VERSION ""

NS_ :

BS_:

BU_: PowertrainControlModule AtmosphericSensor SafetyRestraintSystem2 Aftertreatment_2_GasOutlet Aftertreatment_2_GasIntake DieselParticulateFilterControl Turbocharger SafetyRestraintSystem1 CabDisplay2 Aftertreatment_1_GasOutlet Aftertreatment_1_GasIntake OnBoardDataLogger OffBoardDiagnosticTool2 OffBoardDiagnosticTool1 FileServer ParkingBrakeController SeatController2 FanDriveController SteeringColumnUnit CommunicationUnitRadio CommunicationUnitSatellite CommunicationUnitCellular PropulsionBatteryCharger ChassisController2 ChassisController1 EngineValveControl AuxiliaryHeater2 AuxiliaryHeater1 ClutchUnit RampControl InformationSystem1 SuspensionSystemController2 OilSensor VehicleDynamicStability ExhaustEmissionController TransmissionDisplay2 TransmissionDisplay1 ClimateControl2 WaterPumpController RearAxleSteeringController LightingOperatorControl SeatController1 IgnitionController2 IgnitionController1 TirePressureController CabController2 CabController1 PneumaticSystemController SuspensionSystemController1 HydraulicPumpController EnduranceBrakingSystem RetarderExhaustEngine2 OnBoardDiagnosticUnit HeadwayController RetarderExhaustEngine1 CabDisplay1 ManagementComputer VirtualTerminal OffVehicleGateway PowerTakeOffFront HitchControl AuxiliaryValveControl BodyController TractorTrailerBridge1 StarterSystem ElectricalSystem VehicleSecurity VehicleNavigation AerodynamicControl ElectricalChargingSystem ClimateControl1 TripRecorder InstrumentCluster SuspensionDriveAxle2 SuspensionDriveAxle1 SuspensionSteerAxle SteeringController FuelSystem CruiseControl RetarderDriveline RetarderEngine BrakesDriveAxle2 BrakesDriveAxle1 BrakesSystemController BrakesSteerAxle AxleDrive2 AxleDrive1 AxleSteering PowerTakeOff ShiftConsoleSecondary ShiftConsolePrimary Transmission2 Transmission1 Engine2 Engine1

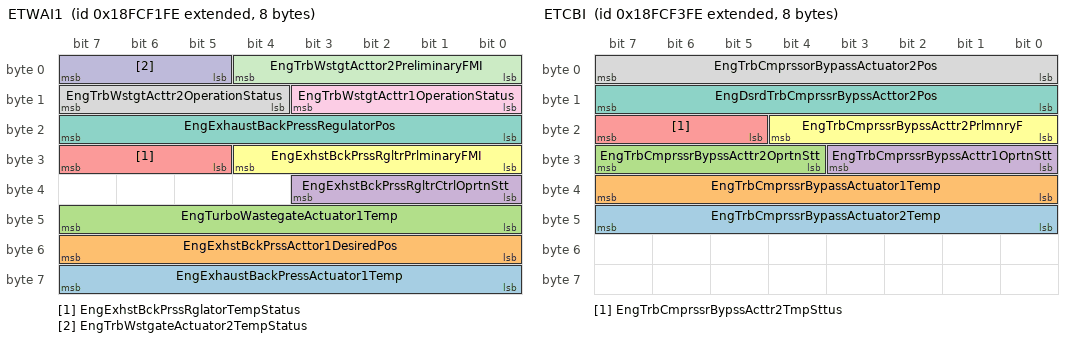
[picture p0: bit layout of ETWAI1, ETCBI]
BO_ 2566713854 ETWAI1: 8 Vector__XXX
 SG_ EngExhaustBackPressActuator1Temp : 56|8@1+ (1,-40) [-40|210] "°C" Vector__XXX
 SG_ EngExhstBckPrssActtor1DesiredPos : 48|8@1+ (0.4,0) [0|100] "%" Vector__XXX
 SG_ EngTurboWastegateActuator1Temp : 40|8@1+ (1,-40) [-40|210] "°C" Vector__XXX
 SG_ EngExhstBckPrssRgltrCtrlOprtnStt : 32|4@1+ (1,0) [0|15] "" Vector__XXX
 SG_ EngExhstBckPrssRglatorTempStatus : 29|3@1+ (1,0) [0|7] "" Vector__XXX
 SG_ EngExhstBckPrssRgltrPrlminaryFMI : 24|5@1+ (1,0) [0|31] "" Vector__XXX
 SG_ EngExhaustBackPressRegulatorPos : 16|8@1+ (0.4,0) [0|100] "%" Vector__XXX
 SG_ EngTrbWstgtActtr2OperationStatus : 12|4@1+ (1,0) [0|15] "" Vector__XXX
 SG_ EngTrbWstgtActtr1OperationStatus : 8|4@1+ (1,0) [0|15] "" Vector__XXX
 SG_ EngTrbWstgateActuator2TempStatus : 5|3@1+ (1,0) [0|7] "" Vector__XXX
 SG_ EngTrbWstgtActtor2PreliminaryFMI : 0|5@1+ (1,0) [0|31] "" Vector__XXX

BO_ 2566714366 ETCBI: 8 Vector__XXX
 SG_ EngTrbCmprssrBypassActuator2Temp : 40|8@1+ (1,-40) [-40|210] "°C" Vector__XXX
 SG_ EngTrbCmprssrBypassActuator1Temp : 32|8@1+ (1,-40) [-40|210] "°C" Vector__XXX
 SG_ EngTrbCmprssrBypssActtr2OprtnStt : 28|4@1+ (1,0) [0|15] "" Vector__XXX
 SG_ EngTrbCmprssrBypssActtr1OprtnStt : 24|4@1+ (1,0) [0|15] "" Vector__XXX
 SG_ EngTrbCmprssrBypssActtr2TmpSttus : 21|3@1+ (1,0) [0|7] "" Vector__XXX
 SG_ EngTrbCmprssrBypssActtr2PrlmnryF : 16|5@1+ (1,0) [0|31] "" Vector__XXX
 SG_ EngDsrdTrbCmprssrBypssActtor2Pos : 8|8@1+ (0.4,0) [0|100] "%" Vector__XXX
 SG_ EngTrbCmprssorBypassActuator2Pos : 0|8@1+ (0.4,0) [0|100] "%" Vector__XXX

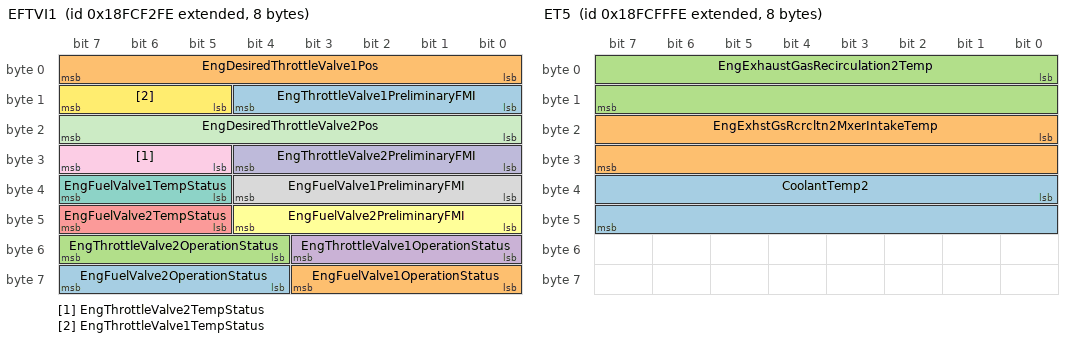
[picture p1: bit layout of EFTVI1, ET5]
BO_ 2566714110 EFTVI1: 8 Vector__XXX
 SG_ EngFuelValve2OperationStatus : 60|4@1+ (1,0) [0|15] "" Vector__XXX
 SG_ EngFuelValve1OperationStatus : 56|4@1+ (1,0) [0|15] "" Vector__XXX
 SG_ EngThrottleValve2OperationStatus : 52|4@1+ (1,0) [0|15] "" Vector__XXX
 SG_ EngThrottleValve1OperationStatus : 48|4@1+ (1,0) [0|15] "" Vector__XXX
 SG_ EngFuelValve2TempStatus : 45|3@1+ (1,0) [0|7] "" Vector__XXX
 SG_ EngFuelValve2PreliminaryFMI : 40|5@1+ (1,0) [0|31] "" Vector__XXX
 SG_ EngFuelValve1TempStatus : 37|3@1+ (1,0) [0|7] "" Vector__XXX
 SG_ EngFuelValve1PreliminaryFMI : 32|5@1+ (1,0) [0|31] "" Vector__XXX
 SG_ EngThrottleValve2TempStatus : 29|3@1+ (1,0) [0|7] "" Vector__XXX
 SG_ EngThrottleValve2PreliminaryFMI : 24|5@1+ (1,0) [0|31] "" Vector__XXX
 SG_ EngDesiredThrottleValve2Pos : 16|8@1+ (0.4,0) [0|100] "%" Vector__XXX
 SG_ EngThrottleValve1TempStatus : 13|3@1+ (1,0) [0|7] "" Vector__XXX
 SG_ EngThrottleValve1PreliminaryFMI : 8|5@1+ (1,0) [0|31] "" Vector__XXX
 SG_ EngDesiredThrottleValve1Pos : 0|8@1+ (0.4,0) [0|100] "%" Vector__XXX

BO_ 2566717438 ET5: 8 Vector__XXX
 SG_ CoolantTemp2 : 32|16@1+ (0.03125,-273) [-273|1734.96875] "°C" Vector__XXX
 SG_ EngExhstGsRcrcltn2MxerIntakeTemp : 16|16@1+ (0.03125,-273) [-273|1734.96875] "°C" Vector__XXX
 SG_ EngExhaustGasRecirculation2Temp : 0|16@1+ (0.03125,-273) [-273|1734.96875] "°C" Vector__XXX

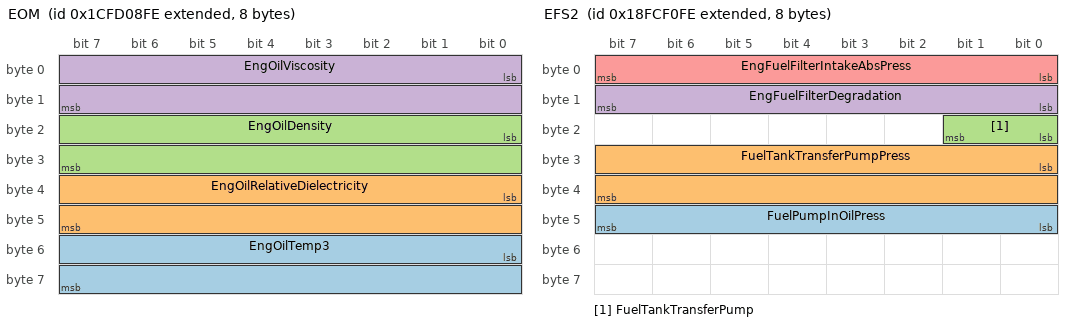
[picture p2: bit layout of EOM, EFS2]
BO_ 2633828606 EOM: 8 Vector__XXX
 SG_ EngOilTemp3 : 48|16@1+ (0.03125,-273) [-273|1734.96875] "°C" Vector__XXX
 SG_ EngOilRelativeDielectricity : 32|16@1+ (0.0001220703125,0) [0|7.8436279296875] "" Vector__XXX
 SG_ EngOilDensity : 16|16@1+ (3.052E-005,0) [0|1.9610626] "g/cc" Vector__XXX
 SG_ EngOilViscosity : 0|16@1+ (0.015625,0) [0|1003.984375] "cP" Vector__XXX

BO_ 2499607550 EMAP: 8 Vector__XXX
 SG_ EngExhstMnfldBnk2FlwBlncVlvActtr : 16|16@1+ (0.0025,0) [0|160.6375] "%" Vector__XXX
 SG_ EngExhstMnfldBnk1FlwBlncVlvActtr : 0|16@1+ (0.0025,0) [0|160.6375] "%" Vector__XXX

BO_ 2633825534 EMAC: 8 Vector__XXX
 SG_ EngExhstMnfldBnk2FlwBlncVlvActtr : 16|16@1+ (0.0025,0) [0|160.6375] "%" Vector__XXX
 SG_ EngExhstMnfldBnk1FlwBlncVlvActtr : 0|16@1+ (0.0025,0) [0|160.6375] "%" Vector__XXX

BO_ 2365400574 EJM9: 8 Vector__XXX
 SG_ Joystick9Button13PressedStatus : 62|2@1+ (1,0) [0|3] "" Vector__XXX
 SG_ Joystick9Button14PressedStatus : 60|2@1+ (1,0) [0|3] "" Vector__XXX
 SG_ Joystick9Button15PressedStatus : 58|2@1+ (1,0) [0|3] "" Vector__XXX
 SG_ Joystick9Button16PressedStatus : 56|2@1+ (1,0) [0|3] "" Vector__XXX
 SG_ Jystick9GripXAxisDetentPosStatus : 54|2@1+ (1,0) [0|3] "" Vector__XXX
 SG_ Jystick9GripYAxisDetentPosStatus : 52|2@1+ (1,0) [0|3] "" Vector__XXX
 SG_ Jystick9ThetaAxisDetentPosStatus : 50|2@1+ (1,0) [0|3] "" Vector__XXX
 SG_ Joystick9ThetaAxisPos : 38|10@1+ (0.1,0) [0|102] "%" Vector__XXX
 SG_ Jystck9ThtAxsClckwsPstvPosStatus : 36|2@1+ (1,0) [0|3] "" Vector__XXX
 SG_ Jystck9ThtAxsCntrClckwsNgtvPsStt : 34|2@1+ (1,0) [0|3] "" Vector__XXX
 SG_ Jystck9ThetaAxisNeutralPosStatus : 32|2@1+ (1,0) [0|3] "" Vector__XXX
 SG_ Joystick9GripYAxisPos : 22|10@1+ (0.1,0) [0|102] "%" Vector__XXX
 SG_ Jystck9GrpYAxsLvrFrwrdPstvPsStts : 20|2@1+ (1,0) [0|3] "" Vector__XXX
 SG_ Jystck9GrpYAxsLvrBckNgtvPsStatus : 18|2@1+ (1,0) [0|3] "" Vector__XXX
 SG_ Jystck9GripYAxisNeutralPosStatus : 16|2@1+ (1,0) [0|3] "" Vector__XXX
 SG_ Joystick9GripXAxisPos : 6|10@1+ (0.1,0) [0|102] "%" Vector__XXX
 SG_ Jystck9GrpXAxsLvrRghtPstvPsSttus : 4|2@1+ (1,0) [0|3] "" Vector__XXX
 SG_ Jystck9GrpXAxsLvrLftNgtvPsStatus : 2|2@1+ (1,0) [0|3] "" Vector__XXX
 SG_ Jystck9GripXAxisNeutralPosStatus : 0|2@1+ (1,0) [0|3] "" Vector__XXX

BO_ 2365401086 EJM8: 8 Vector__XXX
 SG_ Joystick8Button13PressedStatus : 62|2@1+ (1,0) [0|3] "" Vector__XXX
 SG_ Joystick8Button14PressedStatus : 60|2@1+ (1,0) [0|3] "" Vector__XXX
 SG_ Joystick8Button15PressedStatus : 58|2@1+ (1,0) [0|3] "" Vector__XXX
 SG_ Joystick8Button16PressedStatus : 56|2@1+ (1,0) [0|3] "" Vector__XXX
 SG_ Jystick8GripXAxisDetentPosStatus : 54|2@1+ (1,0) [0|3] "" Vector__XXX
 SG_ Jystick8GripYAxisDetentPosStatus : 52|2@1+ (1,0) [0|3] "" Vector__XXX
 SG_ Jystick8ThetaAxisDetentPosStatus : 50|2@1+ (1,0) [0|3] "" Vector__XXX
 SG_ Joystick8ThetaAxisPos : 38|10@1+ (0.1,0) [0|102] "%" Vector__XXX
 SG_ Jystck8ThtAxsClckwsPstvPosStatus : 36|2@1+ (1,0) [0|3] "" Vector__XXX
 SG_ Jystck8ThtAxsCntrClckwsNgtvPsStt : 34|2@1+ (1,0) [0|3] "" Vector__XXX
 SG_ Jystck8ThetaAxisNeutralPosStatus : 32|2@1+ (1,0) [0|3] "" Vector__XXX
 SG_ Joystick8GripYAxisPos : 22|10@1+ (0.1,0) [0|102] "%" Vector__XXX
 SG_ Jystck8GrpYAxsLvrFrwrdPstvPsStts : 20|2@1+ (1,0) [0|3] "" Vector__XXX
 SG_ Jystck8GrpYAxsLvrBckNgtvPsStatus : 18|2@1+ (1,0) [0|3] "" Vector__XXX
 SG_ Jystck8GripYAxisNeutralPosStatus : 16|2@1+ (1,0) [0|3] "" Vector__XXX
 SG_ Joystick8GripXAxisPos : 6|10@1+ (0.1,0) [0|102] "%" Vector__XXX
 SG_ Jystck8GrpXAxsLvrRghtPstvPsSttus : 4|2@1+ (1,0) [0|3] "" Vector__XXX
 SG_ Jystck8GrpXAxsLvrLftNgtvPsStatus : 2|2@1+ (1,0) [0|3] "" Vector__XXX
 SG_ Jystck8GripXAxisNeutralPosStatus : 0|2@1+ (1,0) [0|3] "" Vector__XXX

BO_ 2365401598 EJM7: 8 Vector__XXX
 SG_ Joystick7Button13PressedStatus : 62|2@1+ (1,0) [0|3] "" Vector__XXX
 SG_ Joystick7Button14PressedStatus : 60|2@1+ (1,0) [0|3] "" Vector__XXX
 SG_ Joystick7Button15PressedStatus : 58|2@1+ (1,0) [0|3] "" Vector__XXX
 SG_ Joystick7Button16PressedStatus : 56|2@1+ (1,0) [0|3] "" Vector__XXX
 SG_ Jystick7GripXAxisDetentPosStatus : 54|2@1+ (1,0) [0|3] "" Vector__XXX
 SG_ Jystick7GripYAxisDetentPosStatus : 52|2@1+ (1,0) [0|3] "" Vector__XXX
 SG_ Jystick7ThetaAxisDetentPosStatus : 50|2@1+ (1,0) [0|3] "" Vector__XXX
 SG_ Joystick7ThetaAxisPos : 38|10@1+ (0.1,0) [0|102] "%" Vector__XXX
 SG_ Jystck7ThtAxsClckwsPstvPosStatus : 36|2@1+ (1,0) [0|3] "" Vector__XXX
 SG_ Jystck7ThtAxsCntrClckwsNgtvPsStt : 34|2@1+ (1,0) [0|3] "" Vector__XXX
 SG_ Jystck7ThetaAxisNeutralPosStatus : 32|2@1+ (1,0) [0|3] "" Vector__XXX
 SG_ Joystick7GripYAxisPos : 22|10@1+ (0.1,0) [0|102] "%" Vector__XXX
 SG_ Jystck7GrpYAxsLvrFrwrdPstvPsStts : 20|2@1+ (1,0) [0|3] "" Vector__XXX
 SG_ Jystck7GrpYAxsLvrBckNgtvPsStatus : 18|2@1+ (1,0) [0|3] "" Vector__XXX
 SG_ Jystck7GripYAxisNeutralPosStatus : 16|2@1+ (1,0) [0|3] "" Vector__XXX
 SG_ Joystick7GripXAxisPos : 6|10@1+ (0.1,0) [0|102] "%" Vector__XXX
 SG_ Jystck7GrpXAxsLvrRghtPstvPsSttus : 4|2@1+ (1,0) [0|3] "" Vector__XXX
 SG_ Jystck7GrpXAxsLvrLftNgtvPsStatus : 2|2@1+ (1,0) [0|3] "" Vector__XXX
 SG_ Jystck7GripXAxisNeutralPosStatus : 0|2@1+ (1,0) [0|3] "" Vector__XXX

BO_ 2365402110 EJM6: 8 Vector__XXX
 SG_ Joystick6Button13PressedStatus : 62|2@1+ (1,0) [0|3] "" Vector__XXX
 SG_ Joystick6Button14PressedStatus : 60|2@1+ (1,0) [0|3] "" Vector__XXX
 SG_ Joystick6Button15PressedStatus : 58|2@1+ (1,0) [0|3] "" Vector__XXX
 SG_ Joystick6Button16PressedStatus : 56|2@1+ (1,0) [0|3] "" Vector__XXX
 SG_ Jystick6GripXAxisDetentPosStatus : 54|2@1+ (1,0) [0|3] "" Vector__XXX
 SG_ Jystick6GripYAxisDetentPosStatus : 52|2@1+ (1,0) [0|3] "" Vector__XXX
 SG_ Jystick6ThetaAxisDetentPosStatus : 50|2@1+ (1,0) [0|3] "" Vector__XXX
 SG_ Joystick6ThetaAxisPos : 38|10@1+ (0.1,0) [0|102] "%" Vector__XXX
 SG_ Jystck6ThtAxsClckwsPstvPosStatus : 36|2@1+ (1,0) [0|3] "" Vector__XXX
 SG_ Jystck6ThtAxsCntrClckwsNgtvPsStt : 34|2@1+ (1,0) [0|3] "" Vector__XXX
 SG_ Jystck6ThetaAxisNeutralPosStatus : 32|2@1+ (1,0) [0|3] "" Vector__XXX
 SG_ Joystick6GripYAxisPos : 22|10@1+ (0.1,0) [0|102] "%" Vector__XXX
 SG_ Jystck6GrpYAxsLvrFrwrdPstvPsStts : 20|2@1+ (1,0) [0|3] "" Vector__XXX
 SG_ Jystck6GrpYAxsLvrBckNgtvPsStatus : 18|2@1+ (1,0) [0|3] "" Vector__XXX
 SG_ Jystck6GripYAxisNeutralPosStatus : 16|2@1+ (1,0) [0|3] "" Vector__XXX
 SG_ Joystick6GripXAxisPos : 6|10@1+ (0.1,0) [0|102] "%" Vector__XXX
 SG_ Jystck6GrpXAxsLvrRghtPstvPsSttus : 4|2@1+ (1,0) [0|3] "" Vector__XXX
 SG_ Jystck6GrpXAxsLvrLftNgtvPsStatus : 2|2@1+ (1,0) [0|3] "" Vector__XXX
 SG_ Jystck6GripXAxisNeutralPosStatus : 0|2@1+ (1,0) [0|3] "" Vector__XXX

BO_ 2365402622 EJM5: 8 Vector__XXX
 SG_ Joystick5Button13PressedStatus : 62|2@1+ (1,0) [0|3] "" Vector__XXX
 SG_ Joystick5Button14PressedStatus : 60|2@1+ (1,0) [0|3] "" Vector__XXX
 SG_ Joystick5Button15PressedStatus : 58|2@1+ (1,0) [0|3] "" Vector__XXX
 SG_ Joystick5Button16PressedStatus : 56|2@1+ (1,0) [0|3] "" Vector__XXX
 SG_ Jystick5GripXAxisDetentPosStatus : 54|2@1+ (1,0) [0|3] "" Vector__XXX
 SG_ Jystick5GripYAxisDetentPosStatus : 52|2@1+ (1,0) [0|3] "" Vector__XXX
 SG_ Jystick5ThetaAxisDetentPosStatus : 50|2@1+ (1,0) [0|3] "" Vector__XXX
 SG_ Joystick5ThetaAxisPos : 38|10@1+ (0.1,0) [0|102] "%" Vector__XXX
 SG_ Jystck5ThtAxsClckwsPstvPosStatus : 36|2@1+ (1,0) [0|3] "" Vector__XXX
 SG_ Jystck5ThtAxsCntrClckwsNgtvPsStt : 34|2@1+ (1,0) [0|3] "" Vector__XXX
 SG_ Jystck5ThetaAxisNeutralPosStatus : 32|2@1+ (1,0) [0|3] "" Vector__XXX
 SG_ Joystick5GripYAxisPos : 22|10@1+ (0.1,0) [0|102] "%" Vector__XXX
 SG_ Jystck5GrpYAxsLvrFrwrdPstvPsStts : 20|2@1+ (1,0) [0|3] "" Vector__XXX
 SG_ Jystck5GrpYAxsLvrBckNgtvPsStatus : 18|2@1+ (1,0) [0|3] "" Vector__XXX
 SG_ Jystck5GripYAxisNeutralPosStatus : 16|2@1+ (1,0) [0|3] "" Vector__XXX
 SG_ Joystick5GripXAxisPos : 6|10@1+ (0.1,0) [0|102] "%" Vector__XXX
 SG_ Jystck5GrpXAxsLvrRghtPstvPsSttus : 4|2@1+ (1,0) [0|3] "" Vector__XXX
 SG_ Jystck5GrpXAxsLvrLftNgtvPsStatus : 2|2@1+ (1,0) [0|3] "" Vector__XXX
 SG_ Jystck5GripXAxisNeutralPosStatus : 0|2@1+ (1,0) [0|3] "" Vector__XXX

BO_ 2365403134 EJM4: 8 Vector__XXX
 SG_ Joystick4Button13PressedStatus : 62|2@1+ (1,0) [0|3] "" Vector__XXX
 SG_ Joystick4Button14PressedStatus : 60|2@1+ (1,0) [0|3] "" Vector__XXX
 SG_ Joystick4Button15PressedStatus : 58|2@1+ (1,0) [0|3] "" Vector__XXX
 SG_ Joystick4Button16PressedStatus : 56|2@1+ (1,0) [0|3] "" Vector__XXX
 SG_ Jystick4GripXAxisDetentPosStatus : 54|2@1+ (1,0) [0|3] "" Vector__XXX
 SG_ Jystick4GripYAxisDetentPosStatus : 52|2@1+ (1,0) [0|3] "" Vector__XXX
 SG_ Jystick4ThetaAxisDetentPosStatus : 50|2@1+ (1,0) [0|3] "" Vector__XXX
 SG_ Joystick4ThetaAxisPos : 38|10@1+ (0.1,0) [0|102] "%" Vector__XXX
 SG_ Jystck4ThtAxsClckwsPstvPosStatus : 36|2@1+ (1,0) [0|3] "" Vector__XXX
 SG_ Jystck4ThtAxsCntrClckwsNgtvPsStt : 34|2@1+ (1,0) [0|3] "" Vector__XXX
 SG_ Jystck4ThetaAxisNeutralPosStatus : 32|2@1+ (1,0) [0|3] "" Vector__XXX
 SG_ Joystick4GripYAxisPos : 22|10@1+ (0.1,0) [0|102] "%" Vector__XXX
 SG_ Jystck4GrpYAxsLvrFrwrdPstvPsStts : 20|2@1+ (1,0) [0|3] "" Vector__XXX
 SG_ Jystck4GrpYAxsLvrBckNgtvPsStatus : 18|2@1+ (1,0) [0|3] "" Vector__XXX
 SG_ Jystck4GripYAxisNeutralPosStatus : 16|2@1+ (1,0) [0|3] "" Vector__XXX
 SG_ Joystick4GripXAxisPos : 6|10@1+ (0.1,0) [0|102] "%" Vector__XXX
 SG_ Jystck4GrpXAxsLvrRghtPstvPsSttus : 4|2@1+ (1,0) [0|3] "" Vector__XXX
 SG_ Jystck4GrpXAxsLvrLftNgtvPsStatus : 2|2@1+ (1,0) [0|3] "" Vector__XXX
 SG_ Jystck4GripXAxisNeutralPosStatus : 0|2@1+ (1,0) [0|3] "" Vector__XXX

BO_ 2365400062 EJM10: 8 Vector__XXX
 SG_ Joystick10Button13PressedStatus : 62|2@1+ (1,0) [0|3] "" Vector__XXX
 SG_ Joystick10Button14PressedStatus : 60|2@1+ (1,0) [0|3] "" Vector__XXX
 SG_ Joystick10Button15PressedStatus : 58|2@1+ (1,0) [0|3] "" Vector__XXX
 SG_ Joystick10Button16PressedStatus : 56|2@1+ (1,0) [0|3] "" Vector__XXX
 SG_ Jystck10GripXAxisDetentPosStatus : 54|2@1+ (1,0) [0|3] "" Vector__XXX
 SG_ Jystck10GripYAxisDetentPosStatus : 52|2@1+ (1,0) [0|3] "" Vector__XXX
 SG_ Jystck10ThetaAxisDetentPosStatus : 50|2@1+ (1,0) [0|3] "" Vector__XXX
 SG_ Joystick10ThetaAxisPos : 38|10@1+ (0.1,0) [0|102] "%" Vector__XXX
 SG_ Jystck10ThtAxsClckwsPstvPsStatus : 36|2@1+ (1,0) [0|3] "" Vector__XXX
 SG_ Jystck10ThtAxsCntrClckwsNgtvPsSt : 34|2@1+ (1,0) [0|3] "" Vector__XXX
 SG_ Jystck10ThtaAxisNeutralPosStatus : 32|2@1+ (1,0) [0|3] "" Vector__XXX
 SG_ Joystick10GripYAxisPos : 22|10@1+ (0.1,0) [0|102] "%" Vector__XXX
 SG_ Jystck10GrpYAxsLvrFrwrdPstvPsStt : 20|2@1+ (1,0) [0|3] "" Vector__XXX
 SG_ Jystck10GrpYAxsLvrBckNgtvPsSttus : 18|2@1+ (1,0) [0|3] "" Vector__XXX
 SG_ Jystck10GrpYAxisNeutralPosStatus : 16|2@1+ (1,0) [0|3] "" Vector__XXX
 SG_ Joystick10GripXAxisPos : 6|10@1+ (0.1,0) [0|102] "%" Vector__XXX
 SG_ Jystck10GrpXAxsLvrRghtPstvPsStts : 4|2@1+ (1,0) [0|3] "" Vector__XXX
 SG_ Jystck10GrpXAxsLvrLftNgtvPsSttus : 2|2@1+ (1,0) [0|3] "" Vector__XXX
 SG_ Jystck10GrpXAxisNeutralPosStatus : 0|2@1+ (1,0) [0|3] "" Vector__XXX

BO_ 2566713598 EFS2: 8 Vector__XXX
 SG_ FuelPumpInOilPress : 40|8@1+ (4,0) [0|1000] "kPa" Vector__XXX
 SG_ FuelTankTransferPumpPress : 24|16@1+ (0.1,0) [0|6425.5] "kPa" Vector__XXX
 SG_ FuelTankTransferPump : 16|2@1+ (1,0) [0|3] "" Vector__XXX
 SG_ EngFuelFilterDegradation : 8|8@1+ (1,0) [0|250] "%" Vector__XXX
 SG_ EngFuelFilterIntakeAbsPress : 0|8@1+ (2,0) [0|500] "kPa" Vector__XXX

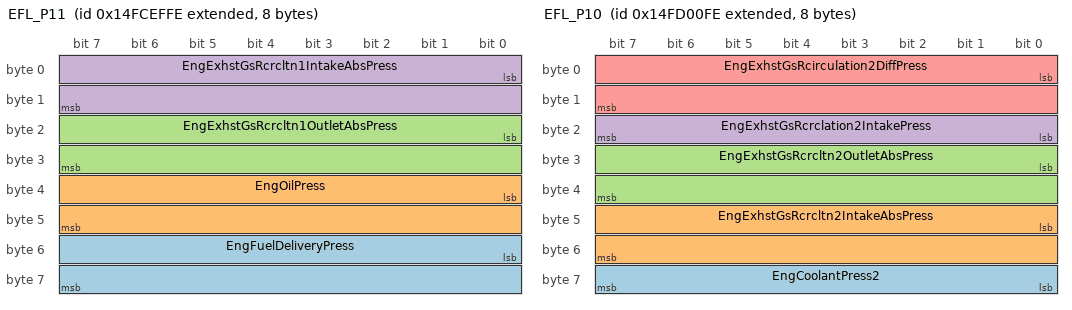
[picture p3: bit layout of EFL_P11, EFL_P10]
BO_ 2499604478 EFL_P11: 8 Vector__XXX
 SG_ EngFuelDeliveryPress : 48|16@1+ (0.1,0) [0|6425.5] "kPa" Vector__XXX
 SG_ EngOilPress : 32|16@1+ (0.1,0) [0|6425.5] "kPa" Vector__XXX
 SG_ EngExhstGsRcrcltn1OutletAbsPress : 16|16@1+ (0.1,0) [0|6425.5] "kPa" Vector__XXX
 SG_ EngExhstGsRcrcltn1IntakeAbsPress : 0|16@1+ (0.1,0) [0|6425.5] "kPa" Vector__XXX

BO_ 2499608830 EFL_P10: 8 Vector__XXX
 SG_ EngCoolantPress2 : 56|8@1+ (2,0) [0|500] "kPa" Vector__XXX
 SG_ EngExhstGsRcrcltn2IntakeAbsPress : 40|16@1+ (0.1,0) [0|6425.5] "kPa" Vector__XXX
 SG_ EngExhstGsRcrcltn2OutletAbsPress : 24|16@1+ (0.1,0) [0|6425.5] "kPa" Vector__XXX
 SG_ EngExhstGsRcrclation2IntakePress : 16|8@1+ (2,0) [0|500] "kPa" Vector__XXX
 SG_ EngExhstGsRcirculation2DiffPress : 0|16@1+ (0.0078125,-250) [-250|251.9921875] "kPa" Vector__XXX

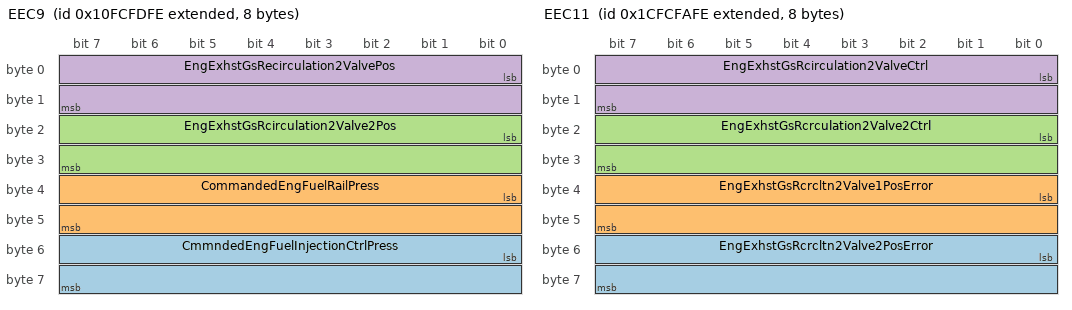
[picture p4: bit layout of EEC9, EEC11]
BO_ 2432499198 EEC9: 8 Vector__XXX
 SG_ CmmndedEngFuelInjectionCtrlPress : 48|16@1+ (0.00390625,0) [0|250.99609375] "MPa" Vector__XXX
 SG_ CommandedEngFuelRailPress : 32|16@1+ (0.00390625,0) [0|250.99609375] "MPa" Vector__XXX
 SG_ EngExhstGsRcirculation2Valve2Pos : 16|16@1+ (0.0025,0) [0|160.6375] "%" Vector__XXX
 SG_ EngExhstGsRecirculation2ValvePos : 0|16@1+ (0.0025,0) [0|160.6375] "%" Vector__XXX

BO_ 2633825022 EEC11: 8 Vector__XXX
 SG_ EngExhstGsRcrcltn2Valve2PosError : 48|16@1+ (0.004,-125) [-125|132.02] "%" Vector__XXX
 SG_ EngExhstGsRcrcltn2Valve1PosError : 32|16@1+ (0.004,-125) [-125|132.02] "%" Vector__XXX
 SG_ EngExhstGsRcrculation2Valve2Ctrl : 16|16@1+ (0.0025,0) [0|160.6375] "%" Vector__XXX
 SG_ EngExhstGsRcirculation2ValveCtrl : 0|16@1+ (0.0025,0) [0|160.6375] "%" Vector__XXX

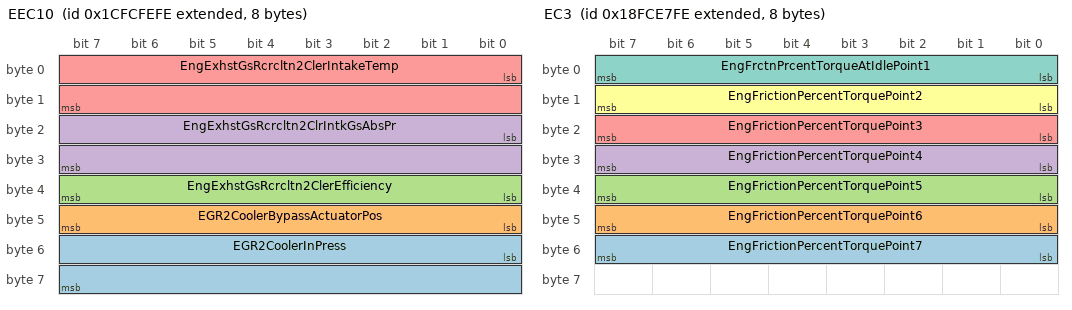
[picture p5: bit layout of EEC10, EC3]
BO_ 2633826046 EEC10: 8 Vector__XXX
 SG_ EGR2CoolerInPress : 48|16@1+ (5,0) [0|321275] "kPa" Vector__XXX
 SG_ EGR2CoolerBypassActuatorPos : 40|8@1+ (0.4,0) [0|100] "%" Vector__XXX
 SG_ EngExhstGsRcrcltn2ClerEfficiency : 32|8@1+ (0.4,0) [0|100] "%" Vector__XXX
 SG_ EngExhstGsRcrcltn2ClrIntkGsAbsPr : 16|16@1+ (0.5,0) [0|32127.5] "kPa" Vector__XXX
 SG_ EngExhstGsRcrcltn2ClerIntakeTemp : 0|16@1+ (0.03125,-273) [-273|1734.96875] "°C" Vector__XXX

BO_ 2566711294 EC3: 8 Vector__XXX
 SG_ EngFrictionPercentTorquePoint7 : 48|8@1+ (1,-125) [0|125] "%" Vector__XXX
 SG_ EngFrictionPercentTorquePoint6 : 40|8@1+ (1,-125) [0|125] "%" Vector__XXX
 SG_ EngFrictionPercentTorquePoint5 : 32|8@1+ (1,-125) [0|125] "%" Vector__XXX
 SG_ EngFrictionPercentTorquePoint4 : 24|8@1+ (1,-125) [0|125] "%" Vector__XXX
 SG_ EngFrictionPercentTorquePoint3 : 16|8@1+ (1,-125) [0|125] "%" Vector__XXX
 SG_ EngFrictionPercentTorquePoint2 : 8|8@1+ (1,-125) [0|125] "%" Vector__XXX
 SG_ EngFrctnPrcentTorqueAtIdlePoint1 : 0|8@1+ (1,-125) [0|125] "%" Vector__XXX

BO_ 2566749438 DPFC1: 8 Vector__XXX
 SG_ ActiveRegenInhibitedDueThresher : 62|2@1+ (1,0) [0|3] "" Vector__XXX
 SG_ ActiveRegenAvailabilityStatus : 3|2@1+ (1,0) [0|3] "" Vector__XXX
 SG_ DslPrtcltFltrActvRgnrtnInhbt5629 : 58|2@1+ (1,0) [0|3] "" Vector__XXX
 SG_ A1DPFCondNotMetForActiveRegen : 60|2@1+ (1,0) [0|3] "" Vector__XXX
 SG_ HydrocarbonDoserPurgingEnable : 56|2@1+ (1,0) [0|3] "" Vector__XXX
 SG_ DslPrtcltFltrActvRgnrtnFrcdSttus : 53|3@1+ (1,0) [0|7] "" Vector__XXX
 SG_ ExhaustSystemHighTempLampCmd : 50|3@1+ (1,0) [0|7] "" Vector__XXX
 SG_ DslPrtcltFltrAtmtcActvRgnrtnIntt : 48|2@1+ (1,0) [0|3] "" Vector__XXX
 SG_ DslPrtcltFltrActvRgnrtnInhbt3717 : 46|2@1+ (1,0) [0|3] "" Vector__XXX
 SG_ DslPrtcltFltrActvRgnrtnInhbtdDTE : 44|2@1+ (1,0) [0|3] "" Vector__XXX
 SG_ DslPrtcltFltrActvRgnrtnInhbt3715 : 42|2@1+ (1,0) [0|3] "" Vector__XXX
 SG_ DslPrtcltFltrActvRgnrtnInhbtdDTT : 40|2@1+ (1,0) [0|3] "" Vector__XXX
 SG_ DslPrtcltFltrActvRgnrtnInhbt3713 : 38|2@1+ (1,0) [0|3] "" Vector__XXX
 SG_ DslPrtcltFltrActvRgnrtnInhbt3712 : 36|2@1+ (1,0) [0|3] "" Vector__XXX
 SG_ DslPrtcltFltrActvRgnrtnInhbtdDTL : 34|2@1+ (1,0) [0|3] "" Vector__XXX
 SG_ DslPrtcltFltrActvRgnrtnInhbt3710 : 32|2@1+ (1,0) [0|3] "" Vector__XXX
 SG_ DslPrtcltFltrActvRgnrtnInhbtdDTV : 30|2@1+ (1,0) [0|3] "" Vector__XXX
 SG_ DslPrtcltFltrActvRgnrtnInhbtdDTO : 28|2@1+ (1,0) [0|3] "" Vector__XXX
 SG_ DslPrtcltFltrActvRgnrtnInhbtdDTA : 26|2@1+ (1,0) [0|3] "" Vector__XXX
 SG_ DslPrtcltFltrActvRgnrtnInhbtdDTP : 24|2@1+ (1,0) [0|3] "" Vector__XXX
 SG_ DslPrtcltFltrActvRgnrtnInhbtdDTS : 22|2@1+ (1,0) [0|3] "" Vector__XXX
 SG_ DslPrtcltFltrActvRgnrtnInhbtdDTC : 20|2@1+ (1,0) [0|3] "" Vector__XXX
 SG_ DslPrtcltFltrActvRgnrtnInhbtdDTI : 18|2@1+ (1,0) [0|3] "" Vector__XXX
 SG_ DslPrtcltFltrActvRgnrtnInhbtdStt : 16|2@1+ (1,0) [0|3] "" Vector__XXX
 SG_ AFTDPFSt : 12|3@1+ (1,0) [0|7] "" Vector__XXX
 SG_ AFTDPFActiveRegenSt : 10|2@1+ (1,0) [0|3] "" Vector__XXX
 SG_ AFTDPFPassiveRegenSt : 8|2@1+ (1,0) [0|3] "" Vector__XXX
 SG_ DieselParticulateFilterLampCmd : 0|3@1+ (1,0) [0|7] "" Vector__XXX

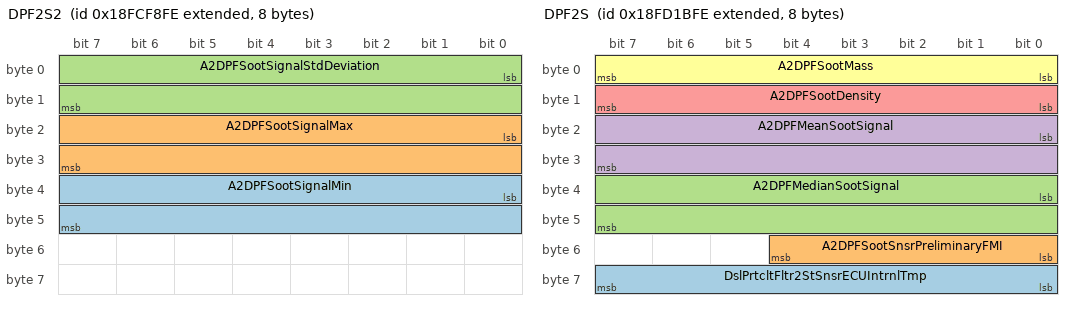
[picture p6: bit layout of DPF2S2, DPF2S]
BO_ 2566715646 DPF2S2: 8 Vector__XXX
 SG_ A2DPFSootSignalMin : 32|16@1+ (0.0025,0) [0|160.6375] "%" Vector__XXX
 SG_ A2DPFSootSignalMax : 16|16@1+ (0.0025,0) [0|160.6375] "%" Vector__XXX
 SG_ A2DPFSootSignalStdDeviation : 0|16@1+ (0.0025,0) [0|160.6375] "%" Vector__XXX

BO_ 2566724606 DPF2S: 8 Vector__XXX
 SG_ DslPrtcltFltr2StSnsrECUIntrnlTmp : 56|8@1+ (1,-40) [-40|210] "°C" Vector__XXX
 SG_ A2DPFSootSnsrPreliminaryFMI : 48|5@1+ (1,0) [0|31] "" Vector__XXX
 SG_ A2DPFMedianSootSignal : 32|16@1+ (0.0025,0) [0|160.6375] "%" Vector__XXX
 SG_ A2DPFMeanSootSignal : 16|16@1+ (0.0025,0) [0|160.6375] "%" Vector__XXX
 SG_ A2DPFSootDensity : 8|8@1+ (0.08,0) [0|20] "g/L" Vector__XXX
 SG_ A2DPFSootMass : 0|8@1+ (4,0) [0|1000] "g" Vector__XXX

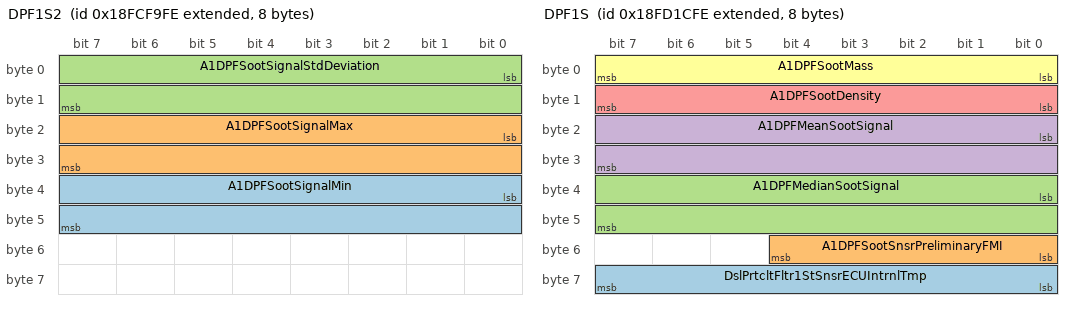
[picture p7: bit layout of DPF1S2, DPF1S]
BO_ 2566715902 DPF1S2: 8 Vector__XXX
 SG_ A1DPFSootSignalMin : 32|16@1+ (0.0025,0) [0|160.6375] "%" Vector__XXX
 SG_ A1DPFSootSignalMax : 16|16@1+ (0.0025,0) [0|160.6375] "%" Vector__XXX
 SG_ A1DPFSootSignalStdDeviation : 0|16@1+ (0.0025,0) [0|160.6375] "%" Vector__XXX

BO_ 2566724862 DPF1S: 8 Vector__XXX
 SG_ DslPrtcltFltr1StSnsrECUIntrnlTmp : 56|8@1+ (1,-40) [-40|210] "°C" Vector__XXX
 SG_ A1DPFSootSnsrPreliminaryFMI : 48|5@1+ (1,0) [0|31] "" Vector__XXX
 SG_ A1DPFMedianSootSignal : 32|16@1+ (0.0025,0) [0|160.6375] "%" Vector__XXX
 SG_ A1DPFMeanSootSignal : 16|16@1+ (0.0025,0) [0|160.6375] "%" Vector__XXX
 SG_ A1DPFSootDensity : 8|8@1+ (0.08,0) [0|20] "g/L" Vector__XXX
 SG_ A1DPFSootMass : 0|8@1+ (4,0) [0|1000] "g" Vector__XXX

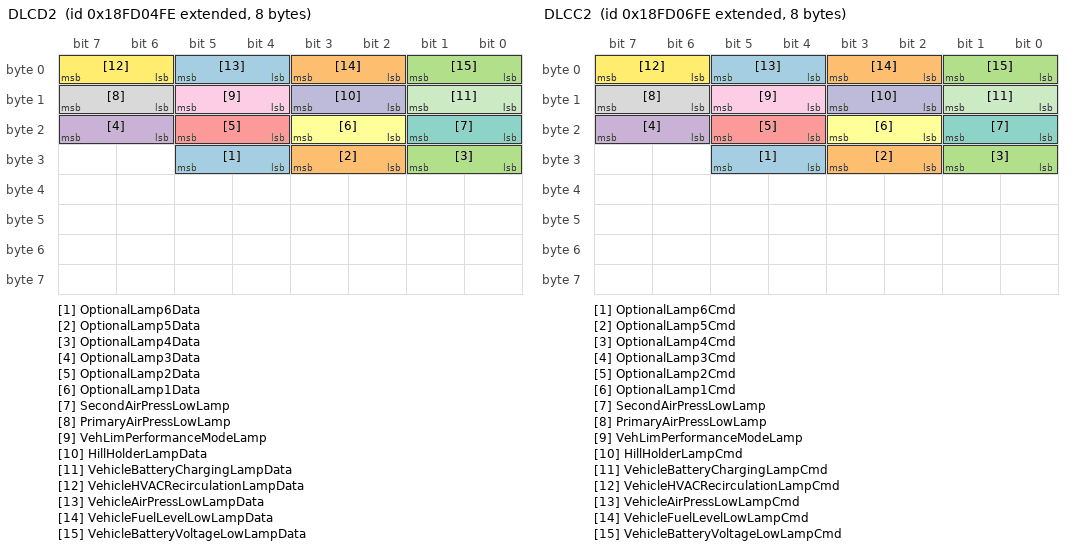
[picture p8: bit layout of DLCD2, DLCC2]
BO_ 2566718718 DLCD2: 8 Vector__XXX
 SG_ OptionalLamp6Data : 28|2@1+ (1,0) [0|3] "" Vector__XXX
 SG_ OptionalLamp5Data : 26|2@1+ (1,0) [0|3] "" Vector__XXX
 SG_ OptionalLamp4Data : 24|2@1+ (1,0) [0|3] "" Vector__XXX
 SG_ OptionalLamp3Data : 22|2@1+ (1,0) [0|3] "" Vector__XXX
 SG_ OptionalLamp2Data : 20|2@1+ (1,0) [0|3] "" Vector__XXX
 SG_ OptionalLamp1Data : 18|2@1+ (1,0) [0|3] "" Vector__XXX
 SG_ SecondAirPressLowLamp : 16|2@1+ (1,0) [0|3] "" Vector__XXX
 SG_ PrimaryAirPressLowLamp : 14|2@1+ (1,0) [0|3] "" Vector__XXX
 SG_ VehLimPerformanceModeLamp : 12|2@1+ (1,0) [0|3] "" Vector__XXX
 SG_ HillHolderLampData : 10|2@1+ (1,0) [0|3] "" Vector__XXX
 SG_ VehicleBatteryChargingLampData : 8|2@1+ (1,0) [0|3] "" Vector__XXX
 SG_ VehicleHVACRecirculationLampData : 6|2@1+ (1,0) [0|3] "" Vector__XXX
 SG_ VehicleAirPressLowLampData : 4|2@1+ (1,0) [0|3] "" Vector__XXX
 SG_ VehicleFuelLevelLowLampData : 2|2@1+ (1,0) [0|3] "" Vector__XXX
 SG_ VehicleBatteryVoltageLowLampData : 0|2@1+ (1,0) [0|3] "" Vector__XXX

BO_ 2566718974 DLCD1: 8 Vector__XXX
 SG_ EngSvcLamp : 52|2@1+ (1,0) [0|3] "" Vector__XXX
 SG_ EngAirShutoffLamp : 50|2@1+ (1,0) [0|3] "" Vector__XXX
 SG_ EngIntercoolerTempHiLamp : 48|2@1+ (1,0) [0|3] "" Vector__XXX
 SG_ EngFuelTempHiLamp : 46|2@1+ (1,0) [0|3] "" Vector__XXX
 SG_ EngOilTempHiLamp : 44|2@1+ (1,0) [0|3] "" Vector__XXX
 SG_ EngStopStartEnabledLamp : 42|2@1+ (1,0) [0|3] "" Vector__XXX
 SG_ EngStopStartAutoStartFailedLamp : 40|2@1+ (1,0) [0|3] "" Vector__XXX
 SG_ EngStopStartAutoStopActiveLamp : 38|2@1+ (1,0) [0|3] "" Vector__XXX
 SG_ VhclAcclerationRateLimitLampData : 34|2@1+ (1,0) [0|3] "" Vector__XXX
 SG_ EngSpeedVeryHighLampData : 32|2@1+ (1,0) [0|3] "" Vector__XXX
 SG_ EngSpeedHighLampData : 30|2@1+ (1,0) [0|3] "" Vector__XXX
 SG_ EngCtrlMdule3ReadyForUseLampData : 28|2@1+ (1,0) [0|3] "" Vector__XXX
 SG_ EngCtrlMdule2ReadyForUseLampData : 26|2@1+ (1,0) [0|3] "" Vector__XXX
 SG_ EngCtrlMdule1ReadyForUseLampData : 24|2@1+ (1,0) [0|3] "" Vector__XXX
 SG_ EngWaitToStartLampData : 62|2@1+ (1,0) [0|3] "" Vector__XXX
 SG_ EngFuelFilterRestrictedLampData : 22|2@1+ (1,0) [0|3] "" Vector__XXX
 SG_ EngAirFilterRestrictionLampData : 20|2@1+ (1,0) [0|3] "" Vector__XXX
 SG_ EngIdleManagementActiveLampData : 18|2@1+ (1,0) [0|3] "" Vector__XXX
 SG_ EngCoolantLevelLowLampData : 16|2@1+ (1,0) [0|3] "" Vector__XXX
 SG_ EngCoolantTempHighLampData : 14|2@1+ (1,0) [0|3] "" Vector__XXX
 SG_ EngOilPressLowLampData : 12|2@1+ (1,0) [0|3] "" Vector__XXX
 SG_ CmprssnBrkEnblSwtchIndctrLmpData : 10|2@1+ (1,0) [0|3] "" Vector__XXX
 SG_ EngBrakeActiveLampData : 8|2@1+ (1,0) [0|3] "" Vector__XXX
 SG_ OBDMalfunctionIndicatorLampData : 6|2@1+ (1,0) [0|3] "" Vector__XXX
 SG_ EngRedStopLampData : 4|2@1+ (1,0) [0|3] "" Vector__XXX
 SG_ EngAmberWarningLampData : 2|2@1+ (1,0) [0|3] "" Vector__XXX
 SG_ EngProtectLampData : 0|2@1+ (1,0) [0|3] "" Vector__XXX

BO_ 2566719230 DLCC2: 8 Vector__XXX
 SG_ OptionalLamp6Cmd : 28|2@1+ (1,0) [0|3] "" Vector__XXX
 SG_ OptionalLamp5Cmd : 26|2@1+ (1,0) [0|3] "" Vector__XXX
 SG_ OptionalLamp4Cmd : 24|2@1+ (1,0) [0|3] "" Vector__XXX
 SG_ OptionalLamp3Cmd : 22|2@1+ (1,0) [0|3] "" Vector__XXX
 SG_ OptionalLamp2Cmd : 20|2@1+ (1,0) [0|3] "" Vector__XXX
 SG_ OptionalLamp1Cmd : 18|2@1+ (1,0) [0|3] "" Vector__XXX
 SG_ SecondAirPressLowLamp : 16|2@1+ (1,0) [0|3] "" Vector__XXX
 SG_ PrimaryAirPressLowLamp : 14|2@1+ (1,0) [0|3] "" Vector__XXX
 SG_ VehLimPerformanceModeLamp : 12|2@1+ (1,0) [0|3] "" Vector__XXX
 SG_ HillHolderLampCmd : 10|2@1+ (1,0) [0|3] "" Vector__XXX
 SG_ VehicleBatteryChargingLampCmd : 8|2@1+ (1,0) [0|3] "" Vector__XXX
 SG_ VehicleHVACRecirculationLampCmd : 6|2@1+ (1,0) [0|3] "" Vector__XXX
 SG_ VehicleAirPressLowLampCmd : 4|2@1+ (1,0) [0|3] "" Vector__XXX
 SG_ VehicleFuelLevelLowLampCmd : 2|2@1+ (1,0) [0|3] "" Vector__XXX
 SG_ VehicleBatteryVoltageLowLampCmd : 0|2@1+ (1,0) [0|3] "" Vector__XXX

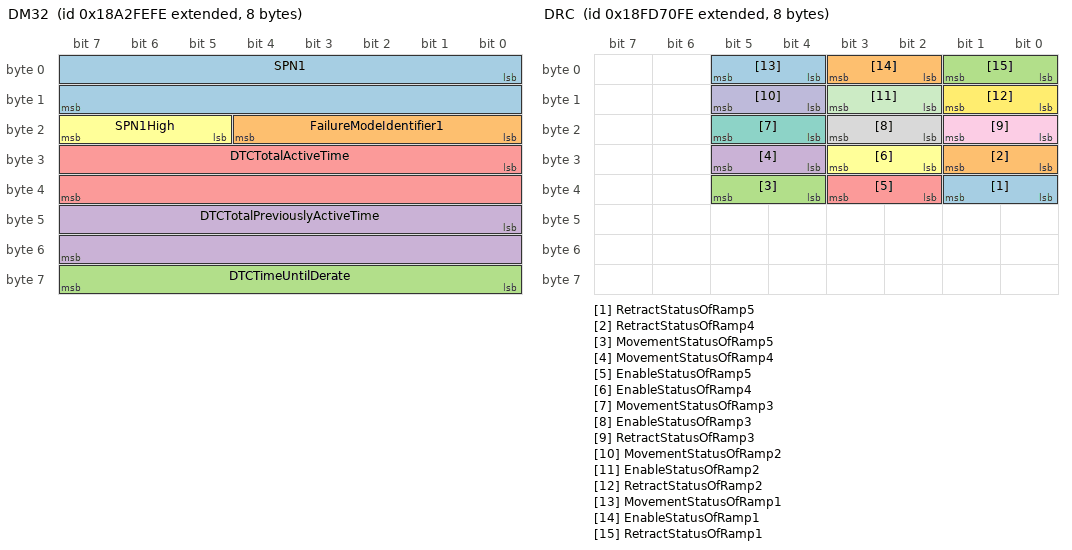
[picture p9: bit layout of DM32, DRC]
BO_ 2560818942 DM32: 8 Vector__XXX
 SG_ SPN1 : 0|16@1+ (1,0) [0|65536] "" Vector__XXX
 SG_ FailureModeIdentifier1 : 16|5@1+ (1,0) [0|0] "" Vector__XXX
 SG_ DTCTimeUntilDerate : 56|8@1+ (0.25,0) [0|62.5] "hr" Vector__XXX
 SG_ DTCTotalPreviouslyActiveTime : 40|16@1+ (0.2,0) [0|12851] "hr" Vector__XXX
 SG_ DTCTotalActiveTime : 24|16@1+ (0.2,0) [0|12851] "hr" Vector__XXX
 SG_ SPN1High : 21|3@1+ (1,0) [0|7] "" Vector__XXX

BO_ 2561212158 DISP1: 204 Vector__XXX
 SG_ TextDisplayIndex : 16|8@1+ (1,0) [0|200] "" Vector__XXX
 SG_ TextDisplayInstructions : 0|4@1+ (1,0) [0|15] "" Vector__XXX

BO_ 2566746366 DRC: 8 Vector__XXX
 SG_ RetractStatusOfRamp5 : 32|2@1+ (1,0) [0|3] "" Vector__XXX
 SG_ RetractStatusOfRamp4 : 24|2@1+ (1,0) [0|3] "" Vector__XXX
 SG_ MovementStatusOfRamp5 : 36|2@1+ (1,0) [0|3] "" Vector__XXX
 SG_ MovementStatusOfRamp4 : 28|2@1+ (1,0) [0|3] "" Vector__XXX
 SG_ EnableStatusOfRamp5 : 34|2@1+ (1,0) [0|3] "" Vector__XXX
 SG_ EnableStatusOfRamp4 : 26|2@1+ (1,0) [0|3] "" Vector__XXX
 SG_ MovementStatusOfRamp3 : 20|2@1+ (1,0) [0|3] "" Vector__XXX
 SG_ EnableStatusOfRamp3 : 18|2@1+ (1,0) [0|3] "" Vector__XXX
 SG_ RetractStatusOfRamp3 : 16|2@1+ (1,0) [0|3] "" Vector__XXX
 SG_ MovementStatusOfRamp2 : 12|2@1+ (1,0) [0|3] "" Vector__XXX
 SG_ EnableStatusOfRamp2 : 10|2@1+ (1,0) [0|3] "" Vector__XXX
 SG_ RetractStatusOfRamp2 : 8|2@1+ (1,0) [0|3] "" Vector__XXX
 SG_ MovementStatusOfRamp1 : 4|2@1+ (1,0) [0|3] "" Vector__XXX
 SG_ EnableStatusOfRamp1 : 2|2@1+ (1,0) [0|3] "" Vector__XXX
 SG_ RetractStatusOfRamp1 : 0|2@1+ (1,0) [0|3] "" Vector__XXX

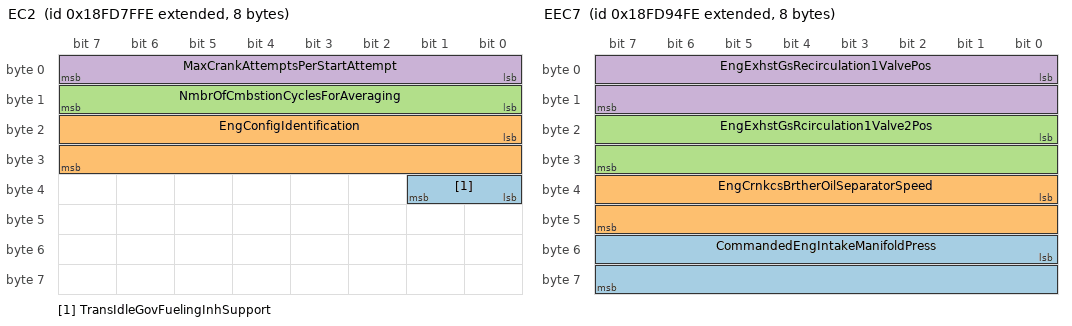
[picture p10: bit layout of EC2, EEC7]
BO_ 2566750206 EC2: 8 Vector__XXX
 SG_ TransIdleGovFuelingInhSupport : 32|2@1+ (1,0) [0|3] "" Vector__XXX
 SG_ EngConfigIdentification : 16|16@1+ (1,0) [0|64255] "ID" Vector__XXX
 SG_ NmbrOfCmbstionCyclesForAveraging : 8|8@1+ (1,0) [1|250] "" Vector__XXX
 SG_ MaxCrankAttemptsPerStartAttempt : 0|8@1+ (1,0) [0|250] "" Vector__XXX

BO_ 2566755582 EEC7: 8 Vector__XXX
 SG_ CommandedEngIntakeManifoldPress : 48|16@1+ (0.125,0) [0|8031.875] "kPa" Vector__XXX
 SG_ EngCrnkcsBrtherOilSeparatorSpeed : 32|16@1+ (1,0) [0|64255] "rpm" Vector__XXX
 SG_ EngExhstGsRcirculation1Valve2Pos : 16|16@1+ (0.0025,0) [0|160.6375] "%" Vector__XXX
 SG_ EngExhstGsRecirculation1ValvePos : 0|16@1+ (0.0025,0) [0|160.6375] "%" Vector__XXX

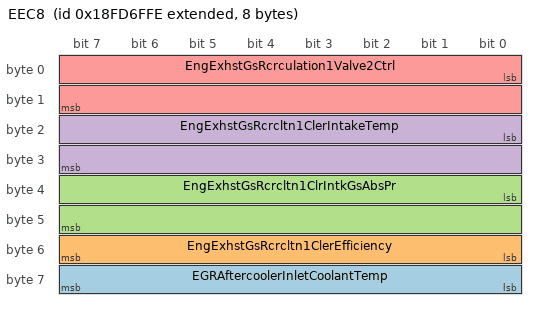
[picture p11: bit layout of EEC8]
BO_ 2566746110 EEC8: 8 Vector__XXX
 SG_ EGRAftercoolerInletCoolantTemp : 56|8@1+ (1,-40) [-40|210] "°C" Vector__XXX
 SG_ EngExhstGsRcrcltn1ClerEfficiency : 48|8@1+ (0.4,0) [0|100] "%" Vector__XXX
 SG_ EngExhstGsRcrcltn1ClrIntkGsAbsPr : 32|16@1+ (0.5,0) [0|32127.5] "kPa" Vector__XXX
 SG_ EngExhstGsRcrcltn1ClerIntakeTemp : 16|16@1+ (0.03125,-273) [-273|1734.96875] "°C" Vector__XXX
 SG_ EngExhstGsRcrculation1Valve2Ctrl : 0|16@1+ (0.0025,0) [0|160.6375] "%" Vector__XXX

CM_ BO_ 2566713854 "Engine Turbocharger Wastegate Actuator and Exhaust Back Pressure Regulator Information 1
This PG will be used to transmit the Engine Turbocharger Wastegate and Exhaust Back Pressure Regulator Information.";
CM_ SG_ 2566713854 EngExhaustBackPressActuator1Temp "Temperature of the Engine Exhaust Pressure Actuator 1 drive circuitry.  Temperature excursions may affect the torque output.";
CM_ SG_ 2566713854 EngExhstBckPrssActtor1DesiredPos "The requested position of the Engine Exhaust Pressure Actuator 1 by the engine ECU, where 0% represents fully closed and 100% represents fully open.

This is the position that the device is attempting to achieve.";
CM_ SG_ 2566713854 EngTurboWastegateActuator1Temp "Temperature of the Engine Turbocharger Wastegate Actuator 1 drive circuitry.  Temperature excursions may affect the torque output.";
CM_ SG_ 2566713854 EngExhstBckPrssRgltrCtrlOprtnStt "Used to identify the status of Engine Exhaust Pressure Regulator.
0000b = Normal
0001b = Alarm (fully operational but needs service)
0010b = Alarm High Severity (functional but transient performance may be reduced)
0011b = Derate Active (torque ...";
CM_ SG_ 2566713854 EngExhstBckPrssRglatorTempStatus "Used to identify the status of the Engine Exhaust Pressure Regulator (EPR) drive circuitry temperature. Temperature excursions may affect the torque output.
000b = High most severe
001b = High Least severe
010b = In Range
011b = Low Least severe
 ...";
CM_ SG_ 2566713854 EngExhstBckPrssRgltrPrlminaryFMI "Used to identify the applicable J1939-73 FMI detected in the Engine Exhaust Pressure Regulator (EPR) by the manufacturers software.  When there are multiple failures, the most severe is transmitted.
A value of 31 is sent to indicate that no failure ...";
CM_ SG_ 2566713854 EngExhaustBackPressRegulatorPos "The position of the Exhaust Pressure Regulator (EPR) in bank 1 expressed as a percentage of full travel.  One hundred percent means the regulator is fully closed, providing the maximum restriction to exhaust gas flow from the engine.  Zero percent ...";
CM_ SG_ 2566713854 EngTrbWstgtActtr2OperationStatus "Used to identify the status of Engine Turbocharger Wastegate Actuator 2.
0000b = Normal
0001b = Alarm (fully operational but needs service)
0010b = Alarm High Severity (functional but transient performance may be reduced)
0011b = Derate Active ...";
CM_ SG_ 2566713854 EngTrbWstgtActtr1OperationStatus "Used to identify the status of Engine Turbocharger Wastegate Actuator 1.
0000b = Normal
0001b = Alarm (fully operational but needs service)
0010b = Alarm High Severity (functional but transient performance may be reduced)
0011b = Derate Active ...";
CM_ SG_ 2566713854 EngTrbWstgateActuator2TempStatus "Used to identify the status of the Engine Turbocharger Wastegate Actuator 2 drive circuitry temperature.  Temperature excursions may affect the torque output.
000b = High most severe
001b = High Least severe
010b = In Range
011b = Low Least ...";
CM_ SG_ 2566713854 EngTrbWstgtActtor2PreliminaryFMI "Used to identify the applicable J1939-73 FMI detected in the Engine Turbocharger Wastegate Actuator 2 by the manufacturers software. When there is multiple failures, the most severe is transmitted.
A value of 31 is sent to indicate that no failure ...";
CM_ BO_ 2566714366 "Engine Turbocharger Compressor Bypass Information
This PG will contain the Engine Turbocharger Compressor Bypass information";
CM_ SG_ 2566714366 EngTrbCmprssrBypassActuator2Temp "Temperature of the Engine Turbocharger Compressor Bypass Actuator 2 drive circuitry.    Temperature excursions may affect the torque output.";
CM_ SG_ 2566714366 EngTrbCmprssrBypassActuator1Temp "Temperature of the Engine Turbocharger Compressor Bypass Actuator 1 drive circuitry.    Temperature excursions may affect the torque output.";
CM_ SG_ 2566714366 EngTrbCmprssrBypssActtr2OprtnStt "Used to identify the status of Engine Turbocharger Compressor Bypass Actuator 2.
0000b = Normal
0001b = Alarm (fully operational but needs service)
0010b = Alarm High Severity (functional but transient performance may be reduced)
0011b = Derate ...";
CM_ SG_ 2566714366 EngTrbCmprssrBypssActtr1OprtnStt "Used to identify the status of Engine Turbocharger Compressor Bypass Actuator 1.
0000b = Normal
0001b = Alarm (fully operational but needs service)
0010b = Alarm High Severity (functional but transient performance may be reduced)
0011b = Derate ...";
CM_ SG_ 2566714366 EngTrbCmprssrBypssActtr2TmpSttus "Used to identify the status of the Engine Turbocharger Compresssor Bypass Actuator 2 drive circuitry temperature.  Temperature excursions may affect the torque output.
000b = High most severe
001b = High Least severe
010b = In Range
011b = Low ...";
CM_ SG_ 2566714366 EngTrbCmprssrBypssActtr2PrlmnryF "Used to identify the applicable J1939-73 FMI detected in the Engine Turbocharger Compressor Bypass Actuator 1 by the manufacturers software.  When there is multiple failures, the most severe is transmitted.
A value of 31 is sent to indicate that no ...";
CM_ SG_ 2566714366 EngDsrdTrbCmprssrBypssActtor2Pos "The desired position of the Engine Turbocharger Compressor Bypass actuator 2 by the engine ECU, where 0% represents bypass fully closed and 100% represents bypass fully open.

This is the position that the device is attempting to achieve.";
CM_ SG_ 2566714366 EngTrbCmprssorBypassActuator2Pos "Measures the position of the turbocharger compressor bypass actuator 2, where 0% represents bypass fully closed and 100% represents bypass fully open. Typically, the compressor bypass is used to lower the compressor outlet pressure and/or intake ...";
CM_ BO_ 2566714110 "Engine Fuel/Throttle Valve Information 1
This PG will be used to transmit the Feedback information from the Engine Throttle and Fuel Actuator.";
CM_ SG_ 2566714110 EngFuelValve2OperationStatus "Used to identify the status of Engine Fuel Valve 2.
0000b = Normal
0001b = Alarm (fully operational but needs service)
0010b = Alarm High Severity (functional but transient performance may be reduced)
0011b = Derate Active (torque output reduced ...";
CM_ SG_ 2566714110 EngFuelValve1OperationStatus "Used to identify the status of Engine Fuel Valve 1.
0000b = Normal
0001b = Alarm (fully operational but needs service)
0010b = Alarm High Severity (functional but transient performance may be reduced)
0011b = Derate Active (torque output reduced ...";
CM_ SG_ 2566714110 EngThrottleValve2OperationStatus "Used to identify the status of engine throttle valve 2 (SPN 3673).
0000b = Normal
0001b = Alarm (fully operational but needs service)
0010b = Alarm High Severity (functional but transient performance may be reduced)
0011b = Derate Active (torque ...";
CM_ SG_ 2566714110 EngThrottleValve1OperationStatus "Used to identify the status of engine throttle valve 1 (SPN 51).
0000b = Normal
0001b = Alarm (fully operational but needs service)
0010b = Alarm High Severity (functional but transient performance may be reduced)
0011b = Derate Active (torque ...";
CM_ SG_ 2566714110 EngFuelValve2TempStatus "Used to identify the status of the Engine Fuel valve 2 drive circuitry temperature.  Temperature excursions may affect the torque output.
000b = High most severe
001b = High Least severe
010b = In Range
011b = Low Least severe
100b = Low Most ...";
CM_ SG_ 2566714110 EngFuelValve2PreliminaryFMI "Used to identify the applicable J1939-73 FMI detected in the Engine Fuel Valve 2 by the manufacturers software.  When there is multiple failures, the most severe is transmitted.
A value of 31 is sent to indicate that no failure has been detected or ...";
CM_ SG_ 2566714110 EngFuelValve1TempStatus "Used to identify the status of the Engine Fuel valve 1 drive circuitry temperature.  Temperature excursions may affect the torque output.
000b = High Most severe
001b = High Least severe
010b = In Range
011b = Low Least severe
100b = Low Most ...";
CM_ SG_ 2566714110 EngFuelValve1PreliminaryFMI "Used to identify the applicable J1939-73 FMI detected in the Engine Fuel Valve 1 by the manufacturers software. When there is multiple failures, the most severe is transmitted.
A value of 31 is sent to indicate that no failure has been detected or ...";
CM_ SG_ 2566714110 EngThrottleValve2TempStatus "Used to identify the status of the Engine throttle valve 2 (SPN 3673) drive circuitry temperature.  Temperature excursions may affect the torque output.
000b = High Most severe
001b = High Least severe
010b = In Range
011b = Low Least severe
 ...";
CM_ SG_ 2566714110 EngThrottleValve2PreliminaryFMI "Used to identify the applicable J1939-73 FMI detected in the engine throttle valve 2 (SPN 3673) by the manufacturers software.  When there is multiple failures, the most severe is transmitted.
A value of 31 is sent to indicate that no failure has ...";
CM_ SG_ 2566714110 EngDesiredThrottleValve2Pos "The desired position of the engine throttle valve 2 (SPN 3673) that is regulating the fluid, usually air/fuel mixture to the engine as commanded by the Engine Control Unit.  0% represents no supply and 100% is full supply.
This is the position that ...";
CM_ SG_ 2566714110 EngThrottleValve1TempStatus "Used to identify the status of the engine throttle valve 1 (SPN 51) drive circuitry temperature.  Temperature excursions may affect the torque output.
000b = High most severe
001b = High Least severe
010b = In Range
011b = Low Least severe
100b ...";
CM_ SG_ 2566714110 EngThrottleValve1PreliminaryFMI "Used to identify the applicable J1939-73 FMI detected in the engine throttle valve 1 (SPN 51) by the manufacturers software.  When there is multiple failures, the most severe is transmitted.
A value of 31 is sent to indicate that no failure has ...";
CM_ SG_ 2566714110 EngDesiredThrottleValve1Pos "The desired position of the Throttle valve 1 (SPN 51) that is regulating the fluid, usually air/fuel mixture to the engine as commanded by the Engine Control unit.  0% represents no supply and 100% is full supply.
This is the position that the ...";
CM_ BO_ 2566717438 "Engine Temperature 5
Engine related parameters";
CM_ SG_ 2566717438 CoolantTemp2 "Second temperature of liquid found in engine coolant system.

See SPN 4076 for alternate range and resolution.";
CM_ SG_ 2566717438 EngExhstGsRcrcltn2MxerIntakeTemp "The temperature of the EGR gas entering the intake of EGR2 system mixer.";
CM_ SG_ 2566717438 EngExhaustGasRecirculation2Temp "Temperature of Recirculated Exhaust Gas of EGR2";
CM_ BO_ 2633828606 "Engine oil message
Engine oil related parameters";
CM_ SG_ 2633828606 EngOilTemp3 "Temperature of the engine lubricant.

Note:  If there is only one engine oil temperature measurement, SPN 175 should be used. 

See also SPNs 175 and 1135 for additional engine oil temperature measurements.";
CM_ SG_ 2633828606 EngOilRelativeDielectricity "Engine oil relative dielectricity used to describe the engine oil quality.";
CM_ SG_ 2633828606 EngOilDensity "Density of the engine oil";
CM_ SG_ 2633828606 EngOilViscosity "Dynamic viscosity of the engine oil";
CM_ BO_ 2499607550 "Engine Manifold Actuator Position
Engine manifold actuator position parameters";
CM_ SG_ 2499607550 EngExhstMnfldBnk2FlwBlncVlvActtr "Actual percentage of maximum Engine Manifold Bank 2 Balance valve opening. 0% means valve is closed. 100% means maximum valve opening (full gas flow).";
CM_ SG_ 2499607550 EngExhstMnfldBnk1FlwBlncVlvActtr "Actual percentage of maximum Engine Exhaust Manifold Bank 1 Balance valve opening. 0% means valve is closed. 100% means maximum valve opening (full gas flow).";
CM_ BO_ 2633825534 "Engine Manifold Actuator Control
Engine manifold actuator control parameters.";
CM_ SG_ 2633825534 EngExhstMnfldBnk2FlwBlncVlvActtr "Commanded percentage of maximum Engine Ehaust Manifold Bank 2 Balance valve opening. 0% means valve is closed. 100% means maximum valve opening (full gas flow).";
CM_ SG_ 2633825534 EngExhstMnfldBnk1FlwBlncVlvActtr "Commanded percentage of maximum Engine Exhaust Manifold Bank 1 Balance valve opening. 0% means valve is closed. 100% means maximum valve opening (full gas flow).";
CM_ BO_ 2365400574 "Extended Joystick Message 9
Used to transfer information about the measured status of three additional axes of a joystick and switches of the joystick grip or handle.  The joystick axial motion information is available in the Basic Joystick ...";
CM_ SG_ 2365400574 Joystick9Button13PressedStatus "Reports when the joystick button has been pressed.

00b = Button not pressed
01b = Button pressed
10b = Error Indicator
11b = Not Available";
CM_ SG_ 2365400574 Joystick9Button14PressedStatus "Reports when the joystick button has been pressed.

00b = Button not pressed
01b = Button pressed
10b = Error Indicator
11b = Not Available";
CM_ SG_ 2365400574 Joystick9Button15PressedStatus "Reports when the joystick button has been pressed.

00b = Button not pressed
01b = Button pressed
10b = Error Indicator
11b = Not Available";
CM_ SG_ 2365400574 Joystick9Button16PressedStatus "Reports when the joystick button has been pressed.

00b = Button not pressed
01b = Button pressed
10b = Error Indicator
11b = Not Available";
CM_ SG_ 2365400574 Jystick9GripXAxisDetentPosStatus "Reports when the current joystick grip position is in the detent position for that axis of travel.

00b = Not in the Detent Position
01b = In the Detent Position
10b = Error Indicator
11b = Not Available";
CM_ SG_ 2365400574 Jystick9GripYAxisDetentPosStatus "Reports when the current joystick grip position is in the detent position for that axis of travel.

00b = Not in the Detent Position
01b = In the Detent Position
10b = Error Indicator
11b = Not Available";
CM_ SG_ 2365400574 Jystick9ThetaAxisDetentPosStatus "Reports when the current joystick position is in the detent position for that axis of travel.

00b = Not in the Detent Position
01b = In the Detent Position
10b = Error Indicator
11b = Not Available";
CM_ SG_ 2365400574 Joystick9ThetaAxisPos "The position of the joystick in the relative motion of travel from the neutral position.  Position value of 0 is Neutral and position value 1000 (100%) is the end of linear zone.  Value of 1022 indicates an error has occurred.";
CM_ SG_ 2365400574 Jystck9ThtAxsClckwsPstvPosStatus "Reports when the current joystick position is on the positive travel side (forward, right, clockwise, up) relative to the neutral position for that axis of travel.
00b = Not on Positive side of Neutral
01b = On positive side of Neutral
10b = ...";
CM_ SG_ 2365400574 Jystck9ThtAxsCntrClckwsNgtvPsStt "Reports when the current joystick position is on the negative travel side (back, left, counterclockwise, down) relative to the neutral position for that axis of travel.
00b = Not on negative side of Neutral
01b = On negative side of Neutral
10b = ...";
CM_ SG_ 2365400574 Jystck9ThetaAxisNeutralPosStatus "Reports when the current joystick position is in the neutral position for that axis of travel.  The neutral position measurement must be determined from some mechanism other than the axis position measurement device.
00b = Not in Neutral Position
 ...";
CM_ SG_ 2365400574 Joystick9GripYAxisPos "The position of the joystick grip in the relative motion of travel from the neutral position.  Position value of 0 is Neutral and position value 1000 (100%) is the end of linear zone.  Value of 1022 indicates an error has occurred.";
CM_ SG_ 2365400574 Jystck9GrpYAxsLvrFrwrdPstvPsStts "Reports when the current joystick grip position is on the positive travel side (forward, right, clockwise, up) relative to the neutral position for that axis of travel.
00b = Not on Positive side of Neutral
01b = On positive side of Neutral
10b = ...";
CM_ SG_ 2365400574 Jystck9GrpYAxsLvrBckNgtvPsStatus "Reports when the current joystick grip position is on the negative travel side (back, left, counterclockwise, down) relative to the neutral position for that axis of travel.
00b = Not on negative side of Neutral
01b = On negative side of Neutral
 ...";
CM_ SG_ 2365400574 Jystck9GripYAxisNeutralPosStatus "Reports when the current joystick grip position is in the neutral position for that axis of travel.  The neutral position measurement must be determined from some mechanism other than the axis position measurement device.
00b = Not in Neutral ...";
CM_ SG_ 2365400574 Joystick9GripXAxisPos "The position of the joystick grip in the relative motion of travel from the neutral position.  Position value of 0 is Neutral and position value 1000 (100%) is the end of linear zone.  Value of 1022 indicates an error has occurred.";
CM_ SG_ 2365400574 Jystck9GrpXAxsLvrRghtPstvPsSttus "Reports when the current joystick grip position is on the positive travel side (forward, right, clockwise, up) relative to the neutral position for that axis of travel.
00b = Not on Positive side of Neutral
01b = On positive side of Neutral
10b = ...";
CM_ SG_ 2365400574 Jystck9GrpXAxsLvrLftNgtvPsStatus "Reports when the current joystick grip position is on the negative travel side (back, left, counterclockwise, down) relative to the neutral position for that axis of travel.
00b = Not on negative side of Neutral
01b = On negative side of Neutral
 ...";
CM_ SG_ 2365400574 Jystck9GripXAxisNeutralPosStatus "Reports when the current joystick grip position is in the neutral position for that axis of travel.  The neutral position measurement must be determined from some mechanism other than the axis position measurement device.
00b = Not in Neutral ...";
CM_ BO_ 2365401086 "Extended Joystick Message 8
Used to transfer information about the measured status of three additional axes of a joystick and switches of the joystick grip or handle.  The joystick axial motion information is available in the Basic Joystick ...";
CM_ SG_ 2365401086 Joystick8Button13PressedStatus "Reports when the joystick button has been pressed.

00b = Button not pressed
01b = Button pressed
10b = Error Indicator
11b = Not Available";
CM_ SG_ 2365401086 Joystick8Button14PressedStatus "Reports when the joystick button has been pressed.

00b = Button not pressed
01b = Button pressed
10b = Error Indicator
11b = Not Available";
CM_ SG_ 2365401086 Joystick8Button15PressedStatus "Reports when the joystick button has been pressed.

00b = Button not pressed
01b = Button pressed
10b = Error Indicator
11b = Not Available";
CM_ SG_ 2365401086 Joystick8Button16PressedStatus "Reports when the joystick button has been pressed.

00b = Button not pressed
01b = Button pressed
10b = Error Indicator
11b = Not Available";
CM_ SG_ 2365401086 Jystick8GripXAxisDetentPosStatus "Reports when the current joystick grip position is in the detent position for that axis of travel.

00b = Not in the Detent Position
01b = In the Detent Position
10b = Error Indicator
11b = Not Available";
CM_ SG_ 2365401086 Jystick8GripYAxisDetentPosStatus "Reports when the current joystick grip position is in the detent position for that axis of travel.

00b = Not in the Detent Position
01b = In the Detent Position
10b = Error Indicator
11b = Not Available";
CM_ SG_ 2365401086 Jystick8ThetaAxisDetentPosStatus "Reports when the current joystick position is in the detent position for that axis of travel.

00b = Not in the Detent Position
01b = In the Detent Position
10b = Error Indicator
11b = Not Available";
CM_ SG_ 2365401086 Joystick8ThetaAxisPos "The position of the joystick in the relative motion of travel from the neutral position.  Position value of 0 is Neutral and position value 1000 (100%) is the end of linear zone.  Value of 1022 indicates an error has occurred.";
CM_ SG_ 2365401086 Jystck8ThtAxsClckwsPstvPosStatus "Reports when the current joystick position is on the positive travel side (forward, right, clockwise, up) relative to the neutral position for that axis of travel.
00b = Not on Positive side of Neutral
01b = On positive side of Neutral
10b = ...";
CM_ SG_ 2365401086 Jystck8ThtAxsCntrClckwsNgtvPsStt "Reports when the current joystick position is on the negative travel side (back, left, counterclockwise, down) relative to the neutral position for that axis of travel.
00b = Not on negative side of Neutral
01b = On negative side of Neutral
10b = ...";
CM_ SG_ 2365401086 Jystck8ThetaAxisNeutralPosStatus "Reports when the current joystick position is in the neutral position for that axis of travel.  The neutral position measurement must be determined from some mechanism other than the axis position measurement device.
00b = Not in Neutral Position
 ...";
CM_ SG_ 2365401086 Joystick8GripYAxisPos "The position of the joystick grip in the relative motion of travel from the neutral position.  Position value of 0 is Neutral and position value 1000 (100%) is the end of linear zone.  Value of 1022 indicates an error has occurred.";
CM_ SG_ 2365401086 Jystck8GrpYAxsLvrFrwrdPstvPsStts "Reports when the current joystick grip position is on the positive travel side (forward, right, clockwise, up) relative to the neutral position for that axis of travel.
00b = Not on Positive side of Neutral
01b = On positive side of Neutral
10b = ...";
CM_ SG_ 2365401086 Jystck8GrpYAxsLvrBckNgtvPsStatus "Reports when the current joystick grip position is on the negative travel side (back, left, counterclockwise, down) relative to the neutral position for that axis of travel.
00b = Not on negative side of Neutral
01b = On negative side of Neutral
 ...";
CM_ SG_ 2365401086 Jystck8GripYAxisNeutralPosStatus "Reports when the current joystick grip position is in the neutral position for that axis of travel.  The neutral position measurement must be determined from some mechanism other than the axis position measurement device.
00b = Not in Neutral ...";
CM_ SG_ 2365401086 Joystick8GripXAxisPos "The position of the joystick grip in the relative motion of travel from the neutral position.  Position value of 0 is Neutral and position value 1000 (100%) is the end of linear zone.  Value of 1022 indicates an error has occurred.";
CM_ SG_ 2365401086 Jystck8GrpXAxsLvrRghtPstvPsSttus "Reports when the current joystick grip position is on the positive travel side (forward, right, clockwise, up) relative to the neutral position for that axis of travel.
00b = Not on Positive side of Neutral
01b = On positive side of Neutral
10b = ...";
CM_ SG_ 2365401086 Jystck8GrpXAxsLvrLftNgtvPsStatus "Reports when the current joystick grip position is on the negative travel side (back, left, counterclockwise, down) relative to the neutral position for that axis of travel.
00b = Not on negative side of Neutral
01b = On negative side of Neutral
 ...";
CM_ SG_ 2365401086 Jystck8GripXAxisNeutralPosStatus "Reports when the current joystick grip position is in the neutral position for that axis of travel.  The neutral position measurement must be determined from some mechanism other than the axis position measurement device.
00b = Not in Neutral ...";
CM_ BO_ 2365401598 "Extended Joystick Message 7
Used to transfer information about the measured status of three additional axes of a joystick and switches of the joystick grip or handle.  The joystick axial motion information is available in the Basic Joystick ...";
CM_ SG_ 2365401598 Joystick7Button13PressedStatus "Reports when the joystick button has been pressed.

00b = Button not pressed
01b = Button pressed
10b = Error Indicator
11b = Not Available";
CM_ SG_ 2365401598 Joystick7Button14PressedStatus "Reports when the joystick button has been pressed.

00b = Button not pressed
01b = Button pressed
10b = Error Indicator
11b = Not Available";
CM_ SG_ 2365401598 Joystick7Button15PressedStatus "Reports when the joystick button has been pressed.

00b = Button not pressed
01b = Button pressed
10b = Error Indicator
11b = Not Available";
CM_ SG_ 2365401598 Joystick7Button16PressedStatus "Reports when the joystick button has been pressed.

00b = Button not pressed
01b = Button pressed
10b = Error Indicator
11b = Not Available";
CM_ SG_ 2365401598 Jystick7GripXAxisDetentPosStatus "Reports when the current joystick grip position is in the detent position for that axis of travel.

00b = Not in the Detent Position
01b = In the Detent Position
10b = Error Indicator
11b = Not Available";
CM_ SG_ 2365401598 Jystick7GripYAxisDetentPosStatus "Reports when the current joystick grip position is in the detent position for that axis of travel.

00b = Not in the Detent Position
01b = In the Detent Position
10b = Error Indicator
11b = Not Available";
CM_ SG_ 2365401598 Jystick7ThetaAxisDetentPosStatus "Reports when the current joystick position is in the detent position for that axis of travel.

00b = Not in the Detent Position
01b = In the Detent Position
10b = Error Indicator
11b = Not Available";
CM_ SG_ 2365401598 Joystick7ThetaAxisPos "The position of the joystick in the relative motion of travel from the neutral position.  Position value of 0 is Neutral and position value 1000 (100%) is the end of linear zone.  Value of 1022 indicates an error has occurred.";
CM_ SG_ 2365401598 Jystck7ThtAxsClckwsPstvPosStatus "Reports when the current joystick position is on the positive travel side (forward, right, clockwise, up) relative to the neutral position for that axis of travel.
00b = Not on Positive side of Neutral
01b = On positive side of Neutral
10b = ...";
CM_ SG_ 2365401598 Jystck7ThtAxsCntrClckwsNgtvPsStt "Reports when the current joystick position is on the negative travel side (back, left, counterclockwise, down) relative to the neutral position for that axis of travel.
00b = Not on negative side of Neutral
01b = On negative side of Neutral
10b = ...";
CM_ SG_ 2365401598 Jystck7ThetaAxisNeutralPosStatus "Reports when the current joystick position is in the neutral position for that axis of travel.  The neutral position measurement must be determined from some mechanism other than the axis position measurement device.
00b = Not in Neutral Position
 ...";
CM_ SG_ 2365401598 Joystick7GripYAxisPos "The position of the joystick grip in the relative motion of travel from the neutral position.  Position value of 0 is Neutral and position value 1000 (100%) is the end of linear zone.  Value of 1022 indicates an error has occurred.";
CM_ SG_ 2365401598 Jystck7GrpYAxsLvrFrwrdPstvPsStts "Reports when the current joystick grip position is on the positive travel side (forward, right, clockwise, up) relative to the neutral position for that axis of travel.
00b = Not on Positive side of Neutral
01b = On positive side of Neutral
10b = ...";
CM_ SG_ 2365401598 Jystck7GrpYAxsLvrBckNgtvPsStatus "Reports when the current joystick grip position is on the negative travel side (back, left, counterclockwise, down) relative to the neutral position for that axis of travel.
00b = Not on negative side of Neutral
01b = On negative side of Neutral
 ...";
CM_ SG_ 2365401598 Jystck7GripYAxisNeutralPosStatus "Reports when the current joystick grip position is in the neutral position for that axis of travel.  The neutral position measurement must be determined from some mechanism other than the axis position measurement device.
00b = Not in Neutral ...";
CM_ SG_ 2365401598 Joystick7GripXAxisPos "The position of the joystick grip in the relative motion of travel from the neutral position.  Position value of 0 is Neutral and position value 1000 (100%) is the end of linear zone.  Value of 1022 indicates an error has occurred.";
CM_ SG_ 2365401598 Jystck7GrpXAxsLvrRghtPstvPsSttus "Reports when the current joystick grip position is on the positive travel side (forward, right, clockwise, up) relative to the neutral position for that axis of travel.
00b = Not on Positive side of Neutral
01b = On positive side of Neutral
10b = ...";
CM_ SG_ 2365401598 Jystck7GrpXAxsLvrLftNgtvPsStatus "Reports when the current joystick grip position is on the negative travel side (back, left, counterclockwise, down) relative to the neutral position for that axis of travel.
00b = Not on negative side of Neutral
01b = On negative side of Neutral
 ...";
CM_ SG_ 2365401598 Jystck7GripXAxisNeutralPosStatus "Reports when the current joystick grip position is in the neutral position for that axis of travel.  The neutral position measurement must be determined from some mechanism other than the axis position measurement device.
00b = Not in Neutral ...";
CM_ BO_ 2365402110 "Extended Joystick Message 6
Used to transfer information about the measured status of three additional axes of a joystick and switches of the joystick grip or handle.  The joystick axial motion information is available in the Basic Joystick ...";
CM_ SG_ 2365402110 Joystick6Button13PressedStatus "Reports when the joystick button has been pressed.

00b = Button not pressed
01b = Button pressed
10b = Error Indicator
11b = Not Available";
CM_ SG_ 2365402110 Joystick6Button14PressedStatus "Reports when the joystick button has been pressed.

00b = Button not pressed
01b = Button pressed
10b = Error Indicator
11b = Not Available";
CM_ SG_ 2365402110 Joystick6Button15PressedStatus "Reports when the joystick button has been pressed.

00b = Button not pressed
01b = Button pressed
10b = Error Indicator
11b = Not Available";
CM_ SG_ 2365402110 Joystick6Button16PressedStatus "Reports when the joystick button has been pressed.

00b = Button not pressed
01b = Button pressed
10b = Error Indicator
11b = Not Available";
CM_ SG_ 2365402110 Jystick6GripXAxisDetentPosStatus "Reports when the current joystick grip position is in the detent position for that axis of travel.

00b = Not in the Detent Position
01b = In the Detent Position
10b = Error Indicator
11b = Not Available";
CM_ SG_ 2365402110 Jystick6GripYAxisDetentPosStatus "Reports when the current joystick grip position is in the detent position for that axis of travel.

00b = Not in the Detent Position
01b = In the Detent Position
10b = Error Indicator
11b = Not Available";
CM_ SG_ 2365402110 Jystick6ThetaAxisDetentPosStatus "Reports when the current joystick position is in the detent position for that axis of travel.

00b = Not in the Detent Position
01b = In the Detent Position
10b = Error Indicator
11b = Not Available";
CM_ SG_ 2365402110 Joystick6ThetaAxisPos "The position of the joystick in the relative motion of travel from the neutral position.  Position value of 0 is Neutral and position value 1000 (100%) is the end of linear zone.  Value of 1022 indicates an error has occurred.";
CM_ SG_ 2365402110 Jystck6ThtAxsClckwsPstvPosStatus "Reports when the current joystick position is on the positive travel side (forward, right, clockwise, up) relative to the neutral position for that axis of travel.
00b = Not on Positive side of Neutral
01b = On positive side of Neutral
10b = ...";
CM_ SG_ 2365402110 Jystck6ThtAxsCntrClckwsNgtvPsStt "Reports when the current joystick position is on the negative travel side (back, left, counterclockwise, down) relative to the neutral position for that axis of travel.
00b = Not on negative side of Neutral
01b = On negative side of Neutral
10b = ...";
CM_ SG_ 2365402110 Jystck6ThetaAxisNeutralPosStatus "Reports when the current joystick position is in the neutral position for that axis of travel.  The neutral position measurement must be determined from some mechanism other than the axis position measurement device.
00b = Not in Neutral Position
 ...";
CM_ SG_ 2365402110 Joystick6GripYAxisPos "The position of the joystick grip in the relative motion of travel from the neutral position.  Position value of 0 is Neutral and position value 1000 (100%) is the end of linear zone.  Value of 1022 indicates an error has occurred.";
CM_ SG_ 2365402110 Jystck6GrpYAxsLvrFrwrdPstvPsStts "Reports when the current joystick grip position is on the positive travel side (forward, right, clockwise, up) relative to the neutral position for that axis of travel.
00b = Not on Positive side of Neutral
01b = On positive side of Neutral
10b = ...";
CM_ SG_ 2365402110 Jystck6GrpYAxsLvrBckNgtvPsStatus "Reports when the current joystick grip position is on the negative travel side (back, left, counterclockwise, down) relative to the neutral position for that axis of travel.
00b = Not on negative side of Neutral
01b = On negative side of Neutral
 ...";
CM_ SG_ 2365402110 Jystck6GripYAxisNeutralPosStatus "Reports when the current joystick grip position is in the neutral position for that axis of travel.  The neutral position measurement must be determined from some mechanism other than the axis position measurement device.
00b = Not in Neutral ...";
CM_ SG_ 2365402110 Joystick6GripXAxisPos "The position of the joystick grip in the relative motion of travel from the neutral position.  Position value of 0 is Neutral and position value 1000 (100%) is the end of linear zone.  Value of 1022 indicates an error has occurred.";
CM_ SG_ 2365402110 Jystck6GrpXAxsLvrRghtPstvPsSttus "Reports when the current joystick grip position is on the positive travel side (forward, right, clockwise, up) relative to the neutral position for that axis of travel.
00b = Not on Positive side of Neutral
01b = On positive side of Neutral
10b = ...";
CM_ SG_ 2365402110 Jystck6GrpXAxsLvrLftNgtvPsStatus "Reports when the current joystick grip position is on the negative travel side (back, left, counterclockwise, down) relative to the neutral position for that axis of travel.
00b = Not on negative side of Neutral
01b = On negative side of Neutral
 ...";
CM_ SG_ 2365402110 Jystck6GripXAxisNeutralPosStatus "Reports when the current joystick grip position is in the neutral position for that axis of travel.  The neutral position measurement must be determined from some mechanism other than the axis position measurement device.
00b = Not in Neutral ...";
CM_ BO_ 2365402622 "Extended Joystick Message 5
Used to transfer information about the measured status of three additional axes of a joystick and switches of the joystick grip or handle.  The joystick axial motion information is available in the Basic Joystick ...";
CM_ SG_ 2365402622 Joystick5Button13PressedStatus "Reports when the joystick button has been pressed.

00b = Button not pressed
01b = Button pressed
10b = Error Indicator
11b = Not Available";
CM_ SG_ 2365402622 Joystick5Button14PressedStatus "Reports when the joystick button has been pressed.

00b = Button not pressed
01b = Button pressed
10b = Error Indicator
11b = Not Available";
CM_ SG_ 2365402622 Joystick5Button15PressedStatus "Reports when the joystick button has been pressed.

00b = Button not pressed
01b = Button pressed
10b = Error Indicator
11b = Not Available";
CM_ SG_ 2365402622 Joystick5Button16PressedStatus "Reports when the joystick button has been pressed.

00b = Button not pressed
01b = Button pressed
10b = Error Indicator
11b = Not Available";
CM_ SG_ 2365402622 Jystick5GripXAxisDetentPosStatus "Reports when the current joystick grip position is in the detent position for that axis of travel.

00b = Not in the Detent Position
01b = In the Detent Position
10b = Error Indicator
11b = Not Available";
CM_ SG_ 2365402622 Jystick5GripYAxisDetentPosStatus "Reports when the current joystick grip position is in the detent position for that axis of travel.

00b = Not in the Detent Position
01b = In the Detent Position
10b = Error Indicator
11b = Not Available";
CM_ SG_ 2365402622 Jystick5ThetaAxisDetentPosStatus "Reports when the current joystick position is in the detent position for that axis of travel.

00b = Not in the Detent Position
01b = In the Detent Position
10b = Error Indicator
11b = Not Available";
CM_ SG_ 2365402622 Joystick5ThetaAxisPos "The position of the joystick in the relative motion of travel from the neutral position.  Position value of 0 is Neutral and position value 1000 (100%) is the end of linear zone.  Value of 1022 indicates an error has occurred.";
CM_ SG_ 2365402622 Jystck5ThtAxsClckwsPstvPosStatus "Reports when the current joystick position is on the positive travel side (forward, right, clockwise, up) relative to the neutral position for that axis of travel.
00b = Not on Positive side of Neutral
01b = On positive side of Neutral
10b = ...";
CM_ SG_ 2365402622 Jystck5ThtAxsCntrClckwsNgtvPsStt "Reports when the current joystick position is on the negative travel side (back, left, counterclockwise, down) relative to the neutral position for that axis of travel.
00b = Not on negative side of Neutral
01b = On negative side of Neutral
10b = ...";
CM_ SG_ 2365402622 Jystck5ThetaAxisNeutralPosStatus "Reports when the current joystick position is in the neutral position for that axis of travel.  The neutral position measurement must be determined from some mechanism other than the axis position measurement device.
00b = Not in Neutral Position
 ...";
CM_ SG_ 2365402622 Joystick5GripYAxisPos "The position of the joystick grip in the relative motion of travel from the neutral position.  Position value of 0 is Neutral and position value 1000 (100%) is the end of linear zone.  Value of 1022 indicates an error has occurred.";
CM_ SG_ 2365402622 Jystck5GrpYAxsLvrFrwrdPstvPsStts "Reports when the current joystick grip position is on the positive travel side (forward, right, clockwise, up) relative to the neutral position for that axis of travel.
00b = Not on Positive side of Neutral
01b = On positive side of Neutral
10b = ...";
CM_ SG_ 2365402622 Jystck5GrpYAxsLvrBckNgtvPsStatus "Reports when the current joystick grip position is on the negative travel side (back, left, counterclockwise, down) relative to the neutral position for that axis of travel.
00b = Not on negative side of Neutral
01b = On negative side of Neutral
 ...";
CM_ SG_ 2365402622 Jystck5GripYAxisNeutralPosStatus "Reports when the current joystick grip position is in the neutral position for that axis of travel.  The neutral position measurement must be determined from some mechanism other than the axis position measurement device.
00b = Not in Neutral ...";
CM_ SG_ 2365402622 Joystick5GripXAxisPos "The position of the joystick grip in the relative motion of travel from the neutral position.  Position value of 0 is Neutral and position value 1000 (100%) is the end of linear zone.  Value of 1022 indicates an error has occurred.";
CM_ SG_ 2365402622 Jystck5GrpXAxsLvrRghtPstvPsSttus "Reports when the current joystick grip position is on the positive travel side (forward, right, clockwise, up) relative to the neutral position for that axis of travel.
00b = Not on Positive side of Neutral
01b = On positive side of Neutral
10b = ...";
CM_ SG_ 2365402622 Jystck5GrpXAxsLvrLftNgtvPsStatus "Reports when the current joystick grip position is on the negative travel side (back, left, counterclockwise, down) relative to the neutral position for that axis of travel.
00b = Not on negative side of Neutral
01b = On negative side of Neutral
 ...";
CM_ SG_ 2365402622 Jystck5GripXAxisNeutralPosStatus "Reports when the current joystick grip position is in the neutral position for that axis of travel.  The neutral position measurement must be determined from some mechanism other than the axis position measurement device.
00b = Not in Neutral ...";
CM_ BO_ 2365403134 "Extended Joystick Message 4
Used to transfer information about the measured status of three additional axes of a joystick and switches of the joystick grip or handle.  The joystick axial motion information is available in the Basic Joystick ...";
CM_ SG_ 2365403134 Joystick4Button13PressedStatus "Reports when the joystick button has been pressed.

00b = Button not pressed
01b = Button pressed
10b = Error Indicator
11b = Not Available";
CM_ SG_ 2365403134 Joystick4Button14PressedStatus "Reports when the joystick button has been pressed.

00b = Button not pressed
01b = Button pressed
10b = Error Indicator
11b = Not Available";
CM_ SG_ 2365403134 Joystick4Button15PressedStatus "Reports when the joystick button has been pressed.

00b = Button not pressed
01b = Button pressed
10b = Error Indicator
11b = Not Available";
CM_ SG_ 2365403134 Joystick4Button16PressedStatus "Reports when the joystick button has been pressed.

00b = Button not pressed
01b = Button pressed
10b = Error Indicator
11b = Not Available";
CM_ SG_ 2365403134 Jystick4GripXAxisDetentPosStatus "Reports when the current joystick grip position is in the detent position for that axis of travel.

00b = Not in the Detent Position
01b = In the Detent Position
10b = Error Indicator
11b = Not Available";
CM_ SG_ 2365403134 Jystick4GripYAxisDetentPosStatus "Reports when the current joystick grip position is in the detent position for that axis of travel.

00b = Not in the Detent Position
01b = In the Detent Position
10b = Error Indicator
11b = Not Available";
CM_ SG_ 2365403134 Jystick4ThetaAxisDetentPosStatus "Reports when the current joystick position is in the detent position for that axis of travel.

00b = Not in the Detent Position
01b = In the Detent Position
10b = Error Indicator
11b = Not Available";
CM_ SG_ 2365403134 Joystick4ThetaAxisPos "The position of the joystick in the relative motion of travel from the neutral position.  Position value of 0 is Neutral and position value 1000 (100%) is the end of linear zone.  Value of 1022 indicates an error has occurred.";
CM_ SG_ 2365403134 Jystck4ThtAxsClckwsPstvPosStatus "Reports when the current joystick position is on the positive travel side (forward, right, clockwise, up) relative to the neutral position for that axis of travel.
00b = Not on Positive side of Neutral
01b = On positive side of Neutral
10b = ...";
CM_ SG_ 2365403134 Jystck4ThtAxsCntrClckwsNgtvPsStt "Reports when the current joystick position is on the negative travel side (back, left, counterclockwise, down) relative to the neutral position for that axis of travel.
00b = Not on negative side of Neutral
01b = On negative side of Neutral
10b = ...";
CM_ SG_ 2365403134 Jystck4ThetaAxisNeutralPosStatus "Reports when the current joystick position is in the neutral position for that axis of travel.  The neutral position measurement must be determined from some mechanism other than the axis position measurement device.
00b = Not in Neutral Position
 ...";
CM_ SG_ 2365403134 Joystick4GripYAxisPos "The position of the joystick grip in the relative motion of travel from the neutral position.  Position value of 0 is Neutral and position value 1000 (100%) is the end of linear zone.  Value of 1022 indicates an error has occurred.";
CM_ SG_ 2365403134 Jystck4GrpYAxsLvrFrwrdPstvPsStts "Reports when the current joystick grip position is on the positive travel side (forward, right, clockwise, up) relative to the neutral position for that axis of travel.
00b = Not on Positive side of Neutral
01b = On positive side of Neutral
10b = ...";
CM_ SG_ 2365403134 Jystck4GrpYAxsLvrBckNgtvPsStatus "Reports when the current joystick grip position is on the negative travel side (back, left, counterclockwise, down) relative to the neutral position for that axis of travel.
00b = Not on negative side of Neutral
01b = On negative side of Neutral
 ...";
CM_ SG_ 2365403134 Jystck4GripYAxisNeutralPosStatus "Reports when the current joystick grip position is in the neutral position for that axis of travel.  The neutral position measurement must be determined from some mechanism other than the axis position measurement device.
00b = Not in Neutral ...";
CM_ SG_ 2365403134 Joystick4GripXAxisPos "The position of the joystick grip in the relative motion of travel from the neutral position.  Position value of 0 is Neutral and position value 1000 (100%) is the end of linear zone.  Value of 1022 indicates an error has occurred.";
CM_ SG_ 2365403134 Jystck4GrpXAxsLvrRghtPstvPsSttus "Reports when the current joystick grip position is on the positive travel side (forward, right, clockwise, up) relative to the neutral position for that axis of travel.
00b = Not on Positive side of Neutral
01b = On positive side of Neutral
10b = ...";
CM_ SG_ 2365403134 Jystck4GrpXAxsLvrLftNgtvPsStatus "Reports when the current joystick grip position is on the negative travel side (back, left, counterclockwise, down) relative to the neutral position for that axis of travel.
00b = Not on negative side of Neutral
01b = On negative side of Neutral
 ...";
CM_ SG_ 2365403134 Jystck4GripXAxisNeutralPosStatus "Reports when the current joystick grip position is in the neutral position for that axis of travel.  The neutral position measurement must be determined from some mechanism other than the axis position measurement device.
00b = Not in Neutral ...";
CM_ BO_ 2365400062 "Extended Joystick Message 10
Used to transfer information about the measured status of three additional axes of a joystick and switches of the joystick grip or handle.  The joystick axial motion information is available in the Basic Joystick ...";
CM_ SG_ 2365400062 Joystick10Button13PressedStatus "Reports when the joystick button has been pressed.

00b = Button not pressed
01b = Button pressed
10b = Error Indicator
11b = Not Available";
CM_ SG_ 2365400062 Joystick10Button14PressedStatus "Reports when the joystick button has been pressed.

00b = Button not pressed
01b = Button pressed
10b = Error Indicator
11b = Not Available";
CM_ SG_ 2365400062 Joystick10Button15PressedStatus "Reports when the joystick button has been pressed.

00b = Button not pressed
01b = Button pressed
10b = Error Indicator
11b = Not Available";
CM_ SG_ 2365400062 Joystick10Button16PressedStatus "Reports when the joystick button has been pressed.

00b = Button not pressed
01b = Button pressed
10b = Error Indicator
11b = Not Available";
CM_ SG_ 2365400062 Jystck10GripXAxisDetentPosStatus "Reports when the current joystick grip position is in the detent position for that axis of travel.

00b = Not in the Detent Position
01b = In the Detent Position
10b = Error Indicator
11b = Not Available";
CM_ SG_ 2365400062 Jystck10GripYAxisDetentPosStatus "Reports when the current joystick grip position is in the detent position for that axis of travel.

00b = Not in the Detent Position
01b = In the Detent Position
10b = Error Indicator
11b = Not Available";
CM_ SG_ 2365400062 Jystck10ThetaAxisDetentPosStatus "Reports when the current joystick position is in the detent position for that axis of travel.

00b = Not in the Detent Position
01b = In the Detent Position
10b = Error Indicator
11b = Not Available";
CM_ SG_ 2365400062 Joystick10ThetaAxisPos "The position of the joystick in the relative motion of travel from the neutral position.  Position value of 0 is Neutral and position value 1000 (100%) is the end of linear zone.  Value of 1022 indicates an error has occurred.";
CM_ SG_ 2365400062 Jystck10ThtAxsClckwsPstvPsStatus "Reports when the current joystick position is on the positive travel side (forward, right, clockwise, up) relative to the neutral position for that axis of travel.
00b = Not on Positive side of Neutral
01b = On positive side of Neutral
10b = ...";
CM_ SG_ 2365400062 Jystck10ThtAxsCntrClckwsNgtvPsSt "Reports when the current joystick position is on the negative travel side (back, left, counterclockwise, down) relative to the neutral position for that axis of travel.
00b = Not on negative side of Neutral
01b = On negative side of Neutral
10b = ...";
CM_ SG_ 2365400062 Jystck10ThtaAxisNeutralPosStatus "Reports when the current joystick position is in the neutral position for that axis of travel.  The neutral position measurement must be determined from some mechanism other than the axis position measurement device.
00b = Not in Neutral Position
 ...";
CM_ SG_ 2365400062 Joystick10GripYAxisPos "The position of the joystick grip in the relative motion of travel from the neutral position.  Position value of 0 is Neutral and position value 1000 (100%) is the end of linear zone.  Value of 1022 indicates an error has occurred.";
CM_ SG_ 2365400062 Jystck10GrpYAxsLvrFrwrdPstvPsStt "Reports when the current joystick grip position is on the positive travel side (forward, right, clockwise, up) relative to the neutral position for that axis of travel.
00b = Not on Positive side of Neutral
01b = On positive side of Neutral
10b = ...";
CM_ SG_ 2365400062 Jystck10GrpYAxsLvrBckNgtvPsSttus "Reports when the current joystick grip position is on the negative travel side (back, left, counterclockwise, down) relative to the neutral position for that axis of travel.
00b = Not on negative side of Neutral
01b = On negative side of Neutral
 ...";
CM_ SG_ 2365400062 Jystck10GrpYAxisNeutralPosStatus "Reports when the current joystick grip position is in the neutral position for that axis of travel.  The neutral position measurement must be determined from some mechanism other than the axis position measurement device.
00b = Not in Neutral ...";
CM_ SG_ 2365400062 Joystick10GripXAxisPos "The position of the joystick grip in the relative motion of travel from the neutral position.  Position value of 0 is Neutral and position value 1000 (100%) is the end of linear zone.  Value of 1022 indicates an error has occurred.";
CM_ SG_ 2365400062 Jystck10GrpXAxsLvrRghtPstvPsStts "Reports when the current joystick grip position is on the positive travel side (forward, right, clockwise, up) relative to the neutral position for that axis of travel.
00b = Not on Positive side of Neutral
01b = On positive side of Neutral
10b = ...";
CM_ SG_ 2365400062 Jystck10GrpXAxsLvrLftNgtvPsSttus "Reports when the current joystick grip position is on the negative travel side (back, left, counterclockwise, down) relative to the neutral position for that axis of travel.
00b = Not on negative side of Neutral
01b = On negative side of Neutral
 ...";
CM_ SG_ 2365400062 Jystck10GrpXAxisNeutralPosStatus "Reports when the current joystick grip position is in the neutral position for that axis of travel.  The neutral position measurement must be determined from some mechanism other than the axis position measurement device.
00b = Not in Neutral ...";
CM_ BO_ 2566713598 "Engine Fuel/Lube 
Systems 2
Contains information on the engine fuel and lube system";
CM_ SG_ 2566713598 FuelPumpInOilPress "Oil pressure at the intake of the engine fuel pump.";
CM_ SG_ 2566713598 FuelTankTransferPumpPress "Gage pressure of the fuel in the system as delivered by the transfer pump.";
CM_ SG_ 2566713598 FuelTankTransferPump "Operating state of the fuel tank transfer pump. The fuel tank transfer pump transfers fuel from the secondary fuel tank to the primary fuel tank.

00b = Off
01b = On
10b = Error
11b = Not available";
CM_ SG_ 2566713598 EngFuelFilterDegradation "The estimated percentage relative to the useful life of the engine fuel filter on the suction side which is located betwee the fuel tank and the fuel supply pump.
Note:  This is not a calculation of the physical restriction of the filter. 0% is ...";
CM_ SG_ 2566713598 EngFuelFilterIntakeAbsPress "Absolute pressure of fuel at the intake of the fuel filter (suction side) located between the fuel tank and the fuel supply pump.  See Figures SPN16_A & SPN16_B.";
CM_ BO_ 2499604478 "Engine Fluid Level/Pressure 11
Engine related parameters.";
CM_ SG_ 2499604478 EngFuelDeliveryPress "Gage pressure of fuel in system as delivered from supply pump to the injection pump. See SPN 94 for alternate resolution.

See also SPN 5578 for Engine Fuel Delivery Absolute Pressure.";
CM_ SG_ 2499604478 EngOilPress "Gage pressure of oil in engine lubrication system as provided by oil pump. See SPN 100 for alternate resolution.";
CM_ SG_ 2499604478 EngExhstGsRcrcltn1OutletAbsPress "EGR outlet absolute pressure is measured after the EGR 1 valve. See SPN 5019 for 1 byte resolution.";
CM_ SG_ 2499604478 EngExhstGsRcrcltn1IntakeAbsPress "EGR intake absolute pressure measured before the EGR 1 valve.";
CM_ BO_ 2499608830 "Engine Fluid Level/Pressure 10
Engine related parameters";
CM_ SG_ 2499608830 EngCoolantPress2 "Gage pressure of liquid found in the engine coolant system - second instance.

See SPN 7313 for alternate range and resolution.";
CM_ SG_ 2499608830 EngExhstGsRcrcltn2IntakeAbsPress "EGR intake absolute pressure measured before the EGR 2 valve.";
CM_ SG_ 2499608830 EngExhstGsRcrcltn2OutletAbsPress "Absolute Pressure immediately after the EGR2 valve";
CM_ SG_ 2499608830 EngExhstGsRcrclation2IntakePress "EGR2 intake gauge pressure is measured after EGR2 cooler and before EGR2 valve";
CM_ SG_ 2499608830 EngExhstGsRcirculation2DiffPress "Differential Pressure across the Exhaust Gas Recirculation 2 (EGR2) system.";
CM_ BO_ 2432499198 "Electronic Engine Controller 9
Engine related parameters";
CM_ SG_ 2432499198 CmmndedEngFuelInjectionCtrlPress "Provides the commanded set point value for the engine fuel injection control pressure.";
CM_ SG_ 2432499198 CommandedEngFuelRailPress "Provides the commanded set point value for the engine fuel rail gage pressure";
CM_ SG_ 2432499198 EngExhstGsRcirculation2Valve2Pos "The position of the second exhaust gas recirculation valve of EGR 2 expressed as a percentage of full travel. 0% means the valve is closed and no exhaust gas is flowing into the air stream. 100% means the valve is fully opened.";
CM_ SG_ 2432499198 EngExhstGsRecirculation2ValvePos "Position of EGR2 valve expressed as a percentage of full travel. 0% means the valve is closed and no exhaust gas is flowing into the air stream. 100% means the valve is fully opened.";
CM_ BO_ 2633825022 "Electronic Engine Controller 11
Engine related parameters";
CM_ SG_ 2633825022 EngExhstGsRcrcltn2Valve2PosError "The position error of the Exhaust Gas Recirculation 2 valve 2, determined as the actual position (SPN 5265) minus the commanded position (SPN 5263).";
CM_ SG_ 2633825022 EngExhstGsRcrcltn2Valve1PosError "The position error of the Exhaust Gas Recirculation 2 valve, determined as the actual position (SPN 5264) minus the commanded position (SPN 5262).";
CM_ SG_ 2633825022 EngExhstGsRcrculation2Valve2Ctrl "Desired percentage of maximum Exhaust Gas Recirculation 2 (EGR2) valve 2 opening. 0% means the valve is closed. 100% means maximum opening (full gas flow).";
CM_ SG_ 2633825022 EngExhstGsRcirculation2ValveCtrl "Desired percentage of maximum Exhaust Gas Recirculation 2 (EGR2) valve opening. 0% means the valve is closed. 100% means maximum opening (full gas flow).";
CM_ BO_ 2633826046 "Electronic Engine Controller 10
Engine related parameters";
CM_ SG_ 2633826046 EGR2CoolerInPress "Exhaust gas recirculation 2 (EGR2) gage pressure is measured at the EGR2 cooler intake.";
CM_ SG_ 2633826046 EGR2CoolerBypassActuatorPos "EGR2 Cooler Bypass Actuator position, where 0% = Fully Closed (no gas flowing through the bypass), and 100% = Fully Open..";
CM_ SG_ 2633826046 EngExhstGsRcrcltn2ClerEfficiency "Exhaust Gas Recirculation 2 cooler efficiency is an indication of the cooler’s ability to reduce the temperature of the exhaust gas that is being recirculated back to the intake. 0% = no reduction in temperature, 100% = maximum cooling. The EGR 2 ...";
CM_ SG_ 2633826046 EngExhstGsRcrcltn2ClrIntkGsAbsPr "Exhaust Gas Recirculation 2 gas absolute pressure is measured at EGR2 cooler intake. See SPN 5253 for EGR2 pressure measured at the EGR2 cooler outlet before the valve.";
CM_ SG_ 2633826046 EngExhstGsRcrcltn2ClerIntakeTemp "Exhaust Gas Recirculation 2 (EGR2) Temperature measured at EGR2 cooler intake. See SPN 5255 for Engine EGR2 temperature.";
CM_ BO_ 2566711294 "Engine Configuration 3
The EC3 message contains a static engine friction torque map consisting of torque points that correspond to the speed points in the EC1 message.  A net brake torque map for the engine can be calculated by subtracting the ...";
CM_ SG_ 2566711294 EngFrictionPercentTorquePoint7 "The static portion of the friction torque at speed point 7 (SPN 533) of the engine torque map in the engine configuration message.  This parameter does not include Estimated Pumping - Percent Torque (SPN 5398) and is expected to change with ...";
CM_ SG_ 2566711294 EngFrictionPercentTorquePoint6 "For engine configuration map modes 1 and 2, this is the static portion of the friction torque at speed point 6 (SPN 532) of the engine torque map.  For engine configuration map mode 3, this parameter is the static portion of the friction torque at ...";
CM_ SG_ 2566711294 EngFrictionPercentTorquePoint5 "The static portion of the friction torque at speed point 5 (SPN 531) of the engine torque map in the engine configuration message.  This parameter does not include Estimated Pumping - Percent Torque (SPN 5398) and is expected to change with ...";
CM_ SG_ 2566711294 EngFrictionPercentTorquePoint4 "The static portion of the friction torque at speed point 4 (SPN 530) of the engine torque map in the engine configuration message.  This parameter does not include Estimated Pumping - Percent Torque (SPN 5398) and is expected to change with ...";
CM_ SG_ 2566711294 EngFrictionPercentTorquePoint3 "The static portion of the friction torque at speed point 3 (SPN 529) of the engine torque map in the engine configuration message.  This parameter does not include Estimated Pumping - Percent Torque (SPN 5398) and is expected to change with ...";
CM_ SG_ 2566711294 EngFrictionPercentTorquePoint2 "The static portion of the friction torque at speed point 2 (SPN 528) of the engine torque map in the engine configuration message.  This parameter does not include Estimated Pumping - Percent Torque (SPN 5398) and is expected to change with ...";
CM_ SG_ 2566711294 EngFrctnPrcentTorqueAtIdlePoint1 "The static portion of the friction torque at speed point 1 (SPN 188) of the engine torque map in the engine configuration message.  This parameter does not include Estimated Pumping - Percent Torque (SPN 5398) and is expected to change with ...";
CM_ BO_ 2566749438 "Diesel Particulate Filter Control 1
This PG contains information about the diesel particulate filter regeneration control.
If there are aftertreatment systems on two banks, this PG represents the composite information from both banks.
NOTE: This ...";
CM_ SG_ 2566749438 ActiveRegenInhibitedDueThresher "Indicates the state of diesel particulate filter active regeneration inhibition due to a combine thresher being active/engaged.
This parameter indicates the reason for the diesel particulate filter regeneration not being initiated or being exited ...";
CM_ SG_ 2566749438 ActiveRegenAvailabilityStatus "Indicates that diesel particulate filter active regeneration is available for initiation through Aftertreatment Regeneration Force Switch (SPN 3696).

00b = Not ready for initiation
01b = Ready for initiation
10b = Reserved
11b = Not Available";
CM_ SG_ 2566749438 DslPrtcltFltrActvRgnrtnInhbt5629 "Indicates the state of diesel particulate filter active regeneration inhibition due to low exhaust pressure.
00b = not inhibited
01b = inhibited
10b = reserved for SAE assignment
11b = not available
This SP indicates the reason for the diesel ...";
CM_ SG_ 2566749438 A1DPFCondNotMetForActiveRegen "Indicates that diesel particulate filter 1 is not able to begin or continue an active regenerate event at the current engine operating conditions.
00b = active DPF regeneration not inhibited
01b = active DPF regeneration inhibited
10b = reserved ...";
CM_ SG_ 2566749438 HydrocarbonDoserPurgingEnable "Purging enable of the Hydrocarbon Doser (HCD).

00b = Purging not enabled
01b = Purging enabled - less urgent
10b = Purging enabled - urgent
11b = Not available";
CM_ SG_ 2566749438 DslPrtcltFltrActvRgnrtnFrcdSttus "Indicates the forced execution status of diesel particulate filter regeneration.
000b = Not Active
001b = Active - Forced by Switch (See SPN 3696)
010b = Active - Forced by Service Tool
011b = Reserved for SAE Assignment
100b = Reserved for SAE ...";
CM_ SG_ 2566749438 ExhaustSystemHighTempLampCmd "Command to control the exhaust system high temperature lamp.  This lamp indicates that the exhaust system temperature is high.
000b = Off
001b = On - solid
010b = reserved for SAE assignment
011b = reserved for SAE assignment
100b = reserved ...";
CM_ SG_ 2566749438 DslPrtcltFltrAtmtcActvRgnrtnIntt "Indicates the configuration of diesel particulate filter active regeneration automatic initiation.

00b = not enabled
01b = enabled
10b = reserved for SAE assignment
11b = not available";
CM_ SG_ 2566749438 DslPrtcltFltrActvRgnrtnInhbt3717 "Indicates the state of diesel particulate filter active regeneration inhibition due to vehicle speed being less than the allowed vehicle speed.
00b = not inhibited
01b = inhibited
10b = reserved for SAE assignment
11b = not available
This SP ...";
CM_ SG_ 2566749438 DslPrtcltFltrActvRgnrtnInhbtdDTE "Indicates the state of diesel particulate filter active regeneration inhibition due to the engine not being warmed up.
00b = not inhibited
01b = inhibited
10b = reserved for SAE assignment
11b = not available
This SP indicates the reason for ...";
CM_ SG_ 2566749438 DslPrtcltFltrActvRgnrtnInhbt3715 "Indicates the state of diesel particulate filter active regeneration inhibition due to a permanent system lockout.
00b = not inhibited
01b = inhibited
10b = reserved for SAE assignment
11b = not available
This SP indicates the reason for the ...";
CM_ SG_ 2566749438 DslPrtcltFltrActvRgnrtnInhbtdDTT "Indicates the state of diesel particulate filter active regeneration inhibition due to a temporary system lockout.
00b = not inhibited
01b = inhibited
10b = reserved for SAE assignment
11b = not available
This SP indicates the reason for the ...";
CM_ SG_ 2566749438 DslPrtcltFltrActvRgnrtnInhbt3713 "Indicates the state of diesel particulate filter active regeneration inhibition due to a system timeout.
00b = not inhibited
01b = inhibited
10b = reserved for SAE assignment
11b = not available
This SP indicates the reason for the diesel ...";
CM_ SG_ 2566749438 DslPrtcltFltrActvRgnrtnInhbt3712 "Indicates the state of diesel particulate filter active regeneration inhibition due to a system fault being active.
00b = not inhibited
01b = inhibited
10b = reserved for SAE assignment
11b = not available
This SP indicates the reason for the ...";
CM_ SG_ 2566749438 DslPrtcltFltrActvRgnrtnInhbtdDTL "Indicates the state of diesel particulate filter active regeneration inhibition due to the exhaust temperature being too low.  This implies that the diesel particulate filter and/or oxidation catalyst are likewise too cold for active regeneration.
 ...";
CM_ SG_ 2566749438 DslPrtcltFltrActvRgnrtnInhbt3710 "Indicates the state of diesel particulate filter active regeneration inhibition due to the parking brake being not set.
00b = not inhibited
01b = inhibited
10b = reserved for SAE assignment
11b = not available
This SP indicates the reason for ...";
CM_ SG_ 2566749438 DslPrtcltFltrActvRgnrtnInhbtdDTV "Indicates the state of diesel particulate filter active regeneration inhibition due to the vehicle speed being above an allowed limit.
00b = not inhibited
01b = inhibited
10b = reserved for SAE assignment
11b = not available
This SP indicates ...";
CM_ SG_ 2566749438 DslPrtcltFltrActvRgnrtnInhbtdDTO "Indicates the state of diesel particulate filter active regeneration inhibition due to the transmission being out of neutral.
00b = not inhibited
01b = inhibited
10b = reserved for SAE assignment
11b = not available
This SP indicates the reason ...";
CM_ SG_ 2566749438 DslPrtcltFltrActvRgnrtnInhbtdDTA "Indicates the state of diesel particulate filter active regeneration inhibition due to the accelerator pedal being off idle.
00b = not inhibited
01b = inhibited
10b = reserved for SAE assignment
11b = not available
This SP indicates the reason ...";
CM_ SG_ 2566749438 DslPrtcltFltrActvRgnrtnInhbtdDTP "Indicates the state of diesel particulate filter active regeneration inhibition due to the PTO being active.
00b = not inhibited
01b = inhibited
10b = reserved for SAE assignment
11b = not available
This SP indicates the reason for the diesel ...";
CM_ SG_ 2566749438 DslPrtcltFltrActvRgnrtnInhbtdDTS "Indicates the state of diesel particulate filter active regeneration inhibition due to the service brake being active.
00b = not inhibited
01b = inhibited
10b = reserved for SAE assignment
11b = not available
This SP indicates the reason for ...";
CM_ SG_ 2566749438 DslPrtcltFltrActvRgnrtnInhbtdDTC "Indicates the state of diesel particulate filter active regeneration inhibition due to the clutch being disengaged.
00b = not inhibited
01b = inhibited
10b = reserved for SAE assignment
11b = not available
This SP indicates the reason for the ...";
CM_ SG_ 2566749438 DslPrtcltFltrActvRgnrtnInhbtdDTI "Indicates the state of diesel particulate filter active regeneration inhibition due to the Diesel Particulate Filter Regeneration Inhibit Switch.
00b = not inhibited
01b = inhibited
10b = reserved for SAE assignment
11b = not available
This SP ...";
CM_ SG_ 2566749438 DslPrtcltFltrActvRgnrtnInhbtdStt "Indicates the state of diesel particulate filter active regeneration inhibition.
00b = not inhibited
01b = inhibited
10b = reserved for SAE assignment
11b = not available
This SP indicates the reason for the diesel particulate filter ...";
CM_ SG_ 2566749438 AFTDPFSt "Indicates the state of the diesel particulate filter regeneration need and urgency.  This is an aggregate of bank 1 and bank 2.  It is a system status and not individual bank status.
000b = Regeneration not needed
001b = Regeneration needed - ...";
CM_ SG_ 2566749438 AFTDPFActiveRegenSt "Indicates the state of diesel particulate filter active regeneration.  This is an aggregate of bank 1 and bank 2.  It is a system status and not individual bank status.
00b = not active
01b = active
10b = regeneration needed - automatically ...";
CM_ SG_ 2566749438 AFTDPFPassiveRegenSt "Indicates the state of diesel particulate filter passive regeneration.  This is an aggregate of bank 1 and bank 2.  It is a system status and not individual bank status.
00b = not active
01b = active
10b = reserved for SAE assignment
11b = not ...";
CM_ SG_ 2566749438 DieselParticulateFilterLampCmd "Command to control the diesel particulate filter lamp.
000b = Off
001b = On - solid
010b = reserved for SAE assignment
011b = reserved for SAE assignment
100b = On - fast blink (1 Hz)
101b = On - very fast blink
110b = reserved for SAE ...";
CM_ BO_ 2566715646 "Diesel Particulate Filter 2 Soot 2
Additional diesel particulate filter soot parameters for diesel particulate filter 2.";
CM_ SG_ 2566715646 A2DPFSootSignalMin "Minimum output signal level of the current soot measurement from diesel particulate filter 2 soot sensor.  This is a statistical value, not the minimum sensing capability of the sensor.";
CM_ SG_ 2566715646 A2DPFSootSignalMax "Maximum output signal level of the current soot measurement from diesel particulate filter 2 soot sensor.  This is a statistical value, not the maximum sensing capability of the sensor.";
CM_ SG_ 2566715646 A2DPFSootSignalStdDeviation "Standard deviation of the soot measurement from diesel particulate filter 2 soot sensor.";
CM_ BO_ 2566724606 "Diesel Particulate Filter 2 Soot
Diesel particulate filter soot parameters for diesel particulate filter 2.";
CM_ SG_ 2566724606 DslPrtcltFltr2StSnsrECUIntrnlTmp "Internal temperature of the diesel particulate filter 2 soot sensor ECU.";
CM_ SG_ 2566724606 A2DPFSootSnsrPreliminaryFMI "Used to identify the applicable J1939-73 FMI detected in the soot sensor signal by the manufacturer’s sensor control software in diesel particulate filter 2.  In the case of multiple failures the most severe is communicated.
A value of 31 is sent ...";
CM_ SG_ 2566724606 A2DPFMedianSootSignal "Median output signal level from diesel particulate filter 2 soot sensor.";
CM_ SG_ 2566724606 A2DPFMeanSootSignal "Mean output signal level from diesel particulate filter 2 soot sensor.";
CM_ SG_ 2566724606 A2DPFSootDensity "Soot density in diesel particulate filter 2.";
CM_ SG_ 2566724606 A2DPFSootMass "Soot mass in diesel particulate filter 2.";
CM_ BO_ 2566715902 "Diesel Particulate Filter 1 Soot 2
Additional diesel particulate filter soot parameters for diesel particulate filter 1.";
CM_ SG_ 2566715902 A1DPFSootSignalMin "Minimum output signal level of the current soot measurement from diesel particulate filter 1 soot sensor.  This is a statistical value, not the minimum sensing capability of the sensor.";
CM_ SG_ 2566715902 A1DPFSootSignalMax "Maximum output signal level of the current soot measurement from diesel particulate filter 1 soot sensor.  This is a statistical value, not the maximum sensing capability of the sensor.";
CM_ SG_ 2566715902 A1DPFSootSignalStdDeviation "Standard deviation of the soot measurement from diesel particulate filter 1 soot sensor.";
CM_ BO_ 2566724862 "Diesel Particulate Filter 1 Soot
Diesel particulate filter soot parameters for diesel particulate filter 1.";
CM_ SG_ 2566724862 DslPrtcltFltr1StSnsrECUIntrnlTmp "Internal temperature of the diesel particulate filter 1 soot sensor ECU.";
CM_ SG_ 2566724862 A1DPFSootSnsrPreliminaryFMI "Used to identify the applicable J1939-73 FMI detected in the soot sensor signal by the manufacturer’s sensor control software in diesel particulate filter 1. In the case of multiple failures the most severe is communicated.
A value of 31 is sent to ...";
CM_ SG_ 2566724862 A1DPFMedianSootSignal "Median output signal level from diesel particulate filter 1 soot sensor.";
CM_ SG_ 2566724862 A1DPFMeanSootSignal "Mean output signal level from diesel particulate filter 1 soot sensor.";
CM_ SG_ 2566724862 A1DPFSootDensity "Soot density in diesel particulate filter 1.";
CM_ SG_ 2566724862 A1DPFSootMass "Soot mass in diesel particulate filter 1.";
CM_ BO_ 2566718718 "Direct Lamp Control Data 2
This message will be transmitted by the controller that is illuminating the lamps.

It is not required to be used with PGN 64774.";
CM_ SG_ 2566718718 OptionalLamp6Data "This parameter provides measured data from Optional Lamp #6. Optional lamps are those that are configured for a specific application.

00b = Lamp deactivated (Off)
01b = Lamp activated (On)
10b = Error
11b = Not available";
CM_ SG_ 2566718718 OptionalLamp5Data "This parameter provides measured data from Optional Lamp #5. Optional lamps are those that are configured for a specific application.

00b = Lamp deactivated (Off)
01b = Lamp activated (On)
10b = Error
11b = Not available";
CM_ SG_ 2566718718 OptionalLamp4Data "This parameter provides measured data from Optional Lamp #4. Optional lamps are those that are configured for a specific application.

00b = Lamp deactivated (Off)
01b = Lamp activated (On)
10b = Error
11b = Not available";
CM_ SG_ 2566718718 OptionalLamp3Data "This parameter provides measured data from Optional Lamp #3. Optional lamps are those that are configured for a specific application.

00b = Lamp deactivated (Off)
01b = Lamp activated (On)
10b = Error
11b = Not available";
CM_ SG_ 2566718718 OptionalLamp2Data "This parameter provides measured data from Optional Lamp #2. Optional lamps are those that are configured for a specific application.

00b = Lamp deactivated (Off)
01b = Lamp activated (On)
10b = Error
11b = Not available";
CM_ SG_ 2566718718 OptionalLamp1Data "This parameter provides measured data from Optional Lamp #1. Optional lamps are those that are configured for a specific application.

00b = Lamp deactivated (Off)
01b = Lamp activated (On)
10b = Error
11b = Not available";
CM_ SG_ 2566718718 SecondAirPressLowLamp "This parameter provides measured data from the Secondary Air Pressure Lamp.

00b = Lamp deactivated (Off)
01b = Lamp activated (On)
10b = Error
11b = Not available";
CM_ SG_ 2566718718 PrimaryAirPressLowLamp "This parameter provides measured data from the Primary Air Pressure Lamp.

00b = Lamp deactivated (Off)
01b = Lamp activated (On)
10b = Error
11b = Not available";
CM_ SG_ 2566718718 VehLimPerformanceModeLamp "This parameter provides measured data from the Vehicle Limited Performance Mode Lamp.
Vehicle limited performance mode is when a derate is active, for example.
00b = Lamp deactivated (Off)
01b = Lamp activated (On)
10b = Error
11b = Not ...";
CM_ SG_ 2566718718 HillHolderLampData "This message will be transmitted by the controller that is illuminating the lamps.

00b = Lamp deactivated (Off)
01b = Lamp activated (On)
10b = Error
11b = Not Available";
CM_ SG_ 2566718718 VehicleBatteryChargingLampData "This parameter provides measured data from the Vehicle Battery Charging Lamp.

00b = Lamp deactivated (Off)
01b = Lamp activated (On)
10b = Error
11b = Not available";
CM_ SG_ 2566718718 VehicleHVACRecirculationLampData "This parameter provides measured data from the Vehicle HVAC Recirculation Lamp.

00b = Lamp deactivated (Off)
01b = Lamp activated (On)
10b = Error
11b = Not available";
CM_ SG_ 2566718718 VehicleAirPressLowLampData "This parameter provides measured data from the Vehicle Air Pressure Low Lamp.

00b = Lamp deactivated (Off)
01b = Lamp activated (On)
10b = Error
11b = Not available";
CM_ SG_ 2566718718 VehicleFuelLevelLowLampData "This parameter provides measured data from the Vehicle Fuel Level Low Lamp.

00b = Lamp deactivated (Off)
01b = Lamp activated (On)
10b = Error
11b = Not available";
CM_ SG_ 2566718718 VehicleBatteryVoltageLowLampData "This parameter provides measured data from the Vehicle Battery Voltage Low Lamp.

00b = Lamp deactivated (Off)
01b = Lamp activated (On)
10b = Error
11b = Not available";
CM_ BO_ 2566718974 "Direct Lamp Control Data 1
This message will be transmitted by the controller that is illuminating the lamps.

It is not required to be used with PGN 64775.";
CM_ SG_ 2566718974 EngSvcLamp "This parameter provides measured data from the Engine Service Lamp.

00b = Lamp deactivated (Off)
01b = Lamp activated (On)
10b = Error
11b = Not available";
CM_ SG_ 2566718974 EngAirShutoffLamp "This parameter provides measured data from the Engine Air Shutoff Lamp.

00b = Lamp Deactivated (Off)
01b = Lamp Activated (On)
10b = Error
11b = Not available";
CM_ SG_ 2566718974 EngIntercoolerTempHiLamp "This parameter provides measured data from the Engine Intercooler Temperature Lamp.

00b = Lamp deactivated (Off)
01b = Lamp activated (On)
10b = Error
11b = Not available";
CM_ SG_ 2566718974 EngFuelTempHiLamp "This parameter provides measured data from the Engine Fuel Temperature Lamp.

00b = Lamp deactivated (Off)
01b = Lamp activated (On)
10b = Error
11b = Not available";
CM_ SG_ 2566718974 EngOilTempHiLamp "This parameter provides measured data from the Engine Oil Temperature Lamp.

00b = Lamp deactivated (Off)
01b = Lamp activated (On)
10b = Error
11b = Not available";
CM_ SG_ 2566718974 EngStopStartEnabledLamp "Provides measured data from the engine stop-start enabled lamp.

00b = Lamp deactivated (Off)
01b = Lamp activated (On)
10b = Error
11b = Not available";
CM_ SG_ 2566718974 EngStopStartAutoStartFailedLamp "Provides measured data from the engine stop-start automatic start failed lamp.

00b = Lamp deactivated (Off)
01b = Lamp activated (On)
10b = Error
11b = Not available";
CM_ SG_ 2566718974 EngStopStartAutoStopActiveLamp "Provides measured data from the engine stop-start automatic stop active lamp.

00b = Lamp deactivated (Off)
01b = Lamp activated (On)
10b = Error
11b = Not available";
CM_ SG_ 2566718974 VhclAcclerationRateLimitLampData "This parameter provides measured data from the Vehicle Acceleration Rate Limit Lamp.

00b = Lamp deactivated (Off)
01b = Lamp activated (On)
10b = Error
11b = Not available";
CM_ SG_ 2566718974 EngSpeedVeryHighLampData "This parameter provides measured data from the Engine Speed Very High Warning Lamp.

00b = Lamp Deactivated (Off)
01b = Lamp Activated (On)
10b = Error
11b = Not available";
CM_ SG_ 2566718974 EngSpeedHighLampData "This parameter provides measured data from the Engine Speed High Warning Lamp.

00b = Lamp Deactivated (Off)
01b = Lamp Activated (On)
10b = Error
11b = Not available";
CM_ SG_ 2566718974 EngCtrlMdule3ReadyForUseLampData "This parameter provides measured data from the Engine Control Module 3 Ready for Use Lamp.

00b = Lamp deactivated (Off)
01b = Lamp activated (On)
10b = Error
11b = Not Available";
CM_ SG_ 2566718974 EngCtrlMdule2ReadyForUseLampData "This parameter provides measured data from the Engine Control Module 2 Ready for Use Lamp.

00b = Lamp deactivated (Off)
01b = Lamp activated (On)
10b = Error
11b = Not Available";
CM_ SG_ 2566718974 EngCtrlMdule1ReadyForUseLampData "This parameter provides measured data from the Engine Control Module 1 Ready for Use Lamp.

00b = Lamp deactivated (Off)
01b = Lamp activated (On)
10b = Error
11b = Not Available";
CM_ SG_ 2566718974 EngWaitToStartLampData "This parameter provides measured data from the Engine Wait To Start Lamp.  See SPN 1081 for the command.

00b = Lamp deactived (off)
01b = Lamp actived (on)
10b = Error
11b = Not available";
CM_ SG_ 2566718974 EngFuelFilterRestrictedLampData "This parameter provides measured data from the Engine Fuel Filter Restricted Lamp.

00b = Lamp deactivated (Off)
01b = Lamp activated (On)
10b = Error
11b = Not available";
CM_ SG_ 2566718974 EngAirFilterRestrictionLampData "This parameter provides measured data from the Engine Air Filter Restriction Lamp.

00b = Lamp deactivated (Off)
01b = Lamp activated (On)
10b = Error
11b = Not available";
CM_ SG_ 2566718974 EngIdleManagementActiveLampData "This parameter provides measured data from the Engine Idle Management Active Lamp.

00b = Lamp deactivated (Off)
01b = Lamp activated (On)
10b = Error
11b = Not available";
CM_ SG_ 2566718974 EngCoolantLevelLowLampData "This parameter provides measured data from the Engine Coolant Level Low Lamp.

00b = Lamp deactivated (Off)
01b = Lamp activated (On)
10b = Error
11b = Not available";
CM_ SG_ 2566718974 EngCoolantTempHighLampData "This parameter provides measured data from the Engine Coolant Temperature High Lamp.

00b = Lamp deactivated (Off)
01b = Lamp activated (On)
10b = Error
11b = Not available";
CM_ SG_ 2566718974 EngOilPressLowLampData "This parameter provides measured data from the Engine Oil Pressure Low Lamp.

00b = Lamp deactivated (Off)
01b = Lamp activated (On)
10b = Error
11b = Not available";
CM_ SG_ 2566718974 CmprssnBrkEnblSwtchIndctrLmpData "This parameter provides measured data from the Compression Brake Enable Switch Indicator Lamp.

00b = Lamp deactivated (Off)
01b = Lamp activated (On)
10b = Error
11b = Not available";
CM_ SG_ 2566718974 EngBrakeActiveLampData "This parameter provides measured data from the Engine Brake Active Lamp.

00b = Lamp deactivated (Off)
01b = Lamp activated (On)
10b = Error
11b = Not available";
CM_ SG_ 2566718974 OBDMalfunctionIndicatorLampData "This parameter provides measured data from the OBD Malfunction Indicator Lamp.

00b = Lamp deactivated (Off)
01b = Lamp activated (On)
10b = Error
11b = Not available";
CM_ SG_ 2566718974 EngRedStopLampData "This parameter provides measured data from the Engine Red Stop Lamp.

00b = Lamp deactivated (Off)
01b = Lamp activated (On)
10b = Error
11b = Not available";
CM_ SG_ 2566718974 EngAmberWarningLampData "This parameter provides measured data from the Engine Amber Warning Lamp.

00b = Lamp deactivated (Off)
01b = Lamp activated (On)
10b = Error
11b = Not available";
CM_ SG_ 2566718974 EngProtectLampData "This parameter provides measured data from the Engine Protect Lamp.

00b = Lamp deactivated (Off)
01b = Lamp activated (On)
10b = Error
11b = Not available";
CM_ BO_ 2566719230 "Direct Lamp Control Command 2
Message that directly controls the driver indicator lamps.   See also PGN 64775 for additional lamps and PGN 64772 for the feedback information about these lamps.
Note: Since this message is direct lamp control, it is ...";
CM_ SG_ 2566719230 OptionalLamp6Cmd "Command signal directly controlling Optional Lamp #6. Optional lamps are those that are configured for a specific application.

00b = Lamp Off
01b = Lamp On
10b = Reserved
11b = Not available";
CM_ SG_ 2566719230 OptionalLamp5Cmd "Command signal directly controlling Optional Lamp #5. Optional lamps are those that are configured for a specific application.

00b = Lamp Off
01b = Lamp On
10b = Reserved
11b = Not available";
CM_ SG_ 2566719230 OptionalLamp4Cmd "Command signal directly controlling Optional Lamp #4. Optional lamps are those that are configured for a specific application.

00b = Lamp Off
01b = Lamp On
10b = Reserved
11b = Not available";
CM_ SG_ 2566719230 OptionalLamp3Cmd "Command signal directly controlling Optional Lamp #3. Optional lamps are those that are configured for a specific application.

00b = Lamp Off
01b = Lamp On
10b = Reserved
11b = Not available";
CM_ SG_ 2566719230 OptionalLamp2Cmd "Command signal directly controlling Optional Lamp #2. Optional lamps are those that are configured for a specific application.

00b = Lamp Off
01b = Lamp On
10b = Reserved
11b = Not available";
CM_ SG_ 2566719230 OptionalLamp1Cmd "Command signal directly controlling Optional Lamp #1. Optional lamps are those that are configured for a specific application.

00b = Lamp Off
01b = Lamp On
10b = Reserved
11b = Not available";
CM_ SG_ 2566719230 SecondAirPressLowLamp "Command signal directly controlling the Secondary Air Pressure Lamp.

00b = Lamp Off
01b = Lamp On
10b = Reserved
11b = Not available";
CM_ SG_ 2566719230 PrimaryAirPressLowLamp "Command signal directly controlling the Primary Air Pressure Lamp.

00b = Lamp Off
01b = Lamp On
10b = Reserved
11b = Not available";
CM_ SG_ 2566719230 VehLimPerformanceModeLamp "Command signal directly controlling the vehicle limited performance mode lamp.

Vehicle limited performance mode is when a derate is active, for example.

00b = Lamp Off
01b = Lamp On
10b = Reserved
11b = Not available";
CM_ SG_ 2566719230 HillHolderLampCmd "Command signal directly controlling Hill Holder Lamp.

00b = Lamp Off
01b = Lamp On
10b = Lamp Flash (1 Hz)
11b = Not available";
CM_ SG_ 2566719230 VehicleBatteryChargingLampCmd "Command signal directly controlling the Vehicle Battery Charging Lamp.

00b = Lamp Off
01b = Lamp On
10b = Reserved
11b = Not available";
CM_ SG_ 2566719230 VehicleHVACRecirculationLampCmd "Command signal directly controlling the Vehicle HVAC Recirculation Lamp.

00b = Lamp Off
01b = Lamp On
10b = Reserved
11b = Not available";
CM_ SG_ 2566719230 VehicleAirPressLowLampCmd "Command signal directly controlling the Vehicle Air Pressure Low Lamp.

00b = Lamp Off
01b = Lamp On
10b = Reserved
11b = Not available";
CM_ SG_ 2566719230 VehicleFuelLevelLowLampCmd "Command signal directly controlling the Vehicle Fuel Level Low Lamp.

00b = Lamp Off
01b = Lamp On
10b = Reserved
11b = Not available";
CM_ SG_ 2566719230 VehicleBatteryVoltageLowLampCmd "Command signal directly controlling the Vehicle Battery Voltage Low Lamp.

00b = Lamp Off
01b = Lamp On
10b = Reserved
11b = Not available";
CM_ BO_ 2560818942 "Regulated Exhaust Emission Level Exceedance
Provides the DTCs and associated timers related to a regulated exhaust emission level exceedance due to an emission control system malfunction.";
CM_ SG_ 2560818942 SPN1 "This 19-bit number is used to identify the item for which diagnostics are being reported.";
CM_ SG_ 2560818942 FailureModeIdentifier1 "The FMI defines the type of failure detected in the subsystem identified by an SPN.";
CM_ SG_ 2560818942 DTCTimeUntilDerate "This timer provides the number of hours the malfunction has until the OBD required derate will occur";
CM_ SG_ 2560818942 DTCTotalPreviouslyActiveTime "This timer provides the number of hours the NOx malfunction has been confirmed and previously active";
CM_ SG_ 2560818942 DTCTotalActiveTime "This timer provides the total number of hours the DTC has been confirmed and active";
CM_ SG_ 2560818942 SPN1High "SPN #1 (Conversion Version 4)";
CM_ BO_ 2561212158 "Text Display
This provides ASCII text information, for example to an display instrument.  Broadcast rate should be on event and 1-5 seconds due to variable character length.  This message is to convey information from an ecu to a display.  In its ...";
CM_ SG_ 2561212158 TextDisplayIndex "Used for overwriting consecutive bytes of a displayed string when byte 1 \"Text Display Instructions\" state is set for \"overwrite substring\" mode.  When used, this byte declares where in the text string that the new text will start overwriting, this ...";
CM_ SG_ 2561212158 TextDisplayInstructions "This parameter describes the status for the display how to show the information.
0000b = Clear display - The displayed information should be deleted or not displayed any more.
0001b = Hold display - The presently displayed information should be ...";
CM_ BO_ 2566746366 "Door ramp control
This message reports the current status of door ramps";
CM_ SG_ 2566746366 RetractStatusOfRamp5 "Retract status of ramp at doorway 5, counting from front to back on the vehicle.
00b = ramp retracted
01b = ramp extended
10b = error
11b = not available";
CM_ SG_ 2566746366 RetractStatusOfRamp4 "Retract status of ramp at doorway 4, counting from front to back on the vehicle.
00b = ramp retracted
01b = ramp extended
10b = error
11b = not available";
CM_ SG_ 2566746366 MovementStatusOfRamp5 "Movement status of ramp at doorway 5, counting from front to back on the vehicle.

00b = ramp not being moved
01b = ramp being moved
10b = error
11b = not available";
CM_ SG_ 2566746366 MovementStatusOfRamp4 "Movement status of ramp at doorway 4, counting from front to back on the vehicle.

00b = ramp not being moved
01b = ramp being moved
10b = error
11b = not available";
CM_ SG_ 2566746366 EnableStatusOfRamp5 "Enable status of ramp at doorway 5, counting from front to back on the vehicle.

00b = ramp disabled
01b = ramp enabled 
10b = error 
11b = not available";
CM_ SG_ 2566746366 EnableStatusOfRamp4 "Enable status of ramp at doorway 4, counting from front to back on the vehicle.

00b = ramp disabled
01b = ramp enabled 
10b = error 
11b = not available";
CM_ SG_ 2566746366 MovementStatusOfRamp3 "Movement status of ramp at doorway 3, counting from front to back on the vehicle.

00b = ramp not being moved
01b = ramp being moved
10b = error
11b = not available";
CM_ SG_ 2566746366 EnableStatusOfRamp3 "Enable status of ramp at doorway 3, counting from front to back on the vehicle.

00b = ramp disabled
01b = ramp enabled 
10b = error 
11b = not available";
CM_ SG_ 2566746366 RetractStatusOfRamp3 "Retract status of ramp at doorway 3, counting from front to back on the vehicle.

00b = ramp retracted
01b = ramp extended
10b = error
11b = not available";
CM_ SG_ 2566746366 MovementStatusOfRamp2 "Movement status of ramp at doorway 2, counting from front to back on the vehicle.

00b = ramp not being moved
01b = ramp being moved
10b = error
11b = not available";
CM_ SG_ 2566746366 EnableStatusOfRamp2 "Enable status of ramp at doorway 2, counting from front to back on the vehicle.

00b = ramp disabled
01b = ramp enabled 
10b = error 
11b = not available";
CM_ SG_ 2566746366 RetractStatusOfRamp2 "Retract status of ramp at doorway 2, counting from front to back on the vehicle.

00b = ramp retracted
01b = ramp extended
10b = error
11b = not available";
CM_ SG_ 2566746366 MovementStatusOfRamp1 "Movement status of ramp at doorway 1, counting from front to back on the vehicle.

00b = ramp not being moved
01b = ramp being moved
10b = error
11b = not available";
CM_ SG_ 2566746366 EnableStatusOfRamp1 "Enable status of ramp at doorway 1, counting from front to back on the vehicle.

00b = ramp disabled
01b = ramp enabled 
10b = error 
11b = not available";
CM_ SG_ 2566746366 RetractStatusOfRamp1 "Retract status of ramp at doorway 1, counting from front to back on the vehicle.
00b = ramp retracted
01b = ramp extended
10b = error
11b = not available";
CM_ BO_ 2566750206 "Engine Configuration 2
Contains static information about the engine.  To be used with data that will not change during vehicle operation.
.";
CM_ SG_ 2566750206 TransIdleGovFuelingInhSupport "Companion parameter to \"Transmission Idle Governor Fueling Inhibit\" (SPN 7829). This \"configuration\" parameter provides confirmation to the Transmission that the engine supports the \"Transmission Idle Governor Fueling Inhibit\" feature.
00b = ...";
CM_ SG_ 2566750206 EngConfigIdentification "Used to identify the hardware configuration of engine family. Each number will have a reference to set of parameters such as, but not limited to, number of cylinders, piston displacement, bore size and firing angles.";
CM_ SG_ 2566750206 NmbrOfCmbstionCyclesForAveraging "Defined number of combustion cycles used for calculating average parameters of combustion in each cylinder.";
CM_ SG_ 2566750206 MaxCrankAttemptsPerStartAttempt "The number of cranking cycles that will be performed before ending the start attempt.  This is intended to be used in conjunction with Crank Attempt Count on Present Start Attempt, in order to give a FMI 0 diagnostic on the latter.";
CM_ BO_ 2566755582 "Electronic Engine Controller 7
Engine related parameters";
CM_ SG_ 2566755582 CommandedEngIntakeManifoldPress "Provides the commanded set point value for the engine intake manifold pressure.";
CM_ SG_ 2566755582 EngCrnkcsBrtherOilSeparatorSpeed "The speed of a rotating (centrifugal) crankcase oil separator.";
CM_ SG_ 2566755582 EngExhstGsRcirculation1Valve2Pos "The position of the second exhaust gas recirculation valve expressed as a percentage of full travel. Zero percent means the valve is closed and no exhaust gas is flowing into the intake air stream. One hundred percent means the valve is fully ...";
CM_ SG_ 2566755582 EngExhstGsRecirculation1ValvePos "The position of the exhaust gas recirculation valve expressed as a percentage of full travel. Zero percent means the valve is closed and no exhaust gas is flowing into the intake air stream. One hundred percent means the valve is fully opened.";
CM_ BO_ 2566746110 "Electronic Engine Controller 8
Engine related parameters";
CM_ SG_ 2566746110 EGRAftercoolerInletCoolantTemp "The temperature of the coolant found at the inlet of the exhaust gas recirculation systems aftercooler.";
CM_ SG_ 2566746110 EngExhstGsRcrcltn1ClerEfficiency "Exhaust Gas Recirculation cooler efficiency is an indication of the cooler’s ability to reduce the temperature of the exhaust gas that is being recirculated back to the intake. 0% = no reduction in temperature, 100% = maximum cooling.  The EGR ...";
CM_ SG_ 2566746110 EngExhstGsRcrcltn1ClrIntkGsAbsPr "Exhaust gas recirculation absolute pressure is measured at the EGR cooler intake. See SPN 3358 for EGR pressure measured at the EGR cooler outlet before the valve.";
CM_ SG_ 2566746110 EngExhstGsRcrcltn1ClerIntakeTemp "Exhaust Gas Recirculation (EGR) Temperature measured at the EGR cooler intake.  See SPN 412 for Engine EGR temperature which is typically measured at the EGR cooler outlet.";
CM_ SG_ 2566746110 EngExhstGsRcrculation1Valve2Ctrl "Desired percentage of maximum Exhaust Gas Recirculation (EGR) valve opening for valve 2.  0% means valve is closed. 100% means maximum valve opening (full gas flow).";
BA_DEF_ SG_  "GenSigInactiveValue" INT 0 0;
BA_DEF_ SG_  "SigType" ENUM  "Default","Range","RangeSigned","ASCII","Discrete","Control","ReferencePGN","DTC","StringDelimiter","StringLength","StringLengthControl","MessageCounter","MessageChecksum";
BA_DEF_ SG_  "GenSigStartValue" INT 0 2147483647;
BA_DEF_ SG_  "GenSigSendType" ENUM  "Cyclic","OnWrite","OnWriteWithRepetition","OnChange","OnChangeWithRepetition","IfActive","IfActiveWithRepetition","NoSigSendType";
BA_DEF_ SG_  "GenSigILSupport" ENUM  "No","Yes";
BA_DEF_ SG_  "SPN" INT 0 524287;
BA_DEF_ BO_  "J1939CPgSendTimeout" INT -1 3600000;
BA_DEF_ BO_  "J1939CPgTOS" INT 0 7;
BA_DEF_ BO_  "J1939PgAppearanceOnBus" ENUM  "Default","CAN_Extended","CANFD_Extended";
BA_DEF_ BO_  "FsJ1939UseCrcAndCounter" STRING ;
BA_DEF_ BO_  "TpJ1939VarDlc" ENUM  "No","Yes";
BA_DEF_ BO_  "GenMsgNrOfRepetition" INT 0 1000000;
BA_DEF_ BO_  "GenMsgCycleTimeFast" INT 0 3600000;
BA_DEF_ BO_  "GenMsgFastOnStart" INT 0 100000;
BA_DEF_ BO_  "GenMsgStartDelayTime" INT 0 100000;
BA_DEF_ BO_  "GenMsgILSupport" ENUM  "No","Yes";
BA_DEF_ BO_  "GenMsgDelayTime" INT 0 1000;
BA_DEF_ BO_  "GenMsgRequestable" INT 0 1;
BA_DEF_ BO_  "GenMsgSendType" ENUM  "cyclic","NotUsed","NotUsed","NotUsed","NotUsed","NotUsed","NotUsed","IfActive","noMsgSendType";
BA_DEF_ BO_  "VFrameFormat" ENUM  "StandardCAN","ExtendedCAN","reserved","J1939PG","reserved","reserved","reserved","reserved","reserved","reserved","reserved","reserved","reserved","reserved","StandardCAN_FD","ExtendedCAN_FD";
BA_DEF_ BO_  "SingleFrame" INT 0 1;
BA_DEF_ BO_  "GenMsgCycleTime" INT 0 3600000;
BA_DEF_ SG_  "SystemSignalLongSymbol" STRING ;
BA_DEF_DEF_  "GenSigInactiveValue" 0;
BA_DEF_DEF_  "SigType" "Default";
BA_DEF_DEF_  "GenSigStartValue" 0;
BA_DEF_DEF_  "GenSigSendType" "NoSigSendType";
BA_DEF_DEF_  "GenSigILSupport" "Yes";
BA_DEF_DEF_  "SPN" 0;
BA_DEF_DEF_  "J1939CPgSendTimeout" -1;
BA_DEF_DEF_  "J1939CPgTOS" 2;
BA_DEF_DEF_  "J1939PgAppearanceOnBus" "Default";
BA_DEF_DEF_  "FsJ1939UseCrcAndCounter" "";
BA_DEF_DEF_  "TpJ1939VarDlc" "No";
BA_DEF_DEF_  "GenMsgNrOfRepetition" 0;
BA_DEF_DEF_  "GenMsgCycleTimeFast" 0;
BA_DEF_DEF_  "GenMsgFastOnStart" 0;
BA_DEF_DEF_  "GenMsgStartDelayTime" 0;
BA_DEF_DEF_  "GenMsgILSupport" "Yes";
BA_DEF_DEF_  "GenMsgDelayTime" 0;
BA_DEF_DEF_  "GenMsgRequestable" 1;
BA_DEF_DEF_  "GenMsgSendType" "noMsgSendType";
BA_DEF_DEF_  "VFrameFormat" "J1939PG";
BA_DEF_DEF_  "SingleFrame" 1;
BA_DEF_DEF_  "GenMsgCycleTime" 0;
BA_DEF_DEF_  "SystemSignalLongSymbol" "";
BA_ "GenMsgSendType" BO_ 2566713854 0;
BA_ "GenMsgCycleTime" BO_ 2566713854 100;
BA_ "GenMsgSendType" BO_ 2566714366 0;
BA_ "GenMsgCycleTime" BO_ 2566714366 100;
BA_ "GenMsgSendType" BO_ 2566714110 0;
BA_ "GenMsgCycleTime" BO_ 2566714110 100;
BA_ "GenMsgSendType" BO_ 2566717438 0;
BA_ "GenMsgCycleTime" BO_ 2566717438 1000;
BA_ "GenMsgSendType" BO_ 2633828606 0;
BA_ "GenMsgCycleTime" BO_ 2633828606 30000;
BA_ "GenMsgDelayTime" BO_ 2365400574 20;
BA_ "GenMsgSendType" BO_ 2365400574 0;
BA_ "GenMsgCycleTime" BO_ 2365400574 100;
BA_ "GenMsgDelayTime" BO_ 2365401086 20;
BA_ "GenMsgSendType" BO_ 2365401086 0;
BA_ "GenMsgCycleTime" BO_ 2365401086 100;
BA_ "GenMsgDelayTime" BO_ 2365401598 20;
BA_ "GenMsgSendType" BO_ 2365401598 0;
BA_ "GenMsgCycleTime" BO_ 2365401598 100;
BA_ "GenMsgDelayTime" BO_ 2365402110 20;
BA_ "GenMsgSendType" BO_ 2365402110 0;
BA_ "GenMsgCycleTime" BO_ 2365402110 100;
BA_ "GenMsgDelayTime" BO_ 2365402622 20;
BA_ "GenMsgSendType" BO_ 2365402622 0;
BA_ "GenMsgCycleTime" BO_ 2365402622 100;
BA_ "GenMsgDelayTime" BO_ 2365403134 20;
BA_ "GenMsgSendType" BO_ 2365403134 0;
BA_ "GenMsgCycleTime" BO_ 2365403134 100;
BA_ "GenMsgDelayTime" BO_ 2365400062 20;
BA_ "GenMsgSendType" BO_ 2365400062 0;
BA_ "GenMsgCycleTime" BO_ 2365400062 100;
BA_ "GenMsgSendType" BO_ 2566713598 0;
BA_ "GenMsgCycleTime" BO_ 2566713598 500;
BA_ "GenMsgSendType" BO_ 2499604478 0;
BA_ "GenMsgCycleTime" BO_ 2499604478 500;
BA_ "GenMsgSendType" BO_ 2499608830 0;
BA_ "GenMsgCycleTime" BO_ 2499608830 500;
BA_ "GenMsgSendType" BO_ 2432499198 0;
BA_ "GenMsgCycleTime" BO_ 2432499198 100;
BA_ "GenMsgDelayTime" BO_ 2566711294 500;
BA_ "GenMsgSendType" BO_ 2566711294 0;
BA_ "GenMsgCycleTime" BO_ 2566711294 5000;
BA_ "GenMsgDelayTime" BO_ 2566749438 100;
BA_ "GenMsgSendType" BO_ 2566749438 0;
BA_ "GenMsgCycleTime" BO_ 2566749438 1000;
BA_ "GenMsgSendType" BO_ 2566715646 0;
BA_ "GenMsgCycleTime" BO_ 2566715646 1000;
BA_ "GenMsgSendType" BO_ 2566724606 0;
BA_ "GenMsgCycleTime" BO_ 2566724606 1000;
BA_ "GenMsgSendType" BO_ 2566715902 0;
BA_ "GenMsgCycleTime" BO_ 2566715902 1000;
BA_ "GenMsgSendType" BO_ 2566724862 0;
BA_ "GenMsgCycleTime" BO_ 2566724862 1000;
BA_ "GenMsgSendType" BO_ 2566718718 0;
BA_ "GenMsgCycleTime" BO_ 2566718718 1000;
BA_ "GenMsgSendType" BO_ 2566718974 0;
BA_ "GenMsgCycleTime" BO_ 2566718974 1000;
BA_ "GenMsgDelayTime" BO_ 2566719230 100;
BA_ "GenMsgSendType" BO_ 2566719230 0;
BA_ "GenMsgCycleTime" BO_ 2566719230 1000;
BA_ "TpJ1939VarDlc" BO_ 2560818942 1;
BA_ "TpJ1939VarDlc" BO_ 2561212158 1;
BA_ "GenMsgDelayTime" BO_ 2566746366 100;
BA_ "GenMsgCycleTime" BO_ 2566746366 1000;
BA_ "GenMsgSendType" BO_ 2566755582 0;
BA_ "GenMsgCycleTime" BO_ 2566755582 100;
BA_ "SigType" SG_ 2566713854 EngExhaustBackPressActuator1Temp 1;
BA_ "SPN" SG_ 2566713854 EngExhaustBackPressActuator1Temp 5790;
BA_ "SigType" SG_ 2566713854 EngExhstBckPrssActtor1DesiredPos 1;
BA_ "SPN" SG_ 2566713854 EngExhstBckPrssActtor1DesiredPos 5789;
BA_ "SigType" SG_ 2566713854 EngTurboWastegateActuator1Temp 1;
BA_ "SPN" SG_ 2566713854 EngTurboWastegateActuator1Temp 5788;
BA_ "SPN" SG_ 2566713854 EngExhstBckPrssRgltrCtrlOprtnStt 5628;
BA_ "SPN" SG_ 2566713854 EngExhstBckPrssRglatorTempStatus 5627;
BA_ "SPN" SG_ 2566713854 EngExhstBckPrssRgltrPrlminaryFMI 5626;
BA_ "SigType" SG_ 2566713854 EngExhaustBackPressRegulatorPos 1;
BA_ "SPN" SG_ 2566713854 EngExhaustBackPressRegulatorPos 5625;
BA_ "SPN" SG_ 2566713854 EngTrbWstgtActtr2OperationStatus 5452;
BA_ "SPN" SG_ 2566713854 EngTrbWstgtActtr1OperationStatus 5451;
BA_ "SPN" SG_ 2566713854 EngTrbWstgateActuator2TempStatus 5385;
BA_ "SPN" SG_ 2566713854 EngTrbWstgtActtor2PreliminaryFMI 5384;
BA_ "SigType" SG_ 2566714366 EngTrbCmprssrBypassActuator2Temp 1;
BA_ "SPN" SG_ 2566714366 EngTrbCmprssrBypassActuator2Temp 5792;
BA_ "SigType" SG_ 2566714366 EngTrbCmprssrBypassActuator1Temp 1;
BA_ "SPN" SG_ 2566714366 EngTrbCmprssrBypassActuator1Temp 5791;
BA_ "SPN" SG_ 2566714366 EngTrbCmprssrBypssActtr2OprtnStt 5450;
BA_ "SPN" SG_ 2566714366 EngTrbCmprssrBypssActtr1OprtnStt 5449;
BA_ "SPN" SG_ 2566714366 EngTrbCmprssrBypssActtr2TmpSttus 5391;
BA_ "SPN" SG_ 2566714366 EngTrbCmprssrBypssActtr2PrlmnryF 5390;
BA_ "SigType" SG_ 2566714366 EngDsrdTrbCmprssrBypssActtor2Pos 1;
BA_ "SPN" SG_ 2566714366 EngDsrdTrbCmprssrBypssActtor2Pos 5389;
BA_ "SigType" SG_ 2566714366 EngTrbCmprssorBypassActuator2Pos 1;
BA_ "SPN" SG_ 2566714366 EngTrbCmprssorBypassActuator2Pos 5388;
BA_ "SPN" SG_ 2566714110 EngFuelValve2OperationStatus 5448;
BA_ "SPN" SG_ 2566714110 EngFuelValve1OperationStatus 5447;
BA_ "SPN" SG_ 2566714110 EngThrottleValve2OperationStatus 5446;
BA_ "SPN" SG_ 2566714110 EngThrottleValve1OperationStatus 5445;
BA_ "SPN" SG_ 2566714110 EngFuelValve2TempStatus 5383;
BA_ "SPN" SG_ 2566714110 EngFuelValve2PreliminaryFMI 5382;
BA_ "SPN" SG_ 2566714110 EngFuelValve1TempStatus 5381;
BA_ "SPN" SG_ 2566714110 EngFuelValve1PreliminaryFMI 5380;
BA_ "SPN" SG_ 2566714110 EngThrottleValve2TempStatus 5379;
BA_ "SPN" SG_ 2566714110 EngThrottleValve2PreliminaryFMI 5378;
BA_ "SigType" SG_ 2566714110 EngDesiredThrottleValve2Pos 1;
BA_ "SPN" SG_ 2566714110 EngDesiredThrottleValve2Pos 5377;
BA_ "SPN" SG_ 2566714110 EngThrottleValve1TempStatus 5376;
BA_ "SPN" SG_ 2566714110 EngThrottleValve1PreliminaryFMI 5375;
BA_ "SigType" SG_ 2566714110 EngDesiredThrottleValve1Pos 1;
BA_ "SPN" SG_ 2566714110 EngDesiredThrottleValve1Pos 5374;
BA_ "SigType" SG_ 2566717438 CoolantTemp2 1;
BA_ "SPN" SG_ 2566717438 CoolantTemp2 22743;
BA_ "SigType" SG_ 2566717438 EngExhstGsRcrcltn2MxerIntakeTemp 1;
BA_ "SPN" SG_ 2566717438 EngExhstGsRcrcltn2MxerIntakeTemp 5256;
BA_ "SigType" SG_ 2566717438 EngExhaustGasRecirculation2Temp 1;
BA_ "SPN" SG_ 2566717438 EngExhaustGasRecirculation2Temp 5255;
BA_ "SigType" SG_ 2633828606 EngOilTemp3 1;
BA_ "SPN" SG_ 2633828606 EngOilTemp3 5925;
BA_ "SigType" SG_ 2633828606 EngOilRelativeDielectricity 1;
BA_ "SPN" SG_ 2633828606 EngOilRelativeDielectricity 5468;
BA_ "SigType" SG_ 2633828606 EngOilDensity 1;
BA_ "SPN" SG_ 2633828606 EngOilDensity 5056;
BA_ "SigType" SG_ 2633828606 EngOilViscosity 1;
BA_ "SPN" SG_ 2633828606 EngOilViscosity 5055;
BA_ "SigType" SG_ 2499607550 EngExhstMnfldBnk2FlwBlncVlvActtr 1;
BA_ "SPN" SG_ 2499607550 EngExhstMnfldBnk2FlwBlncVlvActtr 5279;
BA_ "SigType" SG_ 2499607550 EngExhstMnfldBnk1FlwBlncVlvActtr 1;
BA_ "SPN" SG_ 2499607550 EngExhstMnfldBnk1FlwBlncVlvActtr 5277;
BA_ "SigType" SG_ 2633825534 EngExhstMnfldBnk2FlwBlncVlvActtr 1;
BA_ "SPN" SG_ 2633825534 EngExhstMnfldBnk2FlwBlncVlvActtr 5278;
BA_ "SigType" SG_ 2633825534 EngExhstMnfldBnk1FlwBlncVlvActtr 1;
BA_ "SPN" SG_ 2633825534 EngExhstMnfldBnk1FlwBlncVlvActtr 5276;
BA_ "SigType" SG_ 2365400574 Joystick9Button13PressedStatus 4;
BA_ "SPN" SG_ 2365400574 Joystick9Button13PressedStatus 6763;
BA_ "SigType" SG_ 2365400574 Joystick9Button14PressedStatus 4;
BA_ "SPN" SG_ 2365400574 Joystick9Button14PressedStatus 6764;
BA_ "SigType" SG_ 2365400574 Joystick9Button15PressedStatus 4;
BA_ "SPN" SG_ 2365400574 Joystick9Button15PressedStatus 6765;
BA_ "SigType" SG_ 2365400574 Joystick9Button16PressedStatus 4;
BA_ "SPN" SG_ 2365400574 Joystick9Button16PressedStatus 6766;
BA_ "SigType" SG_ 2365400574 Jystick9GripXAxisDetentPosStatus 4;
BA_ "SPN" SG_ 2365400574 Jystick9GripXAxisDetentPosStatus 4712;
BA_ "SigType" SG_ 2365400574 Jystick9GripYAxisDetentPosStatus 4;
BA_ "SPN" SG_ 2365400574 Jystick9GripYAxisDetentPosStatus 4711;
BA_ "SigType" SG_ 2365400574 Jystick9ThetaAxisDetentPosStatus 4;
BA_ "SPN" SG_ 2365400574 Jystick9ThetaAxisDetentPosStatus 4710;
BA_ "SPN" SG_ 2365400574 Joystick9ThetaAxisPos 4709;
BA_ "SigType" SG_ 2365400574 Jystck9ThtAxsClckwsPstvPosStatus 4;
BA_ "SPN" SG_ 2365400574 Jystck9ThtAxsClckwsPstvPosStatus 4708;
BA_ "SigType" SG_ 2365400574 Jystck9ThtAxsCntrClckwsNgtvPsStt 4;
BA_ "SPN" SG_ 2365400574 Jystck9ThtAxsCntrClckwsNgtvPsStt 4707;
BA_ "SigType" SG_ 2365400574 Jystck9ThetaAxisNeutralPosStatus 4;
BA_ "SPN" SG_ 2365400574 Jystck9ThetaAxisNeutralPosStatus 4706;
BA_ "SPN" SG_ 2365400574 Joystick9GripYAxisPos 4705;
BA_ "SigType" SG_ 2365400574 Jystck9GrpYAxsLvrFrwrdPstvPsStts 4;
BA_ "SPN" SG_ 2365400574 Jystck9GrpYAxsLvrFrwrdPstvPsStts 4704;
BA_ "SigType" SG_ 2365400574 Jystck9GrpYAxsLvrBckNgtvPsStatus 4;
BA_ "SPN" SG_ 2365400574 Jystck9GrpYAxsLvrBckNgtvPsStatus 4703;
BA_ "SigType" SG_ 2365400574 Jystck9GripYAxisNeutralPosStatus 4;
BA_ "SPN" SG_ 2365400574 Jystck9GripYAxisNeutralPosStatus 4702;
BA_ "SPN" SG_ 2365400574 Joystick9GripXAxisPos 4701;
BA_ "SigType" SG_ 2365400574 Jystck9GrpXAxsLvrRghtPstvPsSttus 4;
BA_ "SPN" SG_ 2365400574 Jystck9GrpXAxsLvrRghtPstvPsSttus 4700;
BA_ "SigType" SG_ 2365400574 Jystck9GrpXAxsLvrLftNgtvPsStatus 4;
BA_ "SPN" SG_ 2365400574 Jystck9GrpXAxsLvrLftNgtvPsStatus 4699;
BA_ "SigType" SG_ 2365400574 Jystck9GripXAxisNeutralPosStatus 4;
BA_ "SPN" SG_ 2365400574 Jystck9GripXAxisNeutralPosStatus 4698;
BA_ "SigType" SG_ 2365401086 Joystick8Button13PressedStatus 4;
BA_ "SPN" SG_ 2365401086 Joystick8Button13PressedStatus 6759;
BA_ "SigType" SG_ 2365401086 Joystick8Button14PressedStatus 4;
BA_ "SPN" SG_ 2365401086 Joystick8Button14PressedStatus 6760;
BA_ "SigType" SG_ 2365401086 Joystick8Button15PressedStatus 4;
BA_ "SPN" SG_ 2365401086 Joystick8Button15PressedStatus 6761;
BA_ "SigType" SG_ 2365401086 Joystick8Button16PressedStatus 4;
BA_ "SPN" SG_ 2365401086 Joystick8Button16PressedStatus 6762;
BA_ "SigType" SG_ 2365401086 Jystick8GripXAxisDetentPosStatus 4;
BA_ "SPN" SG_ 2365401086 Jystick8GripXAxisDetentPosStatus 4675;
BA_ "SigType" SG_ 2365401086 Jystick8GripYAxisDetentPosStatus 4;
BA_ "SPN" SG_ 2365401086 Jystick8GripYAxisDetentPosStatus 4674;
BA_ "SigType" SG_ 2365401086 Jystick8ThetaAxisDetentPosStatus 4;
BA_ "SPN" SG_ 2365401086 Jystick8ThetaAxisDetentPosStatus 4673;
BA_ "SPN" SG_ 2365401086 Joystick8ThetaAxisPos 4672;
BA_ "SigType" SG_ 2365401086 Jystck8ThtAxsClckwsPstvPosStatus 4;
BA_ "SPN" SG_ 2365401086 Jystck8ThtAxsClckwsPstvPosStatus 4671;
BA_ "SigType" SG_ 2365401086 Jystck8ThtAxsCntrClckwsNgtvPsStt 4;
BA_ "SPN" SG_ 2365401086 Jystck8ThtAxsCntrClckwsNgtvPsStt 4670;
BA_ "SigType" SG_ 2365401086 Jystck8ThetaAxisNeutralPosStatus 4;
BA_ "SPN" SG_ 2365401086 Jystck8ThetaAxisNeutralPosStatus 4669;
BA_ "SPN" SG_ 2365401086 Joystick8GripYAxisPos 4668;
BA_ "SigType" SG_ 2365401086 Jystck8GrpYAxsLvrFrwrdPstvPsStts 4;
BA_ "SPN" SG_ 2365401086 Jystck8GrpYAxsLvrFrwrdPstvPsStts 4667;
BA_ "SigType" SG_ 2365401086 Jystck8GrpYAxsLvrBckNgtvPsStatus 4;
BA_ "SPN" SG_ 2365401086 Jystck8GrpYAxsLvrBckNgtvPsStatus 4666;
BA_ "SigType" SG_ 2365401086 Jystck8GripYAxisNeutralPosStatus 4;
BA_ "SPN" SG_ 2365401086 Jystck8GripYAxisNeutralPosStatus 4665;
BA_ "SPN" SG_ 2365401086 Joystick8GripXAxisPos 4664;
BA_ "SigType" SG_ 2365401086 Jystck8GrpXAxsLvrRghtPstvPsSttus 4;
BA_ "SPN" SG_ 2365401086 Jystck8GrpXAxsLvrRghtPstvPsSttus 4663;
BA_ "SigType" SG_ 2365401086 Jystck8GrpXAxsLvrLftNgtvPsStatus 4;
BA_ "SPN" SG_ 2365401086 Jystck8GrpXAxsLvrLftNgtvPsStatus 4662;
BA_ "SigType" SG_ 2365401086 Jystck8GripXAxisNeutralPosStatus 4;
BA_ "SPN" SG_ 2365401086 Jystck8GripXAxisNeutralPosStatus 4661;
BA_ "SigType" SG_ 2365401598 Joystick7Button13PressedStatus 4;
BA_ "SPN" SG_ 2365401598 Joystick7Button13PressedStatus 6755;
BA_ "SigType" SG_ 2365401598 Joystick7Button14PressedStatus 4;
BA_ "SPN" SG_ 2365401598 Joystick7Button14PressedStatus 6756;
BA_ "SigType" SG_ 2365401598 Joystick7Button15PressedStatus 4;
BA_ "SPN" SG_ 2365401598 Joystick7Button15PressedStatus 6757;
BA_ "SigType" SG_ 2365401598 Joystick7Button16PressedStatus 4;
BA_ "SPN" SG_ 2365401598 Joystick7Button16PressedStatus 6758;
BA_ "SigType" SG_ 2365401598 Jystick7GripXAxisDetentPosStatus 4;
BA_ "SPN" SG_ 2365401598 Jystick7GripXAxisDetentPosStatus 4638;
BA_ "SigType" SG_ 2365401598 Jystick7GripYAxisDetentPosStatus 4;
BA_ "SPN" SG_ 2365401598 Jystick7GripYAxisDetentPosStatus 4637;
BA_ "SigType" SG_ 2365401598 Jystick7ThetaAxisDetentPosStatus 4;
BA_ "SPN" SG_ 2365401598 Jystick7ThetaAxisDetentPosStatus 4636;
BA_ "SPN" SG_ 2365401598 Joystick7ThetaAxisPos 4635;
BA_ "SigType" SG_ 2365401598 Jystck7ThtAxsClckwsPstvPosStatus 4;
BA_ "SPN" SG_ 2365401598 Jystck7ThtAxsClckwsPstvPosStatus 4634;
BA_ "SigType" SG_ 2365401598 Jystck7ThtAxsCntrClckwsNgtvPsStt 4;
BA_ "SPN" SG_ 2365401598 Jystck7ThtAxsCntrClckwsNgtvPsStt 4633;
BA_ "SigType" SG_ 2365401598 Jystck7ThetaAxisNeutralPosStatus 4;
BA_ "SPN" SG_ 2365401598 Jystck7ThetaAxisNeutralPosStatus 4632;
BA_ "SPN" SG_ 2365401598 Joystick7GripYAxisPos 4631;
BA_ "SigType" SG_ 2365401598 Jystck7GrpYAxsLvrFrwrdPstvPsStts 4;
BA_ "SPN" SG_ 2365401598 Jystck7GrpYAxsLvrFrwrdPstvPsStts 4630;
BA_ "SigType" SG_ 2365401598 Jystck7GrpYAxsLvrBckNgtvPsStatus 4;
BA_ "SPN" SG_ 2365401598 Jystck7GrpYAxsLvrBckNgtvPsStatus 4629;
BA_ "SigType" SG_ 2365401598 Jystck7GripYAxisNeutralPosStatus 4;
BA_ "SPN" SG_ 2365401598 Jystck7GripYAxisNeutralPosStatus 4628;
BA_ "SPN" SG_ 2365401598 Joystick7GripXAxisPos 4627;
BA_ "SigType" SG_ 2365401598 Jystck7GrpXAxsLvrRghtPstvPsSttus 4;
BA_ "SPN" SG_ 2365401598 Jystck7GrpXAxsLvrRghtPstvPsSttus 4626;
BA_ "SigType" SG_ 2365401598 Jystck7GrpXAxsLvrLftNgtvPsStatus 4;
BA_ "SPN" SG_ 2365401598 Jystck7GrpXAxsLvrLftNgtvPsStatus 4625;
BA_ "SigType" SG_ 2365401598 Jystck7GripXAxisNeutralPosStatus 4;
BA_ "SPN" SG_ 2365401598 Jystck7GripXAxisNeutralPosStatus 4624;
BA_ "SigType" SG_ 2365402110 Joystick6Button13PressedStatus 4;
BA_ "SPN" SG_ 2365402110 Joystick6Button13PressedStatus 6751;
BA_ "SigType" SG_ 2365402110 Joystick6Button14PressedStatus 4;
BA_ "SPN" SG_ 2365402110 Joystick6Button14PressedStatus 6752;
BA_ "SigType" SG_ 2365402110 Joystick6Button15PressedStatus 4;
BA_ "SPN" SG_ 2365402110 Joystick6Button15PressedStatus 6753;
BA_ "SigType" SG_ 2365402110 Joystick6Button16PressedStatus 4;
BA_ "SPN" SG_ 2365402110 Joystick6Button16PressedStatus 6754;
BA_ "SigType" SG_ 2365402110 Jystick6GripXAxisDetentPosStatus 4;
BA_ "SPN" SG_ 2365402110 Jystick6GripXAxisDetentPosStatus 4601;
BA_ "SigType" SG_ 2365402110 Jystick6GripYAxisDetentPosStatus 4;
BA_ "SPN" SG_ 2365402110 Jystick6GripYAxisDetentPosStatus 4600;
BA_ "SigType" SG_ 2365402110 Jystick6ThetaAxisDetentPosStatus 4;
BA_ "SPN" SG_ 2365402110 Jystick6ThetaAxisDetentPosStatus 4599;
BA_ "SPN" SG_ 2365402110 Joystick6ThetaAxisPos 4598;
BA_ "SigType" SG_ 2365402110 Jystck6ThtAxsClckwsPstvPosStatus 4;
BA_ "SPN" SG_ 2365402110 Jystck6ThtAxsClckwsPstvPosStatus 4597;
BA_ "SigType" SG_ 2365402110 Jystck6ThtAxsCntrClckwsNgtvPsStt 4;
BA_ "SPN" SG_ 2365402110 Jystck6ThtAxsCntrClckwsNgtvPsStt 4596;
BA_ "SigType" SG_ 2365402110 Jystck6ThetaAxisNeutralPosStatus 4;
BA_ "SPN" SG_ 2365402110 Jystck6ThetaAxisNeutralPosStatus 4595;
BA_ "SPN" SG_ 2365402110 Joystick6GripYAxisPos 4594;
BA_ "SigType" SG_ 2365402110 Jystck6GrpYAxsLvrFrwrdPstvPsStts 4;
BA_ "SPN" SG_ 2365402110 Jystck6GrpYAxsLvrFrwrdPstvPsStts 4593;
BA_ "SigType" SG_ 2365402110 Jystck6GrpYAxsLvrBckNgtvPsStatus 4;
BA_ "SPN" SG_ 2365402110 Jystck6GrpYAxsLvrBckNgtvPsStatus 4592;
BA_ "SigType" SG_ 2365402110 Jystck6GripYAxisNeutralPosStatus 4;
BA_ "SPN" SG_ 2365402110 Jystck6GripYAxisNeutralPosStatus 4591;
BA_ "SPN" SG_ 2365402110 Joystick6GripXAxisPos 4590;
BA_ "SigType" SG_ 2365402110 Jystck6GrpXAxsLvrRghtPstvPsSttus 4;
BA_ "SPN" SG_ 2365402110 Jystck6GrpXAxsLvrRghtPstvPsSttus 4589;
BA_ "SigType" SG_ 2365402110 Jystck6GrpXAxsLvrLftNgtvPsStatus 4;
BA_ "SPN" SG_ 2365402110 Jystck6GrpXAxsLvrLftNgtvPsStatus 4588;
BA_ "SigType" SG_ 2365402110 Jystck6GripXAxisNeutralPosStatus 4;
BA_ "SPN" SG_ 2365402110 Jystck6GripXAxisNeutralPosStatus 4587;
BA_ "SigType" SG_ 2365402622 Joystick5Button13PressedStatus 4;
BA_ "SPN" SG_ 2365402622 Joystick5Button13PressedStatus 6747;
BA_ "SigType" SG_ 2365402622 Joystick5Button14PressedStatus 4;
BA_ "SPN" SG_ 2365402622 Joystick5Button14PressedStatus 6748;
BA_ "SigType" SG_ 2365402622 Joystick5Button15PressedStatus 4;
BA_ "SPN" SG_ 2365402622 Joystick5Button15PressedStatus 6749;
BA_ "SigType" SG_ 2365402622 Joystick5Button16PressedStatus 4;
BA_ "SPN" SG_ 2365402622 Joystick5Button16PressedStatus 6750;
BA_ "SigType" SG_ 2365402622 Jystick5GripXAxisDetentPosStatus 4;
BA_ "SPN" SG_ 2365402622 Jystick5GripXAxisDetentPosStatus 4564;
BA_ "SigType" SG_ 2365402622 Jystick5GripYAxisDetentPosStatus 4;
BA_ "SPN" SG_ 2365402622 Jystick5GripYAxisDetentPosStatus 4563;
BA_ "SigType" SG_ 2365402622 Jystick5ThetaAxisDetentPosStatus 4;
BA_ "SPN" SG_ 2365402622 Jystick5ThetaAxisDetentPosStatus 4562;
BA_ "SPN" SG_ 2365402622 Joystick5ThetaAxisPos 4561;
BA_ "SigType" SG_ 2365402622 Jystck5ThtAxsClckwsPstvPosStatus 4;
BA_ "SPN" SG_ 2365402622 Jystck5ThtAxsClckwsPstvPosStatus 4560;
BA_ "SigType" SG_ 2365402622 Jystck5ThtAxsCntrClckwsNgtvPsStt 4;
BA_ "SPN" SG_ 2365402622 Jystck5ThtAxsCntrClckwsNgtvPsStt 4559;
BA_ "SigType" SG_ 2365402622 Jystck5ThetaAxisNeutralPosStatus 4;
BA_ "SPN" SG_ 2365402622 Jystck5ThetaAxisNeutralPosStatus 4558;
BA_ "SPN" SG_ 2365402622 Joystick5GripYAxisPos 4557;
BA_ "SigType" SG_ 2365402622 Jystck5GrpYAxsLvrFrwrdPstvPsStts 4;
BA_ "SPN" SG_ 2365402622 Jystck5GrpYAxsLvrFrwrdPstvPsStts 4556;
BA_ "SigType" SG_ 2365402622 Jystck5GrpYAxsLvrBckNgtvPsStatus 4;
BA_ "SPN" SG_ 2365402622 Jystck5GrpYAxsLvrBckNgtvPsStatus 4555;
BA_ "SigType" SG_ 2365402622 Jystck5GripYAxisNeutralPosStatus 4;
BA_ "SPN" SG_ 2365402622 Jystck5GripYAxisNeutralPosStatus 4554;
BA_ "SPN" SG_ 2365402622 Joystick5GripXAxisPos 4553;
BA_ "SigType" SG_ 2365402622 Jystck5GrpXAxsLvrRghtPstvPsSttus 4;
BA_ "SPN" SG_ 2365402622 Jystck5GrpXAxsLvrRghtPstvPsSttus 4552;
BA_ "SigType" SG_ 2365402622 Jystck5GrpXAxsLvrLftNgtvPsStatus 4;
BA_ "SPN" SG_ 2365402622 Jystck5GrpXAxsLvrLftNgtvPsStatus 4551;
BA_ "SigType" SG_ 2365402622 Jystck5GripXAxisNeutralPosStatus 4;
BA_ "SPN" SG_ 2365402622 Jystck5GripXAxisNeutralPosStatus 4550;
BA_ "SigType" SG_ 2365403134 Joystick4Button13PressedStatus 4;
BA_ "SPN" SG_ 2365403134 Joystick4Button13PressedStatus 6743;
BA_ "SigType" SG_ 2365403134 Joystick4Button14PressedStatus 4;
BA_ "SPN" SG_ 2365403134 Joystick4Button14PressedStatus 6744;
BA_ "SigType" SG_ 2365403134 Joystick4Button15PressedStatus 4;
BA_ "SPN" SG_ 2365403134 Joystick4Button15PressedStatus 6745;
BA_ "SigType" SG_ 2365403134 Joystick4Button16PressedStatus 4;
BA_ "SPN" SG_ 2365403134 Joystick4Button16PressedStatus 6746;
BA_ "SigType" SG_ 2365403134 Jystick4GripXAxisDetentPosStatus 4;
BA_ "SPN" SG_ 2365403134 Jystick4GripXAxisDetentPosStatus 4527;
BA_ "SigType" SG_ 2365403134 Jystick4GripYAxisDetentPosStatus 4;
BA_ "SPN" SG_ 2365403134 Jystick4GripYAxisDetentPosStatus 4526;
BA_ "SigType" SG_ 2365403134 Jystick4ThetaAxisDetentPosStatus 4;
BA_ "SPN" SG_ 2365403134 Jystick4ThetaAxisDetentPosStatus 4525;
BA_ "SPN" SG_ 2365403134 Joystick4ThetaAxisPos 4524;
BA_ "SigType" SG_ 2365403134 Jystck4ThtAxsClckwsPstvPosStatus 4;
BA_ "SPN" SG_ 2365403134 Jystck4ThtAxsClckwsPstvPosStatus 4523;
BA_ "SigType" SG_ 2365403134 Jystck4ThtAxsCntrClckwsNgtvPsStt 4;
BA_ "SPN" SG_ 2365403134 Jystck4ThtAxsCntrClckwsNgtvPsStt 4522;
BA_ "SigType" SG_ 2365403134 Jystck4ThetaAxisNeutralPosStatus 4;
BA_ "SPN" SG_ 2365403134 Jystck4ThetaAxisNeutralPosStatus 4521;
BA_ "SPN" SG_ 2365403134 Joystick4GripYAxisPos 4520;
BA_ "SigType" SG_ 2365403134 Jystck4GrpYAxsLvrFrwrdPstvPsStts 4;
BA_ "SPN" SG_ 2365403134 Jystck4GrpYAxsLvrFrwrdPstvPsStts 4519;
BA_ "SigType" SG_ 2365403134 Jystck4GrpYAxsLvrBckNgtvPsStatus 4;
BA_ "SPN" SG_ 2365403134 Jystck4GrpYAxsLvrBckNgtvPsStatus 4518;
BA_ "SigType" SG_ 2365403134 Jystck4GripYAxisNeutralPosStatus 4;
BA_ "SPN" SG_ 2365403134 Jystck4GripYAxisNeutralPosStatus 4517;
BA_ "SPN" SG_ 2365403134 Joystick4GripXAxisPos 4516;
BA_ "SigType" SG_ 2365403134 Jystck4GrpXAxsLvrRghtPstvPsSttus 4;
BA_ "SPN" SG_ 2365403134 Jystck4GrpXAxsLvrRghtPstvPsSttus 4515;
BA_ "SigType" SG_ 2365403134 Jystck4GrpXAxsLvrLftNgtvPsStatus 4;
BA_ "SPN" SG_ 2365403134 Jystck4GrpXAxsLvrLftNgtvPsStatus 4514;
BA_ "SigType" SG_ 2365403134 Jystck4GripXAxisNeutralPosStatus 4;
BA_ "SPN" SG_ 2365403134 Jystck4GripXAxisNeutralPosStatus 4513;
BA_ "SigType" SG_ 2365400062 Joystick10Button13PressedStatus 4;
BA_ "SPN" SG_ 2365400062 Joystick10Button13PressedStatus 6767;
BA_ "SigType" SG_ 2365400062 Joystick10Button14PressedStatus 4;
BA_ "SPN" SG_ 2365400062 Joystick10Button14PressedStatus 6768;
BA_ "SigType" SG_ 2365400062 Joystick10Button15PressedStatus 4;
BA_ "SPN" SG_ 2365400062 Joystick10Button15PressedStatus 6769;
BA_ "SigType" SG_ 2365400062 Joystick10Button16PressedStatus 4;
BA_ "SPN" SG_ 2365400062 Joystick10Button16PressedStatus 6770;
BA_ "SigType" SG_ 2365400062 Jystck10GripXAxisDetentPosStatus 4;
BA_ "SPN" SG_ 2365400062 Jystck10GripXAxisDetentPosStatus 4749;
BA_ "SigType" SG_ 2365400062 Jystck10GripYAxisDetentPosStatus 4;
BA_ "SPN" SG_ 2365400062 Jystck10GripYAxisDetentPosStatus 4748;
BA_ "SigType" SG_ 2365400062 Jystck10ThetaAxisDetentPosStatus 4;
BA_ "SPN" SG_ 2365400062 Jystck10ThetaAxisDetentPosStatus 4747;
BA_ "SPN" SG_ 2365400062 Joystick10ThetaAxisPos 4746;
BA_ "SigType" SG_ 2365400062 Jystck10ThtAxsClckwsPstvPsStatus 4;
BA_ "SPN" SG_ 2365400062 Jystck10ThtAxsClckwsPstvPsStatus 4745;
BA_ "SigType" SG_ 2365400062 Jystck10ThtAxsCntrClckwsNgtvPsSt 4;
BA_ "SPN" SG_ 2365400062 Jystck10ThtAxsCntrClckwsNgtvPsSt 4744;
BA_ "SigType" SG_ 2365400062 Jystck10ThtaAxisNeutralPosStatus 4;
BA_ "SPN" SG_ 2365400062 Jystck10ThtaAxisNeutralPosStatus 4743;
BA_ "SPN" SG_ 2365400062 Joystick10GripYAxisPos 4742;
BA_ "SigType" SG_ 2365400062 Jystck10GrpYAxsLvrFrwrdPstvPsStt 4;
BA_ "SPN" SG_ 2365400062 Jystck10GrpYAxsLvrFrwrdPstvPsStt 4741;
BA_ "SigType" SG_ 2365400062 Jystck10GrpYAxsLvrBckNgtvPsSttus 4;
BA_ "SPN" SG_ 2365400062 Jystck10GrpYAxsLvrBckNgtvPsSttus 4740;
BA_ "SigType" SG_ 2365400062 Jystck10GrpYAxisNeutralPosStatus 4;
BA_ "SPN" SG_ 2365400062 Jystck10GrpYAxisNeutralPosStatus 4739;
BA_ "SPN" SG_ 2365400062 Joystick10GripXAxisPos 4738;
BA_ "SigType" SG_ 2365400062 Jystck10GrpXAxsLvrRghtPstvPsStts 4;
BA_ "SPN" SG_ 2365400062 Jystck10GrpXAxsLvrRghtPstvPsStts 4737;
BA_ "SigType" SG_ 2365400062 Jystck10GrpXAxsLvrLftNgtvPsSttus 4;
BA_ "SPN" SG_ 2365400062 Jystck10GrpXAxsLvrLftNgtvPsSttus 4736;
BA_ "SigType" SG_ 2365400062 Jystck10GrpXAxisNeutralPosStatus 4;
BA_ "SPN" SG_ 2365400062 Jystck10GrpXAxisNeutralPosStatus 4735;
BA_ "SigType" SG_ 2566713598 FuelPumpInOilPress 1;
BA_ "SPN" SG_ 2566713598 FuelPumpInOilPress 9648;
BA_ "SigType" SG_ 2566713598 FuelTankTransferPumpPress 1;
BA_ "SPN" SG_ 2566713598 FuelTankTransferPumpPress 7395;
BA_ "SigType" SG_ 2566713598 FuelTankTransferPump 4;
BA_ "SPN" SG_ 2566713598 FuelTankTransferPump 4010;
BA_ "SigType" SG_ 2566713598 EngFuelFilterDegradation 1;
BA_ "SPN" SG_ 2566713598 EngFuelFilterDegradation 6716;
BA_ "SigType" SG_ 2566713598 EngFuelFilterIntakeAbsPress 1;
BA_ "SPN" SG_ 2566713598 EngFuelFilterIntakeAbsPress 5417;
BA_ "SigType" SG_ 2499604478 EngFuelDeliveryPress 1;
BA_ "SPN" SG_ 2499604478 EngFuelDeliveryPress 7469;
BA_ "SigType" SG_ 2499604478 EngOilPress 1;
BA_ "SPN" SG_ 2499604478 EngOilPress 7468;
BA_ "SigType" SG_ 2499604478 EngExhstGsRcrcltn1OutletAbsPress 1;
BA_ "SPN" SG_ 2499604478 EngExhstGsRcrcltn1OutletAbsPress 5431;
BA_ "SigType" SG_ 2499604478 EngExhstGsRcrcltn1IntakeAbsPress 1;
BA_ "SPN" SG_ 2499604478 EngExhstGsRcrcltn1IntakeAbsPress 5430;
BA_ "SigType" SG_ 2499608830 EngCoolantPress2 1;
BA_ "SPN" SG_ 2499608830 EngCoolantPress2 5708;
BA_ "SigType" SG_ 2499608830 EngExhstGsRcrcltn2IntakeAbsPress 1;
BA_ "SPN" SG_ 2499608830 EngExhstGsRcrcltn2IntakeAbsPress 5429;
BA_ "SigType" SG_ 2499608830 EngExhstGsRcrcltn2OutletAbsPress 1;
BA_ "SPN" SG_ 2499608830 EngExhstGsRcrcltn2OutletAbsPress 5254;
BA_ "SigType" SG_ 2499608830 EngExhstGsRcrclation2IntakePress 1;
BA_ "SPN" SG_ 2499608830 EngExhstGsRcrclation2IntakePress 5253;
BA_ "SigType" SG_ 2499608830 EngExhstGsRcirculation2DiffPress 1;
BA_ "SPN" SG_ 2499608830 EngExhstGsRcirculation2DiffPress 5252;
BA_ "SigType" SG_ 2432499198 CmmndedEngFuelInjectionCtrlPress 1;
BA_ "SPN" SG_ 2432499198 CmmndedEngFuelInjectionCtrlPress 5314;
BA_ "SigType" SG_ 2432499198 CommandedEngFuelRailPress 1;
BA_ "SPN" SG_ 2432499198 CommandedEngFuelRailPress 5313;
BA_ "SigType" SG_ 2432499198 EngExhstGsRcirculation2Valve2Pos 1;
BA_ "SPN" SG_ 2432499198 EngExhstGsRcirculation2Valve2Pos 5263;
BA_ "SigType" SG_ 2432499198 EngExhstGsRecirculation2ValvePos 1;
BA_ "SPN" SG_ 2432499198 EngExhstGsRecirculation2ValvePos 5262;
BA_ "SigType" SG_ 2633825022 EngExhstGsRcrcltn2Valve2PosError 1;
BA_ "SPN" SG_ 2633825022 EngExhstGsRcrcltn2Valve2PosError 5832;
BA_ "SigType" SG_ 2633825022 EngExhstGsRcrcltn2Valve1PosError 1;
BA_ "SPN" SG_ 2633825022 EngExhstGsRcrcltn2Valve1PosError 5831;
BA_ "SigType" SG_ 2633825022 EngExhstGsRcrculation2Valve2Ctrl 1;
BA_ "SPN" SG_ 2633825022 EngExhstGsRcrculation2Valve2Ctrl 5265;
BA_ "SigType" SG_ 2633825022 EngExhstGsRcirculation2ValveCtrl 1;
BA_ "SPN" SG_ 2633825022 EngExhstGsRcirculation2ValveCtrl 5264;
BA_ "SigType" SG_ 2633826046 EGR2CoolerInPress 1;
BA_ "SPN" SG_ 2633826046 EGR2CoolerInPress 9380;
BA_ "SigType" SG_ 2633826046 EGR2CoolerBypassActuatorPos 1;
BA_ "SPN" SG_ 2633826046 EGR2CoolerBypassActuatorPos 5261;
BA_ "SigType" SG_ 2633826046 EngExhstGsRcrcltn2ClerEfficiency 1;
BA_ "SPN" SG_ 2633826046 EngExhstGsRcrcltn2ClerEfficiency 5260;
BA_ "SigType" SG_ 2633826046 EngExhstGsRcrcltn2ClrIntkGsAbsPr 1;
BA_ "SPN" SG_ 2633826046 EngExhstGsRcrcltn2ClrIntkGsAbsPr 5259;
BA_ "SigType" SG_ 2633826046 EngExhstGsRcrcltn2ClerIntakeTemp 1;
BA_ "SPN" SG_ 2633826046 EngExhstGsRcrcltn2ClerIntakeTemp 5258;
BA_ "SigType" SG_ 2566711294 EngFrictionPercentTorquePoint7 1;
BA_ "GenSigStartValue" SG_ 2566711294 EngFrictionPercentTorquePoint7 125;
BA_ "SPN" SG_ 2566711294 EngFrictionPercentTorquePoint7 5477;
BA_ "SigType" SG_ 2566711294 EngFrictionPercentTorquePoint6 1;
BA_ "GenSigStartValue" SG_ 2566711294 EngFrictionPercentTorquePoint6 125;
BA_ "SPN" SG_ 2566711294 EngFrictionPercentTorquePoint6 5476;
BA_ "SigType" SG_ 2566711294 EngFrictionPercentTorquePoint5 1;
BA_ "GenSigStartValue" SG_ 2566711294 EngFrictionPercentTorquePoint5 125;
BA_ "SPN" SG_ 2566711294 EngFrictionPercentTorquePoint5 5475;
BA_ "SigType" SG_ 2566711294 EngFrictionPercentTorquePoint4 1;
BA_ "GenSigStartValue" SG_ 2566711294 EngFrictionPercentTorquePoint4 125;
BA_ "SPN" SG_ 2566711294 EngFrictionPercentTorquePoint4 5474;
BA_ "SigType" SG_ 2566711294 EngFrictionPercentTorquePoint3 1;
BA_ "GenSigStartValue" SG_ 2566711294 EngFrictionPercentTorquePoint3 125;
BA_ "SPN" SG_ 2566711294 EngFrictionPercentTorquePoint3 5473;
BA_ "SigType" SG_ 2566711294 EngFrictionPercentTorquePoint2 1;
BA_ "GenSigStartValue" SG_ 2566711294 EngFrictionPercentTorquePoint2 125;
BA_ "SPN" SG_ 2566711294 EngFrictionPercentTorquePoint2 5472;
BA_ "SigType" SG_ 2566711294 EngFrctnPrcentTorqueAtIdlePoint1 1;
BA_ "GenSigStartValue" SG_ 2566711294 EngFrctnPrcentTorqueAtIdlePoint1 125;
BA_ "SPN" SG_ 2566711294 EngFrctnPrcentTorqueAtIdlePoint1 5471;
BA_ "SigType" SG_ 2566749438 ActiveRegenInhibitedDueThresher 5;
BA_ "SPN" SG_ 2566749438 ActiveRegenInhibitedDueThresher 10153;
BA_ "SigType" SG_ 2566749438 ActiveRegenAvailabilityStatus 5;
BA_ "SPN" SG_ 2566749438 ActiveRegenAvailabilityStatus 8857;
BA_ "SigType" SG_ 2566749438 DslPrtcltFltrActvRgnrtnInhbt5629 5;
BA_ "SPN" SG_ 2566749438 DslPrtcltFltrActvRgnrtnInhbt5629 5629;
BA_ "SigType" SG_ 2566749438 A1DPFCondNotMetForActiveRegen 5;
BA_ "SPN" SG_ 2566749438 A1DPFCondNotMetForActiveRegen 3750;
BA_ "SigType" SG_ 2566749438 HydrocarbonDoserPurgingEnable 5;
BA_ "SPN" SG_ 2566749438 HydrocarbonDoserPurgingEnable 5504;
BA_ "SPN" SG_ 2566749438 DslPrtcltFltrActvRgnrtnFrcdSttus 4175;
BA_ "SPN" SG_ 2566749438 ExhaustSystemHighTempLampCmd 3698;
BA_ "SigType" SG_ 2566749438 DslPrtcltFltrAtmtcActvRgnrtnIntt 5;
BA_ "SPN" SG_ 2566749438 DslPrtcltFltrAtmtcActvRgnrtnIntt 3718;
BA_ "SigType" SG_ 2566749438 DslPrtcltFltrActvRgnrtnInhbt3717 5;
BA_ "SPN" SG_ 2566749438 DslPrtcltFltrActvRgnrtnInhbt3717 3717;
BA_ "SigType" SG_ 2566749438 DslPrtcltFltrActvRgnrtnInhbtdDTE 5;
BA_ "SPN" SG_ 2566749438 DslPrtcltFltrActvRgnrtnInhbtdDTE 3716;
BA_ "SigType" SG_ 2566749438 DslPrtcltFltrActvRgnrtnInhbt3715 4;
BA_ "SPN" SG_ 2566749438 DslPrtcltFltrActvRgnrtnInhbt3715 3715;
BA_ "SigType" SG_ 2566749438 DslPrtcltFltrActvRgnrtnInhbtdDTT 5;
BA_ "SPN" SG_ 2566749438 DslPrtcltFltrActvRgnrtnInhbtdDTT 3714;
BA_ "SigType" SG_ 2566749438 DslPrtcltFltrActvRgnrtnInhbt3713 5;
BA_ "SPN" SG_ 2566749438 DslPrtcltFltrActvRgnrtnInhbt3713 3713;
BA_ "SigType" SG_ 2566749438 DslPrtcltFltrActvRgnrtnInhbt3712 5;
BA_ "SPN" SG_ 2566749438 DslPrtcltFltrActvRgnrtnInhbt3712 3712;
BA_ "SigType" SG_ 2566749438 DslPrtcltFltrActvRgnrtnInhbtdDTL 4;
BA_ "SPN" SG_ 2566749438 DslPrtcltFltrActvRgnrtnInhbtdDTL 3711;
BA_ "SigType" SG_ 2566749438 DslPrtcltFltrActvRgnrtnInhbt3710 5;
BA_ "SPN" SG_ 2566749438 DslPrtcltFltrActvRgnrtnInhbt3710 3710;
BA_ "SigType" SG_ 2566749438 DslPrtcltFltrActvRgnrtnInhbtdDTV 5;
BA_ "SPN" SG_ 2566749438 DslPrtcltFltrActvRgnrtnInhbtdDTV 3709;
BA_ "SigType" SG_ 2566749438 DslPrtcltFltrActvRgnrtnInhbtdDTO 5;
BA_ "SPN" SG_ 2566749438 DslPrtcltFltrActvRgnrtnInhbtdDTO 3708;
BA_ "SigType" SG_ 2566749438 DslPrtcltFltrActvRgnrtnInhbtdDTA 5;
BA_ "SPN" SG_ 2566749438 DslPrtcltFltrActvRgnrtnInhbtdDTA 3707;
BA_ "SigType" SG_ 2566749438 DslPrtcltFltrActvRgnrtnInhbtdDTP 5;
BA_ "SPN" SG_ 2566749438 DslPrtcltFltrActvRgnrtnInhbtdDTP 3706;
BA_ "SigType" SG_ 2566749438 DslPrtcltFltrActvRgnrtnInhbtdDTS 5;
BA_ "SPN" SG_ 2566749438 DslPrtcltFltrActvRgnrtnInhbtdDTS 3705;
BA_ "SigType" SG_ 2566749438 DslPrtcltFltrActvRgnrtnInhbtdDTC 5;
BA_ "SPN" SG_ 2566749438 DslPrtcltFltrActvRgnrtnInhbtdDTC 3704;
BA_ "SigType" SG_ 2566749438 DslPrtcltFltrActvRgnrtnInhbtdDTI 5;
BA_ "SPN" SG_ 2566749438 DslPrtcltFltrActvRgnrtnInhbtdDTI 3703;
BA_ "SigType" SG_ 2566749438 DslPrtcltFltrActvRgnrtnInhbtdStt 5;
BA_ "SPN" SG_ 2566749438 DslPrtcltFltrActvRgnrtnInhbtdStt 3702;
BA_ "SPN" SG_ 2566749438 AFTDPFSt 3701;
BA_ "SigType" SG_ 2566749438 AFTDPFActiveRegenSt 5;
BA_ "SPN" SG_ 2566749438 AFTDPFActiveRegenSt 3700;
BA_ "SigType" SG_ 2566749438 AFTDPFPassiveRegenSt 5;
BA_ "SPN" SG_ 2566749438 AFTDPFPassiveRegenSt 3699;
BA_ "SPN" SG_ 2566749438 DieselParticulateFilterLampCmd 3697;
BA_ "SigType" SG_ 2566715646 A2DPFSootSignalMin 1;
BA_ "SPN" SG_ 2566715646 A2DPFSootSignalMin 5271;
BA_ "SigType" SG_ 2566715646 A2DPFSootSignalMax 1;
BA_ "SPN" SG_ 2566715646 A2DPFSootSignalMax 5270;
BA_ "SigType" SG_ 2566715646 A2DPFSootSignalStdDeviation 1;
BA_ "SPN" SG_ 2566715646 A2DPFSootSignalStdDeviation 5269;
BA_ "SigType" SG_ 2566724606 DslPrtcltFltr2StSnsrECUIntrnlTmp 1;
BA_ "SPN" SG_ 2566724606 DslPrtcltFltr2StSnsrECUIntrnlTmp 5570;
BA_ "SPN" SG_ 2566724606 A2DPFSootSnsrPreliminaryFMI 4790;
BA_ "SigType" SG_ 2566724606 A2DPFMedianSootSignal 1;
BA_ "SPN" SG_ 2566724606 A2DPFMedianSootSignal 4789;
BA_ "SigType" SG_ 2566724606 A2DPFMeanSootSignal 1;
BA_ "SPN" SG_ 2566724606 A2DPFMeanSootSignal 4788;
BA_ "SigType" SG_ 2566724606 A2DPFSootDensity 1;
BA_ "SPN" SG_ 2566724606 A2DPFSootDensity 4787;
BA_ "SigType" SG_ 2566724606 A2DPFSootMass 1;
BA_ "SPN" SG_ 2566724606 A2DPFSootMass 4786;
BA_ "SigType" SG_ 2566715902 A1DPFSootSignalMin 1;
BA_ "SPN" SG_ 2566715902 A1DPFSootSignalMin 5268;
BA_ "SigType" SG_ 2566715902 A1DPFSootSignalMax 1;
BA_ "SPN" SG_ 2566715902 A1DPFSootSignalMax 5267;
BA_ "SigType" SG_ 2566715902 A1DPFSootSignalStdDeviation 1;
BA_ "SPN" SG_ 2566715902 A1DPFSootSignalStdDeviation 5266;
BA_ "SigType" SG_ 2566724862 DslPrtcltFltr1StSnsrECUIntrnlTmp 1;
BA_ "SPN" SG_ 2566724862 DslPrtcltFltr1StSnsrECUIntrnlTmp 5569;
BA_ "SPN" SG_ 2566724862 A1DPFSootSnsrPreliminaryFMI 4785;
BA_ "SigType" SG_ 2566724862 A1DPFMedianSootSignal 1;
BA_ "SPN" SG_ 2566724862 A1DPFMedianSootSignal 4784;
BA_ "SigType" SG_ 2566724862 A1DPFMeanSootSignal 1;
BA_ "SPN" SG_ 2566724862 A1DPFMeanSootSignal 4783;
BA_ "SigType" SG_ 2566724862 A1DPFSootDensity 1;
BA_ "SPN" SG_ 2566724862 A1DPFSootDensity 4782;
BA_ "SigType" SG_ 2566724862 A1DPFSootMass 1;
BA_ "SPN" SG_ 2566724862 A1DPFSootMass 4781;
BA_ "SigType" SG_ 2566718718 OptionalLamp6Data 4;
BA_ "SPN" SG_ 2566718718 OptionalLamp6Data 13128;
BA_ "SigType" SG_ 2566718718 OptionalLamp5Data 4;
BA_ "SPN" SG_ 2566718718 OptionalLamp5Data 13127;
BA_ "SigType" SG_ 2566718718 OptionalLamp4Data 4;
BA_ "SPN" SG_ 2566718718 OptionalLamp4Data 13126;
BA_ "SigType" SG_ 2566718718 OptionalLamp3Data 4;
BA_ "SPN" SG_ 2566718718 OptionalLamp3Data 13125;
BA_ "SigType" SG_ 2566718718 OptionalLamp2Data 4;
BA_ "SPN" SG_ 2566718718 OptionalLamp2Data 13124;
BA_ "SigType" SG_ 2566718718 OptionalLamp1Data 4;
BA_ "SPN" SG_ 2566718718 OptionalLamp1Data 13123;
BA_ "SigType" SG_ 2566718718 SecondAirPressLowLamp 4;
BA_ "SPN" SG_ 2566718718 SecondAirPressLowLamp 13122;
BA_ "SigType" SG_ 2566718718 PrimaryAirPressLowLamp 4;
BA_ "SPN" SG_ 2566718718 PrimaryAirPressLowLamp 13121;
BA_ "SigType" SG_ 2566718718 VehLimPerformanceModeLamp 4;
BA_ "SPN" SG_ 2566718718 VehLimPerformanceModeLamp 10296;
BA_ "SigType" SG_ 2566718718 HillHolderLampData 5;
BA_ "SPN" SG_ 2566718718 HillHolderLampData 1848;
BA_ "SigType" SG_ 2566718718 VehicleBatteryChargingLampData 4;
BA_ "SPN" SG_ 2566718718 VehicleBatteryChargingLampData 5108;
BA_ "SigType" SG_ 2566718718 VehicleHVACRecirculationLampData 4;
BA_ "SPN" SG_ 2566718718 VehicleHVACRecirculationLampData 5107;
BA_ "SigType" SG_ 2566718718 VehicleAirPressLowLampData 4;
BA_ "SPN" SG_ 2566718718 VehicleAirPressLowLampData 5106;
BA_ "SigType" SG_ 2566718718 VehicleFuelLevelLowLampData 4;
BA_ "SPN" SG_ 2566718718 VehicleFuelLevelLowLampData 5105;
BA_ "SigType" SG_ 2566718718 VehicleBatteryVoltageLowLampData 4;
BA_ "SPN" SG_ 2566718718 VehicleBatteryVoltageLowLampData 5104;
BA_ "SigType" SG_ 2566718974 EngSvcLamp 4;
BA_ "SPN" SG_ 2566718974 EngSvcLamp 21789;
BA_ "SigType" SG_ 2566718974 EngAirShutoffLamp 5;
BA_ "SPN" SG_ 2566718974 EngAirShutoffLamp 13380;
BA_ "SigType" SG_ 2566718974 EngIntercoolerTempHiLamp 4;
BA_ "SPN" SG_ 2566718974 EngIntercoolerTempHiLamp 13120;
BA_ "SigType" SG_ 2566718974 EngFuelTempHiLamp 4;
BA_ "SPN" SG_ 2566718974 EngFuelTempHiLamp 13119;
BA_ "SigType" SG_ 2566718974 EngOilTempHiLamp 4;
BA_ "SPN" SG_ 2566718974 EngOilTempHiLamp 13118;
BA_ "SigType" SG_ 2566718974 EngStopStartEnabledLamp 4;
BA_ "SPN" SG_ 2566718974 EngStopStartEnabledLamp 9682;
BA_ "SigType" SG_ 2566718974 EngStopStartAutoStartFailedLamp 4;
BA_ "SPN" SG_ 2566718974 EngStopStartAutoStartFailedLamp 9681;
BA_ "SigType" SG_ 2566718974 EngStopStartAutoStopActiveLamp 4;
BA_ "SPN" SG_ 2566718974 EngStopStartAutoStopActiveLamp 9680;
BA_ "SigType" SG_ 2566718974 VhclAcclerationRateLimitLampData 4;
BA_ "SPN" SG_ 2566718974 VhclAcclerationRateLimitLampData 6900;
BA_ "SigType" SG_ 2566718974 EngSpeedVeryHighLampData 5;
BA_ "SPN" SG_ 2566718974 EngSpeedVeryHighLampData 6712;
BA_ "SigType" SG_ 2566718974 EngSpeedHighLampData 5;
BA_ "SPN" SG_ 2566718974 EngSpeedHighLampData 6711;
BA_ "SigType" SG_ 2566718974 EngCtrlMdule3ReadyForUseLampData 4;
BA_ "SPN" SG_ 2566718974 EngCtrlMdule3ReadyForUseLampData 6204;
BA_ "SigType" SG_ 2566718974 EngCtrlMdule2ReadyForUseLampData 4;
BA_ "SPN" SG_ 2566718974 EngCtrlMdule2ReadyForUseLampData 6203;
BA_ "SigType" SG_ 2566718974 EngCtrlMdule1ReadyForUseLampData 4;
BA_ "SPN" SG_ 2566718974 EngCtrlMdule1ReadyForUseLampData 6202;
BA_ "SigType" SG_ 2566718974 EngWaitToStartLampData 4;
BA_ "SPN" SG_ 2566718974 EngWaitToStartLampData 5416;
BA_ "SigType" SG_ 2566718974 EngFuelFilterRestrictedLampData 5;
BA_ "SPN" SG_ 2566718974 EngFuelFilterRestrictedLampData 5470;
BA_ "SigType" SG_ 2566718974 EngAirFilterRestrictionLampData 4;
BA_ "SPN" SG_ 2566718974 EngAirFilterRestrictionLampData 5103;
BA_ "SigType" SG_ 2566718974 EngIdleManagementActiveLampData 4;
BA_ "SPN" SG_ 2566718974 EngIdleManagementActiveLampData 5102;
BA_ "SigType" SG_ 2566718974 EngCoolantLevelLowLampData 4;
BA_ "SPN" SG_ 2566718974 EngCoolantLevelLowLampData 5101;
BA_ "SigType" SG_ 2566718974 EngCoolantTempHighLampData 4;
BA_ "SPN" SG_ 2566718974 EngCoolantTempHighLampData 5100;
BA_ "SigType" SG_ 2566718974 EngOilPressLowLampData 4;
BA_ "SPN" SG_ 2566718974 EngOilPressLowLampData 5099;
BA_ "SigType" SG_ 2566718974 CmprssnBrkEnblSwtchIndctrLmpData 4;
BA_ "SPN" SG_ 2566718974 CmprssnBrkEnblSwtchIndctrLmpData 5098;
BA_ "SigType" SG_ 2566718974 EngBrakeActiveLampData 4;
BA_ "SPN" SG_ 2566718974 EngBrakeActiveLampData 5097;
BA_ "SigType" SG_ 2566718974 OBDMalfunctionIndicatorLampData 4;
BA_ "SPN" SG_ 2566718974 OBDMalfunctionIndicatorLampData 5096;
BA_ "SigType" SG_ 2566718974 EngRedStopLampData 4;
BA_ "SPN" SG_ 2566718974 EngRedStopLampData 5095;
BA_ "SigType" SG_ 2566718974 EngAmberWarningLampData 4;
BA_ "SPN" SG_ 2566718974 EngAmberWarningLampData 5094;
BA_ "SigType" SG_ 2566718974 EngProtectLampData 4;
BA_ "SPN" SG_ 2566718974 EngProtectLampData 5093;
BA_ "SigType" SG_ 2566719230 OptionalLamp6Cmd 5;
BA_ "SPN" SG_ 2566719230 OptionalLamp6Cmd 13115;
BA_ "SigType" SG_ 2566719230 OptionalLamp5Cmd 5;
BA_ "SPN" SG_ 2566719230 OptionalLamp5Cmd 13114;
BA_ "SigType" SG_ 2566719230 OptionalLamp4Cmd 5;
BA_ "SPN" SG_ 2566719230 OptionalLamp4Cmd 13113;
BA_ "SigType" SG_ 2566719230 OptionalLamp3Cmd 5;
BA_ "SPN" SG_ 2566719230 OptionalLamp3Cmd 13112;
BA_ "SigType" SG_ 2566719230 OptionalLamp2Cmd 5;
BA_ "SPN" SG_ 2566719230 OptionalLamp2Cmd 13111;
BA_ "SigType" SG_ 2566719230 OptionalLamp1Cmd 5;
BA_ "SPN" SG_ 2566719230 OptionalLamp1Cmd 13110;
BA_ "SigType" SG_ 2566719230 SecondAirPressLowLamp 5;
BA_ "SPN" SG_ 2566719230 SecondAirPressLowLamp 13109;
BA_ "SigType" SG_ 2566719230 PrimaryAirPressLowLamp 5;
BA_ "SPN" SG_ 2566719230 PrimaryAirPressLowLamp 13108;
BA_ "SigType" SG_ 2566719230 VehLimPerformanceModeLamp 5;
BA_ "SPN" SG_ 2566719230 VehLimPerformanceModeLamp 10295;
BA_ "SigType" SG_ 2566719230 HillHolderLampCmd 5;
BA_ "SPN" SG_ 2566719230 HillHolderLampCmd 1847;
BA_ "SigType" SG_ 2566719230 VehicleBatteryChargingLampCmd 5;
BA_ "SPN" SG_ 2566719230 VehicleBatteryChargingLampCmd 5091;
BA_ "SigType" SG_ 2566719230 VehicleHVACRecirculationLampCmd 5;
BA_ "SPN" SG_ 2566719230 VehicleHVACRecirculationLampCmd 5090;
BA_ "SigType" SG_ 2566719230 VehicleAirPressLowLampCmd 5;
BA_ "SPN" SG_ 2566719230 VehicleAirPressLowLampCmd 5089;
BA_ "SigType" SG_ 2566719230 VehicleFuelLevelLowLampCmd 5;
BA_ "SPN" SG_ 2566719230 VehicleFuelLevelLowLampCmd 5088;
BA_ "SigType" SG_ 2566719230 VehicleBatteryVoltageLowLampCmd 5;
BA_ "SPN" SG_ 2566719230 VehicleBatteryVoltageLowLampCmd 5087;
BA_ "SPN" SG_ 2560818942 SPN1 1214;
BA_ "SPN" SG_ 2560818942 FailureModeIdentifier1 1215;
BA_ "SigType" SG_ 2560818942 DTCTimeUntilDerate 1;
BA_ "SPN" SG_ 2560818942 DTCTimeUntilDerate 4123;
BA_ "SigType" SG_ 2560818942 DTCTotalPreviouslyActiveTime 1;
BA_ "SPN" SG_ 2560818942 DTCTotalPreviouslyActiveTime 4122;
BA_ "SigType" SG_ 2560818942 DTCTotalActiveTime 1;
BA_ "SPN" SG_ 2560818942 DTCTotalActiveTime 4121;
BA_ "SigType" SG_ 2561212158 TextDisplayIndex 1;
BA_ "SPN" SG_ 2561212158 TextDisplayIndex 3614;
BA_ "SPN" SG_ 2561212158 TextDisplayInstructions 3613;
BA_ "SigType" SG_ 2566746366 RetractStatusOfRamp5 5;
BA_ "SPN" SG_ 2566746366 RetractStatusOfRamp5 4457;
BA_ "SigType" SG_ 2566746366 RetractStatusOfRamp4 5;
BA_ "SPN" SG_ 2566746366 RetractStatusOfRamp4 4454;
BA_ "SigType" SG_ 2566746366 MovementStatusOfRamp5 5;
BA_ "SPN" SG_ 2566746366 MovementStatusOfRamp5 4459;
BA_ "SigType" SG_ 2566746366 MovementStatusOfRamp4 5;
BA_ "SPN" SG_ 2566746366 MovementStatusOfRamp4 4456;
BA_ "SigType" SG_ 2566746366 EnableStatusOfRamp5 5;
BA_ "SPN" SG_ 2566746366 EnableStatusOfRamp5 4458;
BA_ "SigType" SG_ 2566746366 EnableStatusOfRamp4 5;
BA_ "SPN" SG_ 2566746366 EnableStatusOfRamp4 4455;
BA_ "SigType" SG_ 2566746366 MovementStatusOfRamp3 5;
BA_ "SPN" SG_ 2566746366 MovementStatusOfRamp3 3818;
BA_ "SigType" SG_ 2566746366 EnableStatusOfRamp3 5;
BA_ "SPN" SG_ 2566746366 EnableStatusOfRamp3 3817;
BA_ "SigType" SG_ 2566746366 RetractStatusOfRamp3 5;
BA_ "SPN" SG_ 2566746366 RetractStatusOfRamp3 3816;
BA_ "SigType" SG_ 2566746366 MovementStatusOfRamp2 5;
BA_ "SPN" SG_ 2566746366 MovementStatusOfRamp2 3815;
BA_ "SigType" SG_ 2566746366 EnableStatusOfRamp2 5;
BA_ "SPN" SG_ 2566746366 EnableStatusOfRamp2 3814;
BA_ "SigType" SG_ 2566746366 RetractStatusOfRamp2 5;
BA_ "SPN" SG_ 2566746366 RetractStatusOfRamp2 3813;
BA_ "SigType" SG_ 2566746366 MovementStatusOfRamp1 5;
BA_ "SPN" SG_ 2566746366 MovementStatusOfRamp1 3812;
BA_ "SigType" SG_ 2566746366 EnableStatusOfRamp1 5;
BA_ "SPN" SG_ 2566746366 EnableStatusOfRamp1 3811;
BA_ "SigType" SG_ 2566746366 RetractStatusOfRamp1 5;
BA_ "SPN" SG_ 2566746366 RetractStatusOfRamp1 3810;
BA_ "SigType" SG_ 2566750206 TransIdleGovFuelingInhSupport 4;
BA_ "SPN" SG_ 2566750206 TransIdleGovFuelingInhSupport 7830;
BA_ "SigType" SG_ 2566750206 EngConfigIdentification 1;
BA_ "SPN" SG_ 2566750206 EngConfigIdentification 6395;
BA_ "SigType" SG_ 2566750206 NmbrOfCmbstionCyclesForAveraging 1;
BA_ "GenSigStartValue" SG_ 2566750206 NmbrOfCmbstionCyclesForAveraging 1;
BA_ "SPN" SG_ 2566750206 NmbrOfCmbstionCyclesForAveraging 6394;
BA_ "SigType" SG_ 2566750206 MaxCrankAttemptsPerStartAttempt 1;
BA_ "SPN" SG_ 2566750206 MaxCrankAttemptsPerStartAttempt 3670;
BA_ "SigType" SG_ 2566755582 CommandedEngIntakeManifoldPress 1;
BA_ "SPN" SG_ 2566755582 CommandedEngIntakeManifoldPress 5312;
BA_ "SigType" SG_ 2566755582 EngCrnkcsBrtherOilSeparatorSpeed 1;
BA_ "SPN" SG_ 2566755582 EngCrnkcsBrtherOilSeparatorSpeed 5444;
BA_ "SigType" SG_ 2566755582 EngExhstGsRcirculation1Valve2Pos 1;
BA_ "SPN" SG_ 2566755582 EngExhstGsRcirculation1Valve2Pos 3822;
BA_ "SigType" SG_ 2566755582 EngExhstGsRecirculation1ValvePos 1;
BA_ "SPN" SG_ 2566755582 EngExhstGsRecirculation1ValvePos 27;
BA_ "SigType" SG_ 2566746110 EGRAftercoolerInletCoolantTemp 1;
BA_ "SPN" SG_ 2566746110 EGRAftercoolerInletCoolantTemp 22718;
BA_ "SigType" SG_ 2566746110 EngExhstGsRcrcltn1ClerEfficiency 1;
BA_ "SPN" SG_ 2566746110 EngExhstGsRcrcltn1ClerEfficiency 4752;
BA_ "SigType" SG_ 2566746110 EngExhstGsRcrcltn1ClrIntkGsAbsPr 1;
BA_ "SPN" SG_ 2566746110 EngExhstGsRcrcltn1ClrIntkGsAbsPr 4751;
BA_ "SigType" SG_ 2566746110 EngExhstGsRcrcltn1ClerIntakeTemp 1;
BA_ "SPN" SG_ 2566746110 EngExhstGsRcrcltn1ClerIntakeTemp 4750;
BA_ "SigType" SG_ 2566746110 EngExhstGsRcrculation1Valve2Ctrl 1;
BA_ "SPN" SG_ 2566746110 EngExhstGsRcrculation1Valve2Ctrl 3821;
VAL_ 2566713854 EngExhstBckPrssRgltrCtrlOprtnStt 15 "Not available" 14 "Error" 5 "Uncontrolled Shutdown Active" 4 "Controlled Shutdown Active" 3 "Derate Active" 2 "Alarm High Severity" 1 "Alarm" 0 "Normal" ;
VAL_ 2566713854 EngExhstBckPrssRglatorTempStatus 7 "Not available" 6 "Error" 5 "Not Defined" 4 "Low Most severe" 3 "Low Least severe" 2 "In Range" 1 "High Least severe" 0 "High most severe" ;
VAL_ 2566713854 EngTrbWstgtActtr2OperationStatus 14 "Error" 5 "Uncontrolled Shutdown Active" 4 "Controlled Shutdown Active" 3 "Derate Active" 2 "Alarm High Severity" 1 "Alarm" 0 "Normal" ;
VAL_ 2566713854 EngTrbWstgtActtr1OperationStatus 14 "Error" 6 "Calibration in Progress" 5 "Uncontrolled Shutdown Active" 4 "Controlled Shutdown Active" 3 "Derate Active" 2 "Alarm High Severity" 1 "Alarm" 0 "Normal" ;
VAL_ 2566713854 EngTrbWstgateActuator2TempStatus 7 "Not available" 6 "Error" 5 "Not Defined" 4 "Low Most severe" 3 "Low Least severe" 2 "In Range" 1 "High Least severe" 0 "High most severe" ;
VAL_ 2566714366 EngTrbCmprssrBypssActtr2OprtnStt 14 "Error" 5 "Uncontrolled Shutdown Active" 4 "Controlled Shutdown Active" 3 "Derate Active" 2 "Alarm High Severity" 1 "Alarm" 0 "Normal" ;
VAL_ 2566714366 EngTrbCmprssrBypssActtr1OprtnStt 14 "Error" 5 "Uncontrolled Shutdown Active" 4 "Controlled Shutdown Active" 3 "Derate Active" 2 "Alarm High Severity" 1 "Alarm" 0 "Normal" ;
VAL_ 2566714366 EngTrbCmprssrBypssActtr2TmpSttus 7 "Not available" 6 "Error" 5 "Not Defined" 4 "Low Most severe" 3 "Low Least severe" 2 "In Range" 1 "High Least severe" 0 "High most severe" ;
VAL_ 2566714110 EngFuelValve2OperationStatus 14 "Error" 6 "Test Mode Active" 5 "Uncontrolled Shutdown Active" 4 "Controlled Shutdown Active" 3 "Derate Active" 2 "Alarm High Severity" 1 "Alarm" 0 "Normal" ;
VAL_ 2566714110 EngFuelValve1OperationStatus 14 "Error" 6 "Test Mode Active" 5 "Uncontrolled Shutdown Active" 4 "Controlled Shutdown Active" 3 "Derate Active" 2 "Alarm High Severity" 1 "Alarm" 0 "Normal" ;
VAL_ 2566714110 EngThrottleValve2OperationStatus 14 "Error" 5 "Uncontrolled Shutdown Active" 4 "Controlled Shutdown Active" 3 "Derate Active" 2 "Alarm High Severity" 1 "Alarm" 0 "Normal" ;
VAL_ 2566714110 EngThrottleValve1OperationStatus 15 "Not available" 14 "Error" 6 "Calibration in Progress" 5 "Uncontrolled Shutdown Active" 4 "Controlled Shutdown Active" 3 "Derate Active" 2 "Alarm High Severity" 1 "Alarm" 0 "Normal" ;
VAL_ 2566714110 EngFuelValve2TempStatus 7 "Not available" 6 "Error" 5 "Not Defined" 4 "Low Most severe" 3 "Low Least severe" 2 "In Range" 1 "High Least severe" 0 "High most severe" ;
VAL_ 2566714110 EngFuelValve1TempStatus 7 "Not available" 6 "Error" 5 "Not Defined" 4 "Low Most severe" 3 "Low Least severe" 2 "In Range" 1 "High Least severe" 0 "High Most severe" ;
VAL_ 2566714110 EngThrottleValve2TempStatus 7 "Not available" 6 "Error" 5 "Not Defined" 4 "Low Most severe" 3 "Low Least severe" 2 "In Range" 1 "High Least severe" 0 "High Most severe" ;
VAL_ 2566714110 EngThrottleValve1TempStatus 7 "Not available" 6 "Error" 5 "Not Defined" 4 "Low Most severe" 3 "Low Least severe" 2 "In Range" 1 "High Least severe" 0 "High most severe" ;
VAL_ 2365400574 Joystick9Button13PressedStatus 3 "Not Available" 2 "Error Indicator" 1 "Button pressed" 0 "Button not pressed" ;
VAL_ 2365400574 Joystick9Button14PressedStatus 3 "Not Available" 2 "Error Indicator" 1 "Button pressed" 0 "Button not pressed" ;
VAL_ 2365400574 Joystick9Button15PressedStatus 3 "Not Available" 2 "Error Indicator" 1 "Button pressed" 0 "Button not pressed" ;
VAL_ 2365400574 Joystick9Button16PressedStatus 3 "Not Available" 2 "Error Indicator" 1 "Button pressed" 0 "Button not pressed" ;
VAL_ 2365400574 Jystick9GripXAxisDetentPosStatus 3 "Not Available" 2 "Error Indicator" 1 "In the Detent Position" 0 "Not in the Detent Position" ;
VAL_ 2365400574 Jystick9GripYAxisDetentPosStatus 3 "Not Available" 2 "Error Indicator" 1 "In the Detent Position" 0 "Not in the Detent Position" ;
VAL_ 2365400574 Jystick9ThetaAxisDetentPosStatus 3 "Not Available" 2 "Error Indicator" 1 "In the Detent Position" 0 "Not in the Detent Position" ;
VAL_ 2365400574 Jystck9ThtAxsClckwsPstvPosStatus 3 "Not Available" 2 "Error Indicator" 1 "On positive side of Neutral" 0 "Not on Positive side of Neutral" ;
VAL_ 2365400574 Jystck9ThtAxsCntrClckwsNgtvPsStt 3 "Not Available" 2 "Error Indicator" 1 "On negative side of Neutral" 0 "Not on negative side of Neutral" ;
VAL_ 2365400574 Jystck9ThetaAxisNeutralPosStatus 3 "Not Available" 2 "Error Indicator" 1 "In Neutral Position" 0 "Not in Neutral Position" ;
VAL_ 2365400574 Jystck9GrpYAxsLvrFrwrdPstvPsStts 3 "Not Available" 2 "Error Indicator" 1 "On positive side of Neutral" 0 "Not on Positive side of Neutral" ;
VAL_ 2365400574 Jystck9GrpYAxsLvrBckNgtvPsStatus 3 "Not Available" 2 "Error Indicator" 1 "On negative side of Neutral" 0 "Not on negative side of Neutral" ;
VAL_ 2365400574 Jystck9GripYAxisNeutralPosStatus 3 "Not Available" 2 "Error Indicator" 1 "In Neutral Position" 0 "Not in Neutral Position" ;
VAL_ 2365400574 Jystck9GrpXAxsLvrRghtPstvPsSttus 3 "Not Available" 2 "Error Indicator" 1 "On positive side of Neutral" 0 "Not on Positive side of Neutral" ;
VAL_ 2365400574 Jystck9GrpXAxsLvrLftNgtvPsStatus 3 "Not Available" 2 "Error Indicator" 1 "On negative side of Neutral" 0 "Not on negative side of Neutral" ;
VAL_ 2365400574 Jystck9GripXAxisNeutralPosStatus 3 "Not Available" 2 "Error Indicator" 1 "In Neutral Position" 0 "Not in Neutral Position" ;
VAL_ 2365401086 Joystick8Button13PressedStatus 3 "Not Available" 2 "Error Indicator" 1 "Button pressed" 0 "Button not pressed" ;
VAL_ 2365401086 Joystick8Button14PressedStatus 3 "Not Available" 2 "Error Indicator" 1 "Button pressed" 0 "Button not pressed" ;
VAL_ 2365401086 Joystick8Button15PressedStatus 3 "Not Available" 2 "Error Indicator" 1 "Button pressed" 0 "Button not pressed" ;
VAL_ 2365401086 Joystick8Button16PressedStatus 3 "Not Available" 2 "Error Indicator" 1 "Button pressed" 0 "Button not pressed" ;
VAL_ 2365401086 Jystick8GripXAxisDetentPosStatus 3 "Not Available" 2 "Error Indicator" 1 "In the Detent Position" 0 "Not in the Detent Position" ;
VAL_ 2365401086 Jystick8GripYAxisDetentPosStatus 3 "Not Available" 2 "Error Indicator" 1 "In the Detent Position" 0 "Not in the Detent Position" ;
VAL_ 2365401086 Jystick8ThetaAxisDetentPosStatus 3 "Not Available" 2 "Error Indicator" 1 "In the Detent Position" 0 "Not in the Detent Position" ;
VAL_ 2365401086 Jystck8ThtAxsClckwsPstvPosStatus 3 "Not Available" 2 "Error Indicator" 1 "On positive side of Neutral" 0 "Not on Positive side of Neutral" ;
VAL_ 2365401086 Jystck8ThtAxsCntrClckwsNgtvPsStt 3 "Not Available" 2 "Error Indicator" 1 "On negative side of Neutral" 0 "Not on negative side of Neutral" ;
VAL_ 2365401086 Jystck8ThetaAxisNeutralPosStatus 3 "Not Available" 2 "Error Indicator" 1 "In Neutral Position" 0 "Not in Neutral Position" ;
VAL_ 2365401086 Jystck8GrpYAxsLvrFrwrdPstvPsStts 3 "Not Available" 2 "Error Indicator" 1 "On positive side of Neutral" 0 "Not on Positive side of Neutral" ;
VAL_ 2365401086 Jystck8GrpYAxsLvrBckNgtvPsStatus 3 "Not Available" 2 "Error Indicator" 1 "On negative side of Neutral" 0 "Not on negative side of Neutral" ;
VAL_ 2365401086 Jystck8GripYAxisNeutralPosStatus 3 "Not Available" 2 "Error Indicator" 1 "In Neutral Position" 0 "Not in Neutral Position" ;
VAL_ 2365401086 Jystck8GrpXAxsLvrRghtPstvPsSttus 3 "Not Available" 2 "Error Indicator" 1 "On positive side of Neutral" 0 "Not on Positive side of Neutral" ;
VAL_ 2365401086 Jystck8GrpXAxsLvrLftNgtvPsStatus 3 "Not Available" 2 "Error Indicator" 1 "On negative side of Neutral" 0 "Not on negative side of Neutral" ;
VAL_ 2365401086 Jystck8GripXAxisNeutralPosStatus 3 "Not Available" 2 "Error Indicator" 1 "In Neutral Position" 0 "Not in Neutral Position" ;
VAL_ 2365401598 Joystick7Button13PressedStatus 3 "Not Available" 2 "Error Indicator" 1 "Button pressed" 0 "Button not pressed" ;
VAL_ 2365401598 Joystick7Button14PressedStatus 3 "Not Available" 2 "Error Indicator" 1 "Button pressed" 0 "Button not pressed" ;
VAL_ 2365401598 Joystick7Button15PressedStatus 3 "Not Available" 2 "Error Indicator" 1 "Button pressed" 0 "Button not pressed" ;
VAL_ 2365401598 Joystick7Button16PressedStatus 3 "Not Available" 2 "Error Indicator" 1 "Button pressed" 0 "Button not pressed" ;
VAL_ 2365401598 Jystick7GripXAxisDetentPosStatus 3 "Not Available" 2 "Error Indicator" 1 "In the Detent Position" 0 "Not in the Detent Position" ;
VAL_ 2365401598 Jystick7GripYAxisDetentPosStatus 3 "Not Available" 2 "Error Indicator" 1 "In the Detent Position" 0 "Not in the Detent Position" ;
VAL_ 2365401598 Jystick7ThetaAxisDetentPosStatus 3 "Not Available" 2 "Error Indicator" 1 "In the Detent Position" 0 "Not in the Detent Position" ;
VAL_ 2365401598 Jystck7ThtAxsClckwsPstvPosStatus 3 "Not Available" 2 "Error Indicator" 1 "On positive side of Neutral" 0 "Not on Positive side of Neutral" ;
VAL_ 2365401598 Jystck7ThtAxsCntrClckwsNgtvPsStt 3 "Not Available" 2 "Error Indicator" 1 "On negative side of Neutral" 0 "Not on negative side of Neutral" ;
VAL_ 2365401598 Jystck7ThetaAxisNeutralPosStatus 3 "Not Available" 2 "Error Indicator" 1 "In Neutral Position" 0 "Not in Neutral Position" ;
VAL_ 2365401598 Jystck7GrpYAxsLvrFrwrdPstvPsStts 3 "Not Available" 2 "Error Indicator" 1 "On positive side of Neutral" 0 "Not on Positive side of Neutral" ;
VAL_ 2365401598 Jystck7GrpYAxsLvrBckNgtvPsStatus 3 "Not Available" 2 "Error Indicator" 1 "On negative side of Neutral" 0 "Not on negative side of Neutral" ;
VAL_ 2365401598 Jystck7GripYAxisNeutralPosStatus 3 "Not Available" 2 "Error Indicator" 1 "In Neutral Position" 0 "Not in Neutral Position" ;
VAL_ 2365401598 Jystck7GrpXAxsLvrRghtPstvPsSttus 3 "Not Available" 2 "Error Indicator" 1 "On positive side of Neutral" 0 "Not on Positive side of Neutral" ;
VAL_ 2365401598 Jystck7GrpXAxsLvrLftNgtvPsStatus 3 "Not Available" 2 "Error Indicator" 1 "On negative side of Neutral" 0 "Not on negative side of Neutral" ;
VAL_ 2365401598 Jystck7GripXAxisNeutralPosStatus 3 "Not Available" 2 "Error Indicator" 1 "In Neutral Position" 0 "Not in Neutral Position" ;
VAL_ 2365402110 Joystick6Button13PressedStatus 3 "Not Available" 2 "Error Indicator" 1 "Button pressed" 0 "Button not pressed" ;
VAL_ 2365402110 Joystick6Button14PressedStatus 3 "Not Available" 2 "Error Indicator" 1 "Button pressed" 0 "Button not pressed" ;
VAL_ 2365402110 Joystick6Button15PressedStatus 3 "Not Available" 2 "Error Indicator" 1 "Button pressed" 0 "Button not pressed" ;
VAL_ 2365402110 Joystick6Button16PressedStatus 3 "Not Available" 2 "Error Indicator" 1 "Button pressed" 0 "Button not pressed" ;
VAL_ 2365402110 Jystick6GripXAxisDetentPosStatus 3 "Not Available" 2 "Error Indicator" 1 "In the Detent Position" 0 "Not in the Detent Position" ;
VAL_ 2365402110 Jystick6GripYAxisDetentPosStatus 3 "Not Available" 2 "Error Indicator" 1 "In the Detent Position" 0 "Not in the Detent Position" ;
VAL_ 2365402110 Jystick6ThetaAxisDetentPosStatus 3 "Not Available" 2 "Error Indicator" 1 "In the Detent Position" 0 "Not in the Detent Position" ;
VAL_ 2365402110 Jystck6ThtAxsClckwsPstvPosStatus 3 "Not Available" 2 "Error Indicator" 1 "On positive side of Neutral" 0 "Not on Positive side of Neutral" ;
VAL_ 2365402110 Jystck6ThtAxsCntrClckwsNgtvPsStt 3 "Not Available" 2 "Error Indicator" 1 "On negative side of Neutral" 0 "Not on negative side of Neutral" ;
VAL_ 2365402110 Jystck6ThetaAxisNeutralPosStatus 3 "Not Available" 2 "Error Indicator" 1 "In Neutral Position" 0 "Not in Neutral Position" ;
VAL_ 2365402110 Jystck6GrpYAxsLvrFrwrdPstvPsStts 3 "Not Available" 2 "Error Indicator" 1 "On positive side of Neutral" 0 "Not on Positive side of Neutral" ;
VAL_ 2365402110 Jystck6GrpYAxsLvrBckNgtvPsStatus 3 "Not Available" 2 "Error Indicator" 1 "On negative side of Neutral" 0 "Not on negative side of Neutral" ;
VAL_ 2365402110 Jystck6GripYAxisNeutralPosStatus 3 "Not Available" 2 "Error Indicator" 1 "In Neutral Position" 0 "Not in Neutral Position" ;
VAL_ 2365402110 Jystck6GrpXAxsLvrRghtPstvPsSttus 3 "Not Available" 2 "Error Indicator" 1 "On positive side of Neutral" 0 "Not on Positive side of Neutral" ;
VAL_ 2365402110 Jystck6GrpXAxsLvrLftNgtvPsStatus 3 "Not Available" 2 "Error Indicator" 1 "On negative side of Neutral" 0 "Not on negative side of Neutral" ;
VAL_ 2365402110 Jystck6GripXAxisNeutralPosStatus 3 "Not Available" 2 "Error Indicator" 1 "In Neutral Position" 0 "Not in Neutral Position" ;
VAL_ 2365402622 Joystick5Button13PressedStatus 3 "Not Available" 2 "Error Indicator" 1 "Button pressed" 0 "Button not pressed" ;
VAL_ 2365402622 Joystick5Button14PressedStatus 3 "Not Available" 2 "Error Indicator" 1 "Button pressed" 0 "Button not pressed" ;
VAL_ 2365402622 Joystick5Button15PressedStatus 3 "Not Available" 2 "Error Indicator" 1 "Button pressed" 0 "Button not pressed" ;
VAL_ 2365402622 Joystick5Button16PressedStatus 3 "Not Available" 2 "Error Indicator" 1 "Button pressed" 0 "Button not pressed" ;
VAL_ 2365402622 Jystick5GripXAxisDetentPosStatus 3 "Not Available" 2 "Error Indicator" 1 "In the Detent Position" 0 "Not in the Detent Position" ;
VAL_ 2365402622 Jystick5GripYAxisDetentPosStatus 3 "Not Available" 2 "Error Indicator" 1 "In the Detent Position" 0 "Not in the Detent Position" ;
VAL_ 2365402622 Jystick5ThetaAxisDetentPosStatus 3 "Not Available" 2 "Error Indicator" 1 "In the Detent Position" 0 "Not in the Detent Position" ;
VAL_ 2365402622 Jystck5ThtAxsClckwsPstvPosStatus 3 "Not Available" 2 "Error Indicator" 1 "On positive side of Neutral" 0 "Not on Positive side of Neutral" ;
VAL_ 2365402622 Jystck5ThtAxsCntrClckwsNgtvPsStt 3 "Not Available" 2 "Error Indicator" 1 "On negative side of Neutral" 0 "Not on negative side of Neutral" ;
VAL_ 2365402622 Jystck5ThetaAxisNeutralPosStatus 3 "Not Available" 2 "Error Indicator" 1 "In Neutral Position" 0 "Not in Neutral Position" ;
VAL_ 2365402622 Jystck5GrpYAxsLvrFrwrdPstvPsStts 3 "Not Available" 2 "Error Indicator" 1 "On positive side of Neutral" 0 "Not on Positive side of Neutral" ;
VAL_ 2365402622 Jystck5GrpYAxsLvrBckNgtvPsStatus 3 "Not Available" 2 "Error Indicator" 1 "On negative side of Neutral" 0 "Not on negative side of Neutral" ;
VAL_ 2365402622 Jystck5GripYAxisNeutralPosStatus 3 "Not Available" 2 "Error Indicator" 1 "In Neutral Position" 0 "Not in Neutral Position" ;
VAL_ 2365402622 Jystck5GrpXAxsLvrRghtPstvPsSttus 3 "Not Available" 2 "Error Indicator" 1 "On positive side of Neutral" 0 "Not on Positive side of Neutral" ;
VAL_ 2365402622 Jystck5GrpXAxsLvrLftNgtvPsStatus 3 "Not Available" 2 "Error Indicator" 1 "On negative side of Neutral" 0 "Not on negative side of Neutral" ;
VAL_ 2365402622 Jystck5GripXAxisNeutralPosStatus 3 "Not Available" 2 "Error Indicator" 1 "In Neutral Position" 0 "Not in Neutral Position" ;
VAL_ 2365403134 Joystick4Button13PressedStatus 3 "Not Available" 2 "Error Indicator" 1 "Button pressed" 0 "Button not pressed" ;
VAL_ 2365403134 Joystick4Button14PressedStatus 3 "Not Available" 2 "Error Indicator" 1 "Button pressed" 0 "Button not pressed" ;
VAL_ 2365403134 Joystick4Button15PressedStatus 3 "Not Available" 2 "Error Indicator" 1 "Button pressed" 0 "Button not pressed" ;
VAL_ 2365403134 Joystick4Button16PressedStatus 3 "Not Available" 2 "Error Indicator" 1 "Button pressed" 0 "Button not pressed" ;
VAL_ 2365403134 Jystick4GripXAxisDetentPosStatus 3 "Not Available" 2 "Error Indicator" 1 "In the Detent Position" 0 "Not in the Detent Position" ;
VAL_ 2365403134 Jystick4GripYAxisDetentPosStatus 3 "Not Available" 2 "Error Indicator" 1 "In the Detent Position" 0 "Not in the Detent Position" ;
VAL_ 2365403134 Jystick4ThetaAxisDetentPosStatus 3 "Not Available" 2 "Error Indicator" 1 "In the Detent Position" 0 "Not in the Detent Position" ;
VAL_ 2365403134 Jystck4ThtAxsClckwsPstvPosStatus 3 "Not Available" 2 "Error Indicator" 1 "On positive side of Neutral" 0 "Not on Positive side of Neutral" ;
VAL_ 2365403134 Jystck4ThtAxsCntrClckwsNgtvPsStt 3 "Not Available" 2 "Error Indicator" 1 "On negative side of Neutral" 0 "Not on negative side of Neutral" ;
VAL_ 2365403134 Jystck4ThetaAxisNeutralPosStatus 3 "Not Available" 2 "Error Indicator" 1 "In Neutral Position" 0 "Not in Neutral Position" ;
VAL_ 2365403134 Jystck4GrpYAxsLvrFrwrdPstvPsStts 3 "Not Available" 2 "Error Indicator" 1 "On positive side of Neutral" 0 "Not on Positive side of Neutral" ;
VAL_ 2365403134 Jystck4GrpYAxsLvrBckNgtvPsStatus 3 "Not Available" 2 "Error Indicator" 1 "On negative side of Neutral" 0 "Not on negative side of Neutral" ;
VAL_ 2365403134 Jystck4GripYAxisNeutralPosStatus 3 "Not Available" 2 "Error Indicator" 1 "In Neutral Position" 0 "Not in Neutral Position" ;
VAL_ 2365403134 Jystck4GrpXAxsLvrRghtPstvPsSttus 3 "Not Available" 2 "Error Indicator" 1 "On positive side of Neutral" 0 "Not on Positive side of Neutral" ;
VAL_ 2365403134 Jystck4GrpXAxsLvrLftNgtvPsStatus 3 "Not Available" 2 "Error Indicator" 1 "On negative side of Neutral" 0 "Not on negative side of Neutral" ;
VAL_ 2365403134 Jystck4GripXAxisNeutralPosStatus 3 "Not Available" 2 "Error Indicator" 1 "In Neutral Position" 0 "Not in Neutral Position" ;
VAL_ 2365400062 Joystick10Button13PressedStatus 3 "Not Available" 2 "Error Indicator" 1 "Button pressed" 0 "Button not pressed" ;
VAL_ 2365400062 Joystick10Button14PressedStatus 3 "Not Available" 2 "Error Indicator" 1 "Button pressed" 0 "Button not pressed" ;
VAL_ 2365400062 Joystick10Button15PressedStatus 3 "Not Available" 2 "Error Indicator" 1 "Button pressed" 0 "Button not pressed" ;
VAL_ 2365400062 Joystick10Button16PressedStatus 3 "Not Available" 2 "Error Indicator" 1 "Button pressed" 0 "Button not pressed" ;
VAL_ 2365400062 Jystck10GripXAxisDetentPosStatus 3 "Not Available" 2 "Error Indicator" 1 "In the Detent Position" 0 "Not in the Detent Position" ;
VAL_ 2365400062 Jystck10GripYAxisDetentPosStatus 3 "Not Available" 2 "Error Indicator" 1 "In the Detent Position" 0 "Not in the Detent Position" ;
VAL_ 2365400062 Jystck10ThetaAxisDetentPosStatus 3 "Not Available" 2 "Error Indicator" 1 "In the Detent Position" 0 "Not in the Detent Position" ;
VAL_ 2365400062 Jystck10ThtAxsClckwsPstvPsStatus 3 "Not Available" 2 "Error Indicator" 1 "On positive side of Neutral" 0 "Not on Positive side of Neutral" ;
VAL_ 2365400062 Jystck10ThtAxsCntrClckwsNgtvPsSt 3 "Not Available" 2 "Error Indicator" 1 "On negative side of Neutral" 0 "Not on negative side of Neutral" ;
VAL_ 2365400062 Jystck10ThtaAxisNeutralPosStatus 3 "Not Available" 2 "Error Indicator" 1 "In Neutral Position" 0 "Not in Neutral Position" ;
VAL_ 2365400062 Jystck10GrpYAxsLvrFrwrdPstvPsStt 3 "Not Available" 2 "Error Indicator" 1 "On positive side of Neutral" 0 "Not on Positive side of Neutral" ;
VAL_ 2365400062 Jystck10GrpYAxsLvrBckNgtvPsSttus 3 "Not Available" 2 "Error Indicator" 1 "On negative side of Neutral" 0 "Not on negative side of Neutral" ;
VAL_ 2365400062 Jystck10GrpYAxisNeutralPosStatus 3 "Not Available" 2 "Error Indicator" 1 "In Neutral Position" 0 "Not in Neutral Position" ;
VAL_ 2365400062 Jystck10GrpXAxsLvrRghtPstvPsStts 3 "Not Available" 2 "Error Indicator" 1 "On positive side of Neutral" 0 "Not on Positive side of Neutral" ;
VAL_ 2365400062 Jystck10GrpXAxsLvrLftNgtvPsSttus 3 "Not Available" 2 "Error Indicator" 1 "On negative side of Neutral" 0 "Not on negative side of Neutral" ;
VAL_ 2365400062 Jystck10GrpXAxisNeutralPosStatus 3 "Not Available" 2 "Error Indicator" 1 "In Neutral Position" 0 "Not in Neutral Position" ;
VAL_ 2566713598 FuelTankTransferPump 3 "Not available" 2 "Error" 1 "On" 0 "Off" ;
VAL_ 2566749438 ActiveRegenInhibitedDueThresher 3 "Not available" 2 "Reserved" 1 "Inhibited" 0 "Not inhibited" ;
VAL_ 2566749438 ActiveRegenAvailabilityStatus 3 "Not Available" 2 "Reserved" 1 "Ready for initiation" 0 "Not ready for initiation" ;
VAL_ 2566749438 DslPrtcltFltrActvRgnrtnInhbt5629 3 "not available" 2 "reserved for SAE assignment" 1 "inhibited" 0 "not inhibited" ;
VAL_ 2566749438 A1DPFCondNotMetForActiveRegen 3 "not available" 2 "reserved for SAE assignment" 1 "active DPF regeneration inhibited" 0 "active DPF regeneration not inhibited" ;
VAL_ 2566749438 HydrocarbonDoserPurgingEnable 3 "Not available" 2 "Purging enabled, urgent" 1 "Purging enabled, less urgent" 0 "Purging not enabled" ;
VAL_ 2566749438 DslPrtcltFltrActvRgnrtnFrcdSttus 7 "not available" 6 "Reserved for SAE Assignment" 5 "Reserved for SAE Assignment" 4 "Reserved for SAE Assignment" 3 "Reserved for SAE Assignment" 2 "Active, Forced by Service Tool" 1 "Active, Forced by Switch" 0 "Not Active" ;
VAL_ 2566749438 ExhaustSystemHighTempLampCmd 7 "not available" 6 "reserved for SAE assignment" 5 "reserved for SAE assignment" 4 "reserved for SAE assignment" 3 "reserved for SAE assignment" 2 "reserved for SAE assignment" 1 "On" 0 "Off" ;
VAL_ 2566749438 DslPrtcltFltrAtmtcActvRgnrtnIntt 3 "not available" 2 "reserved for SAE assignment" 1 "enabled" 0 "not enabled" ;
VAL_ 2566749438 DslPrtcltFltrActvRgnrtnInhbt3717 3 "not available" 2 "reserved for SAE assignment" 1 "inhibited" 0 "not inhibited" ;
VAL_ 2566749438 DslPrtcltFltrActvRgnrtnInhbtdDTE 3 "not available" 2 "reserved for SAE assignment" 1 "inhibited" 0 "not inhibited" ;
VAL_ 2566749438 DslPrtcltFltrActvRgnrtnInhbt3715 3 "not available" 2 "reserved for SAE assignment" 1 "inhibited" 0 "not inhibited" ;
VAL_ 2566749438 DslPrtcltFltrActvRgnrtnInhbtdDTT 3 "not available" 2 "reserved for SAE assignment" 1 "inhibited" 0 "not inhibited" ;
VAL_ 2566749438 DslPrtcltFltrActvRgnrtnInhbt3713 3 "not available" 2 "reserved for SAE assignment" 1 "inhibited" 0 "not inhibited" ;
VAL_ 2566749438 DslPrtcltFltrActvRgnrtnInhbt3712 3 "not available" 2 "reserved for SAE assignment" 1 "inhibited" 0 "not inhibited" ;
VAL_ 2566749438 DslPrtcltFltrActvRgnrtnInhbtdDTL 3 "not available" 2 "reserved for SAE assignment" 1 "inhibited" 0 "not inhibited" ;
VAL_ 2566749438 DslPrtcltFltrActvRgnrtnInhbt3710 3 "not available" 2 "reserved for SAE assignment" 1 "inhibited" 0 "not inhibited" ;
VAL_ 2566749438 DslPrtcltFltrActvRgnrtnInhbtdDTV 3 "not available" 2 "reserved for SAE assignment" 1 "inhibited" 0 "not inhibited" ;
VAL_ 2566749438 DslPrtcltFltrActvRgnrtnInhbtdDTO 3 "not available" 2 "reserved for SAE assignment" 1 "inhibited" 0 "not inhibited" ;
VAL_ 2566749438 DslPrtcltFltrActvRgnrtnInhbtdDTA 3 "not available" 2 "reserved for SAE assignment" 1 "inhibited" 0 "not inhibited" ;
VAL_ 2566749438 DslPrtcltFltrActvRgnrtnInhbtdDTP 3 "not available" 2 "reserved for SAE assignment" 1 "inhibited" 0 "not inhibited" ;
VAL_ 2566749438 DslPrtcltFltrActvRgnrtnInhbtdDTS 3 "not available" 2 "reserved for SAE assignment" 1 "inhibited" 0 "not inhibited" ;
VAL_ 2566749438 DslPrtcltFltrActvRgnrtnInhbtdDTC 3 "not available" 2 "reserved for SAE assignment" 1 "inhibited" 0 "not inhibited" ;
VAL_ 2566749438 DslPrtcltFltrActvRgnrtnInhbtdDTI 3 "not available" 2 "reserved for SAE assignment" 1 "inhibited" 0 "not inhibited" ;
VAL_ 2566749438 DslPrtcltFltrActvRgnrtnInhbtdStt 3 "not available" 2 "reserved for SAE assignment" 1 "inhibited" 0 "not inhibited" ;
VAL_ 2566749438 AFTDPFSt 7 "not available" 6 "reserved for SAE assignment" 5 "reserved for SAE assignment" 4 "reserved for SAE assignment" 3 "Regeneration needed, highest level" 2 "Regeneration needed, moderate level" 1 "Regeneration needed, lowest level" 0 "Regeneration not needed" ;
VAL_ 2566749438 AFTDPFActiveRegenSt 3 "not available" 2 "regeneration needed" 1 "active" 0 "not active" ;
VAL_ 2566749438 AFTDPFPassiveRegenSt 3 "not available" 2 "reserved for SAE assignment" 1 "active" 0 "not active" ;
VAL_ 2566749438 DieselParticulateFilterLampCmd 7 "not available" 6 "reserved for SAE assignment" 5 "On, very fast blink" 4 "On, fast blink" 3 "reserved for SAE assignment" 2 "reserved for SAE assignment" 1 "On, solid" 0 "Off" ;
VAL_ 2566718718 OptionalLamp6Data 3 "Not available" 2 "Error" 1 "Lamp activated" 0 "Lamp deactivated" ;
VAL_ 2566718718 OptionalLamp5Data 3 "Not available" 2 "Error" 1 "Lamp activated" 0 "Lamp deactivated" ;
VAL_ 2566718718 OptionalLamp4Data 3 "Not available" 2 "Error" 1 "Lamp activated" 0 "Lamp deactivated" ;
VAL_ 2566718718 OptionalLamp3Data 3 "Not available" 2 "Error" 1 "Lamp activated" 0 "Lamp deactivated" ;
VAL_ 2566718718 OptionalLamp2Data 3 "Not available" 2 "Error" 1 "Lamp activated" 0 "Lamp deactivated" ;
VAL_ 2566718718 OptionalLamp1Data 3 "Not available" 2 "Error" 1 "Lamp activated" 0 "Lamp deactivated" ;
VAL_ 2566718718 SecondAirPressLowLamp 3 "Not available" 2 "Error" 1 "Lamp activated" 0 "Lamp deactivated" ;
VAL_ 2566718718 PrimaryAirPressLowLamp 3 "Not available" 2 "Error" 1 "Lamp activated" 0 "Lamp deactivated" ;
VAL_ 2566718718 VehLimPerformanceModeLamp 3 "Not available" 2 "Error" 1 "Lamp activated" 0 "Lamp deactivated" ;
VAL_ 2566718718 HillHolderLampData 3 "Not Available" 2 "Error" 1 "Lamp activated" 0 "Lamp deactivated" ;
VAL_ 2566718718 VehicleBatteryChargingLampData 3 "Not available" 2 "Error" 1 "Lamp activated" 0 "Lamp deactivated" ;
VAL_ 2566718718 VehicleHVACRecirculationLampData 3 "Not available" 2 "Error" 1 "Lamp activated" 0 "Lamp deactivated" ;
VAL_ 2566718718 VehicleAirPressLowLampData 3 "Not available" 2 "Error" 1 "Lamp activated" 0 "Lamp deactivated" ;
VAL_ 2566718718 VehicleFuelLevelLowLampData 3 "Not available" 2 "Error" 1 "Lamp activated" 0 "Lamp deactivated" ;
VAL_ 2566718718 VehicleBatteryVoltageLowLampData 3 "Not available" 2 "Error" 1 "Lamp activated" 0 "Lamp deactivated" ;
VAL_ 2566718974 EngSvcLamp 3 "Not available" 2 "Error" 1 "Lamp activated" 0 "Lamp deactivated" ;
VAL_ 2566718974 EngAirShutoffLamp 3 "Not available" 2 "Error" 1 "Lamp Activated" 0 "Lamp Deactivated" ;
VAL_ 2566718974 EngIntercoolerTempHiLamp 3 "Not available" 2 "Error" 1 "Lamp activated" 0 "Lamp deactivated" ;
VAL_ 2566718974 EngFuelTempHiLamp 3 "Not available" 2 "Error" 1 "Lamp activated" 0 "Lamp deactivated" ;
VAL_ 2566718974 EngOilTempHiLamp 3 "Not available" 2 "Error" 1 "Lamp activated" 0 "Lamp deactivated" ;
VAL_ 2566718974 EngStopStartEnabledLamp 3 "Not available" 2 "Error" 1 "Lamp activated" 0 "Lamp deactivated" ;
VAL_ 2566718974 EngStopStartAutoStartFailedLamp 3 "Not available" 2 "Error" 1 "Lamp activated" 0 "Lamp deactivated" ;
VAL_ 2566718974 EngStopStartAutoStopActiveLamp 3 "Not available" 2 "Error" 1 "Lamp activated" 0 "Lamp deactivated" ;
VAL_ 2566718974 VhclAcclerationRateLimitLampData 3 "Not available" 2 "Error" 1 "Lamp activated" 0 "Lamp deactivated" ;
VAL_ 2566718974 EngSpeedVeryHighLampData 3 "Not available" 2 "Error" 1 "Lamp Activated" 0 "Lamp Deactivated" ;
VAL_ 2566718974 EngSpeedHighLampData 0 "Lamp Deactivated" 3 "Not available" 2 "Error" 1 "Lamp Activated" ;
VAL_ 2566718974 EngCtrlMdule3ReadyForUseLampData 3 "Not Available" 2 "Error" 1 "Lamp activated" 0 "Lamp deactivated" ;
VAL_ 2566718974 EngCtrlMdule2ReadyForUseLampData 3 "Not Available" 2 "Error" 1 "Lamp activated" 0 "Lamp deactivated" ;
VAL_ 2566718974 EngCtrlMdule1ReadyForUseLampData 3 "Not Available" 2 "Error" 1 "Lamp activated" 0 "Lamp deactivated" ;
VAL_ 2566718974 EngWaitToStartLampData 3 "Not available" 2 "Error" 1 "Lamp actived" 0 "Lamp deactived" ;
VAL_ 2566718974 EngFuelFilterRestrictedLampData 3 "Not available" 2 "Error" 1 "Lamp activated" 0 "Lamp deactivated" ;
VAL_ 2566718974 EngAirFilterRestrictionLampData 3 "Not available" 2 "Error" 1 "Lamp activated" 0 "Lamp deactivated" ;
VAL_ 2566718974 EngIdleManagementActiveLampData 3 "Not available" 2 "Error" 1 "Lamp activated" 0 "Lamp deactivated" ;
VAL_ 2566718974 EngCoolantLevelLowLampData 3 "Not available" 2 "Error" 1 "Lamp activated" 0 "Lamp deactivated" ;
VAL_ 2566718974 EngCoolantTempHighLampData 3 "Not available" 2 "Error" 1 "Lamp activated" 0 "Lamp deactivated" ;
VAL_ 2566718974 EngOilPressLowLampData 3 "Not available" 2 "Error" 1 "Lamp activated" 0 "Lamp deactivated" ;
VAL_ 2566718974 CmprssnBrkEnblSwtchIndctrLmpData 3 "Not available" 2 "Error" 1 "Lamp activated" 0 "Lamp deactivated" ;
VAL_ 2566718974 EngBrakeActiveLampData 3 "Not available" 2 "Error" 1 "Lamp activated" 0 "Lamp deactivated" ;
VAL_ 2566718974 OBDMalfunctionIndicatorLampData 3 "Not available" 2 "Error" 1 "Lamp activated" 0 "Lamp deactivated" ;
VAL_ 2566718974 EngRedStopLampData 3 "Not available" 2 "Error" 1 "Lamp activated" 0 "Lamp deactivated" ;
VAL_ 2566718974 EngAmberWarningLampData 3 "Not available" 2 "Error" 1 "Lamp activated" 0 "Lamp deactivated" ;
VAL_ 2566718974 EngProtectLampData 3 "Not available" 2 "Error" 1 "Lamp activated" 0 "Lamp deactivated" ;
VAL_ 2566719230 OptionalLamp6Cmd 3 "Not available" 2 "Reserved" 1 "Lamp On" 0 "Lamp Off" ;
VAL_ 2566719230 OptionalLamp5Cmd 3 "Not available" 2 "Reserved" 1 "Lamp On" 0 "Lamp Off" ;
VAL_ 2566719230 OptionalLamp4Cmd 3 "Not available" 2 "Reserved" 1 "Lamp On" 0 "Lamp Off" ;
VAL_ 2566719230 OptionalLamp3Cmd 3 "Not available" 2 "Reserved" 1 "Lamp On" 0 "Lamp Off" ;
VAL_ 2566719230 OptionalLamp2Cmd 3 "Not available" 2 "Reserved" 1 "Lamp On" 0 "Lamp Off" ;
VAL_ 2566719230 OptionalLamp1Cmd 3 "Not available" 2 "Reserved" 1 "Lamp On" 0 "Lamp Off" ;
VAL_ 2566719230 SecondAirPressLowLamp 3 "Not available" 2 "Reserved" 1 "Lamp On" 0 "Lamp Off" ;
VAL_ 2566719230 PrimaryAirPressLowLamp 3 "Not available" 2 "Reserved" 1 "Lamp On" 0 "Lamp Off" ;
VAL_ 2566719230 VehLimPerformanceModeLamp 3 "Not available" 2 "Reserved" 1 "Lamp On" 0 "Lamp Off" ;
VAL_ 2566719230 HillHolderLampCmd 3 "Not available" 2 "Lamp Flash" 1 "Lamp On" 0 "Lamp Off" ;
VAL_ 2566719230 VehicleBatteryChargingLampCmd 3 "Not available" 2 "Reserved" 1 "Lamp On" 0 "Lamp Off" ;
VAL_ 2566719230 VehicleHVACRecirculationLampCmd 3 "Not available" 2 "Reserved" 1 "Lamp On" 0 "Lamp Off" ;
VAL_ 2566719230 VehicleAirPressLowLampCmd 3 "Not available" 2 "Reserved" 1 "Lamp On" 0 "Lamp Off" ;
VAL_ 2566719230 VehicleFuelLevelLowLampCmd 3 "Not available" 2 "Reserved" 1 "Lamp On" 0 "Lamp Off" ;
VAL_ 2566719230 VehicleBatteryVoltageLowLampCmd 3 "Not available" 2 "Reserved" 1 "Lamp On" 0 "Lamp Off" ;
VAL_ 2560818942 FailureModeIdentifier1 31 "Not available" 19 "Received network data in error" 18 "Below normal (moderately severe)" 17 "Below normal (least severe)" 16 "Above normal (moderately severe)" 15 "Above normal (least severe)" 14 "Special intstructions" 13 "Out of calibration" 12 "Bad intelligent device" 11 "Root cause not known" 10 "Abnormal rate of change" 9 "Abnormal update rate" 8 "Abnormal frequency" 7 "Mechanical system not responding" 6 "Current above normal" 5 "Current below normal" 4 "Voltage below normal" 3 "Voltage above normal" 2 "Data erratic" 1 "Below normal (most severe)" 0 "Above normal (most severe)" ;
VAL_ 2561212158 TextDisplayInstructions 15 "Not applicable" 6 "Blink substring" 5 "Highlight substring" 4 "Overwrite substring" 3 "Overwrite display" 2 "Append at end of display" 1 "Hold display" 0 "Clear display" ;
VAL_ 2566746366 RetractStatusOfRamp5 3 "not available" 2 "error" 1 "ramp extended" 0 "ramp retracted" ;
VAL_ 2566746366 RetractStatusOfRamp4 3 "not available" 2 "error" 1 "ramp extended" 0 "ramp retracted" ;
VAL_ 2566746366 MovementStatusOfRamp5 3 "not available" 2 "error" 1 "ramp being moved" 0 "ramp not being moved" ;
VAL_ 2566746366 MovementStatusOfRamp4 3 "not available" 2 "error" 1 "ramp being moved" 0 "ramp not being moved" ;
VAL_ 2566746366 EnableStatusOfRamp5 3 "not available" 2 "error" 1 "ramp enabled" 0 "ramp disabled" ;
VAL_ 2566746366 EnableStatusOfRamp4 3 "not available" 2 "error" 1 "ramp enabled" 0 "ramp disabled" ;
VAL_ 2566746366 MovementStatusOfRamp3 3 "not available" 2 "error" 1 "ramp being moved" 0 "ramp not being moved" ;
VAL_ 2566746366 EnableStatusOfRamp3 3 "not available" 2 "error" 1 "ramp enabled" 0 "ramp disabled" ;
VAL_ 2566746366 RetractStatusOfRamp3 3 "not available" 2 "error" 1 "ramp extended" 0 "ramp retracted" ;
VAL_ 2566746366 MovementStatusOfRamp2 3 "not available" 2 "error" 1 "ramp being moved" 0 "ramp not being moved" ;
VAL_ 2566746366 EnableStatusOfRamp2 3 "not available" 2 "error" 1 "ramp enabled" 0 "ramp disabled" ;
VAL_ 2566746366 RetractStatusOfRamp2 3 "not available" 2 "error" 1 "ramp extended" 0 "ramp retracted" ;
VAL_ 2566746366 MovementStatusOfRamp1 3 "not available" 2 "error" 1 "ramp being moved" 0 "ramp not being moved" ;
VAL_ 2566746366 EnableStatusOfRamp1 3 "not available" 2 "error" 1 "ramp enabled" 0 "ramp disabled" ;
VAL_ 2566746366 RetractStatusOfRamp1 3 "not available" 2 "error" 1 "ramp extended" 0 "ramp retracted" ;
VAL_ 2566750206 TransIdleGovFuelingInhSupport 3 "Not supported" 2 "Reserved for future SAE use" 1 "Engine will respond to a 'Transmission Idle Governor Fueling Inhibit' command" 0 "Engine does not support the 'Transmission Idle Governor Fueling Inhibit' feature" ;
